VERSION ""

NS_ :

BS_:

BU_: WCM VPM VLM VKM UVM TIM TEST_TOOL_2 TEST_TOOL_1 TCP TCM TCCM3 TCCM STC SRR_SRR SRR_SLR SRR_RR SRR_RF SRR_LR_CR SRR_LF SIB SDM SCL SBZA_R SBZA_L SBM SADS RadioLow RSC RDCM PTM PDR PA NVM MTCM_R MTCM_L MSM_RR MSM_P MSM_LR MSM_D MSB2 MSB1 MRCM_R MRCM_L MFC LRR_HC LRR LIB1 IPC ICS_Info ICCM HVAC_FP_R HVAC_FP_F HUD_CAN HDLM FCM_LC FCM EPS EOCM_HCP2 EOCM_HCP1 EOCM ELM ECP_X1 ECP_MC ECP_E ECM EBCM DMS DEFC DCM CSM CMMb CMMa CGM BSM_MH BSM BCM ARS ARB APA AOS AMP ALC AHS AHL_AFL AGC

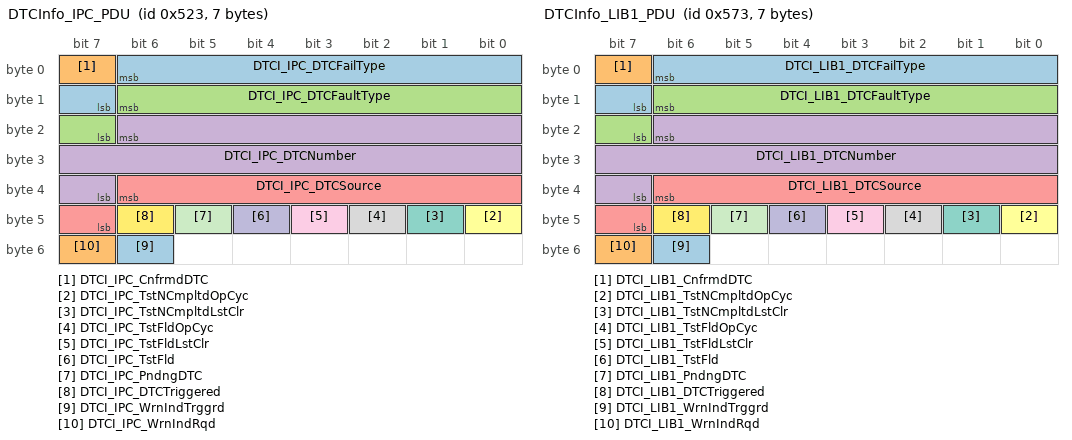
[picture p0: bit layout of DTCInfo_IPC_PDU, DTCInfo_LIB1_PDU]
BO_ 1315 DTCInfo_IPC_PDU: 7 IPC
 SG_ DTCI_IPC_DTCFailType : 6|8@0+ (1,0) [0|255] "" CSM,TCP
 SG_ DTCI_IPC_CnfrmdDTC : 7|1@0+ (1,0) [0|1] "" CSM,TCP
 SG_ DTCI_IPC_DTCFaultType : 14|8@0+ (1,0) [0|3] "" CSM,TCP
 SG_ DTCI_IPC_DTCNumber : 22|16@0+ (1,0) [0|65535] "" CSM,TCP
 SG_ DTCI_IPC_DTCSource : 38|8@0+ (1,0) [0|255] "" CGM,CSM,TCP
 SG_ DTCI_IPC_TstNCmpltdOpCyc : 40|1@0+ (1,0) [0|1] "" CSM,TCP
 SG_ DTCI_IPC_TstNCmpltdLstClr : 41|1@0+ (1,0) [0|1] "" CSM,TCP
 SG_ DTCI_IPC_TstFldOpCyc : 42|1@0+ (1,0) [0|1] "" CSM,TCP
 SG_ DTCI_IPC_TstFldLstClr : 43|1@0+ (1,0) [0|1] "" CSM,TCP
 SG_ DTCI_IPC_TstFld : 44|1@0+ (1,0) [0|1] "" CSM,TCP
 SG_ DTCI_IPC_PndngDTC : 45|1@0+ (1,0) [0|1] "" CSM,TCP
 SG_ DTCI_IPC_DTCTriggered : 46|1@0+ (1,0) [0|1] "" CSM,TCP
 SG_ DTCI_IPC_WrnIndTrggrd : 54|1@0+ (1,0) [0|1] "" CSM,TCP
 SG_ DTCI_IPC_WrnIndRqd : 55|1@0+ (1,0) [0|1] "" CSM,TCP

BO_ 1395 DTCInfo_LIB1_PDU: 7 CGM
 SG_ DTCI_LIB1_DTCFailType : 6|8@0+ (1,0) [0|255] "" CSM,TCP
 SG_ DTCI_LIB1_CnfrmdDTC : 7|1@0+ (1,0) [0|1] "" CSM,TCP
 SG_ DTCI_LIB1_DTCFaultType : 14|8@0+ (1,0) [0|3] "" CSM,TCP
 SG_ DTCI_LIB1_DTCNumber : 22|16@0+ (1,0) [0|65535] "" CSM,TCP
 SG_ DTCI_LIB1_DTCSource : 38|8@0+ (1,0) [0|255] "" CSM,TCP
 SG_ DTCI_LIB1_TstNCmpltdOpCyc : 40|1@0+ (1,0) [0|1] "" CSM,TCP
 SG_ DTCI_LIB1_TstNCmpltdLstClr : 41|1@0+ (1,0) [0|1] "" CSM,TCP
 SG_ DTCI_LIB1_TstFldOpCyc : 42|1@0+ (1,0) [0|1] "" CSM,TCP
 SG_ DTCI_LIB1_TstFldLstClr : 43|1@0+ (1,0) [0|1] "" CSM,TCP
 SG_ DTCI_LIB1_TstFld : 44|1@0+ (1,0) [0|1] "" CSM,TCP
 SG_ DTCI_LIB1_PndngDTC : 45|1@0+ (1,0) [0|1] "" CSM,TCP
 SG_ DTCI_LIB1_DTCTriggered : 46|1@0+ (1,0) [0|1] "" CSM,TCP
 SG_ DTCI_LIB1_WrnIndTrggrd : 54|1@0+ (1,0) [0|1] "" CSM,TCP
 SG_ DTCI_LIB1_WrnIndRqd : 55|1@0+ (1,0) [0|1] "" CSM,TCP

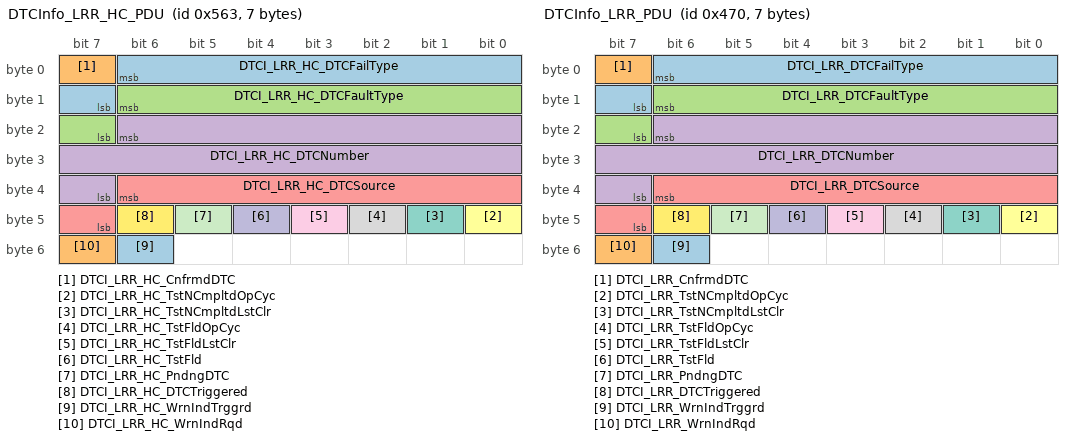
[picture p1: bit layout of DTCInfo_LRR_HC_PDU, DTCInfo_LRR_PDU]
BO_ 1379 DTCInfo_LRR_HC_PDU: 7 CGM
 SG_ DTCI_LRR_HC_DTCFailType : 6|8@0+ (1,0) [0|255] "" CSM,TCP
 SG_ DTCI_LRR_HC_CnfrmdDTC : 7|1@0+ (1,0) [0|1] "" CSM,TCP
 SG_ DTCI_LRR_HC_DTCFaultType : 14|8@0+ (1,0) [0|3] "" CSM,TCP
 SG_ DTCI_LRR_HC_DTCNumber : 22|16@0+ (1,0) [0|65535] "" CSM,TCP
 SG_ DTCI_LRR_HC_DTCSource : 38|8@0+ (1,0) [0|255] "" CSM,TCP
 SG_ DTCI_LRR_HC_TstNCmpltdOpCyc : 40|1@0+ (1,0) [0|1] "" CSM,TCP
 SG_ DTCI_LRR_HC_TstNCmpltdLstClr : 41|1@0+ (1,0) [0|1] "" CSM,TCP
 SG_ DTCI_LRR_HC_TstFldOpCyc : 42|1@0+ (1,0) [0|1] "" CSM,TCP
 SG_ DTCI_LRR_HC_TstFldLstClr : 43|1@0+ (1,0) [0|1] "" CSM,TCP
 SG_ DTCI_LRR_HC_TstFld : 44|1@0+ (1,0) [0|1] "" CSM,TCP
 SG_ DTCI_LRR_HC_PndngDTC : 45|1@0+ (1,0) [0|1] "" CSM,TCP
 SG_ DTCI_LRR_HC_DTCTriggered : 46|1@0+ (1,0) [0|1] "" CSM,TCP
 SG_ DTCI_LRR_HC_WrnIndTrggrd : 54|1@0+ (1,0) [0|1] "" TCP
 SG_ DTCI_LRR_HC_WrnIndRqd : 55|1@0+ (1,0) [0|1] "" TCP

BO_ 1136 DTCInfo_LRR_PDU: 7 CGM
 SG_ DTCI_LRR_DTCFailType : 6|8@0+ (1,0) [0|255] "" CSM,TCP
 SG_ DTCI_LRR_CnfrmdDTC : 7|1@0+ (1,0) [0|1] "" CSM,TCP
 SG_ DTCI_LRR_DTCFaultType : 14|8@0+ (1,0) [0|3] "" CSM,TCP
 SG_ DTCI_LRR_DTCNumber : 22|16@0+ (1,0) [0|65535] "" CSM,TCP
 SG_ DTCI_LRR_DTCSource : 38|8@0+ (1,0) [0|255] "" CSM,TCP
 SG_ DTCI_LRR_TstNCmpltdOpCyc : 40|1@0+ (1,0) [0|1] "" CSM,TCP
 SG_ DTCI_LRR_TstNCmpltdLstClr : 41|1@0+ (1,0) [0|1] "" CSM,TCP
 SG_ DTCI_LRR_TstFldOpCyc : 42|1@0+ (1,0) [0|1] "" CSM,TCP
 SG_ DTCI_LRR_TstFldLstClr : 43|1@0+ (1,0) [0|1] "" CSM,TCP
 SG_ DTCI_LRR_TstFld : 44|1@0+ (1,0) [0|1] "" CSM,TCP
 SG_ DTCI_LRR_PndngDTC : 45|1@0+ (1,0) [0|1] "" CSM,TCP
 SG_ DTCI_LRR_DTCTriggered : 46|1@0+ (1,0) [0|1] "" CSM,TCP
 SG_ DTCI_LRR_WrnIndTrggrd : 54|1@0+ (1,0) [0|1] "" CSM,TCP
 SG_ DTCI_LRR_WrnIndRqd : 55|1@0+ (1,0) [0|1] "" CSM,TCP

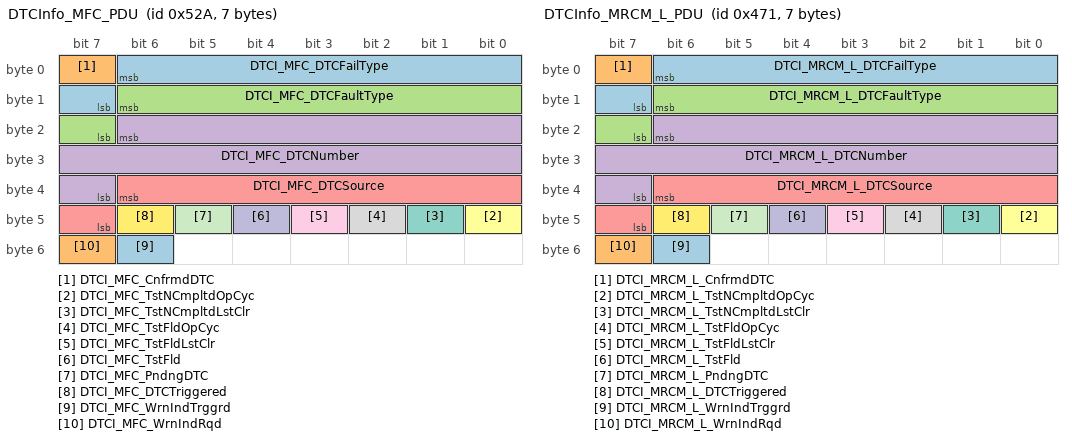
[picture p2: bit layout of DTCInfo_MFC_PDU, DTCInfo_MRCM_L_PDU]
BO_ 1322 DTCInfo_MFC_PDU: 7 MFC
 SG_ DTCI_MFC_DTCFailType : 6|8@0+ (1,0) [0|255] "" CSM,TCP
 SG_ DTCI_MFC_CnfrmdDTC : 7|1@0+ (1,0) [0|1] "" CSM,TCP
 SG_ DTCI_MFC_DTCFaultType : 14|8@0+ (1,0) [0|3] "" CSM,TCP
 SG_ DTCI_MFC_DTCNumber : 22|16@0+ (1,0) [0|65535] "" CSM,TCP
 SG_ DTCI_MFC_DTCSource : 38|8@0+ (1,0) [0|255] "" CGM,CSM,TCP
 SG_ DTCI_MFC_TstNCmpltdOpCyc : 40|1@0+ (1,0) [0|1] "" CSM,TCP
 SG_ DTCI_MFC_TstNCmpltdLstClr : 41|1@0+ (1,0) [0|1] "" CSM,TCP
 SG_ DTCI_MFC_TstFldOpCyc : 42|1@0+ (1,0) [0|1] "" CSM,TCP
 SG_ DTCI_MFC_TstFldLstClr : 43|1@0+ (1,0) [0|1] "" CSM,TCP
 SG_ DTCI_MFC_TstFld : 44|1@0+ (1,0) [0|1] "" CSM,TCP
 SG_ DTCI_MFC_PndngDTC : 45|1@0+ (1,0) [0|1] "" CSM,TCP
 SG_ DTCI_MFC_DTCTriggered : 46|1@0+ (1,0) [0|1] "" CSM,TCP
 SG_ DTCI_MFC_WrnIndTrggrd : 54|1@0+ (1,0) [0|1] "" CSM,TCP
 SG_ DTCI_MFC_WrnIndRqd : 55|1@0+ (1,0) [0|1] "" CSM,TCP

BO_ 1137 DTCInfo_MRCM_L_PDU: 7 CGM
 SG_ DTCI_MRCM_L_DTCFailType : 6|8@0+ (1,0) [0|255] "" CSM,TCP
 SG_ DTCI_MRCM_L_CnfrmdDTC : 7|1@0+ (1,0) [0|1] "" CSM,TCP
 SG_ DTCI_MRCM_L_DTCFaultType : 14|8@0+ (1,0) [0|3] "" CSM,TCP
 SG_ DTCI_MRCM_L_DTCNumber : 22|16@0+ (1,0) [0|65535] "" CSM,TCP
 SG_ DTCI_MRCM_L_DTCSource : 38|8@0+ (1,0) [0|255] "" CSM,TCP
 SG_ DTCI_MRCM_L_TstNCmpltdOpCyc : 40|1@0+ (1,0) [0|1] "" CSM,TCP
 SG_ DTCI_MRCM_L_TstNCmpltdLstClr : 41|1@0+ (1,0) [0|1] "" CSM,TCP
 SG_ DTCI_MRCM_L_TstFldOpCyc : 42|1@0+ (1,0) [0|1] "" CSM,TCP
 SG_ DTCI_MRCM_L_TstFldLstClr : 43|1@0+ (1,0) [0|1] "" CSM,TCP
 SG_ DTCI_MRCM_L_TstFld : 44|1@0+ (1,0) [0|1] "" CSM,TCP
 SG_ DTCI_MRCM_L_PndngDTC : 45|1@0+ (1,0) [0|1] "" CSM,TCP
 SG_ DTCI_MRCM_L_DTCTriggered : 46|1@0+ (1,0) [0|1] "" CSM,TCP
 SG_ DTCI_MRCM_L_WrnIndTrggrd : 54|1@0+ (1,0) [0|1] "" CSM,TCP
 SG_ DTCI_MRCM_L_WrnIndRqd : 55|1@0+ (1,0) [0|1] "" CSM,TCP

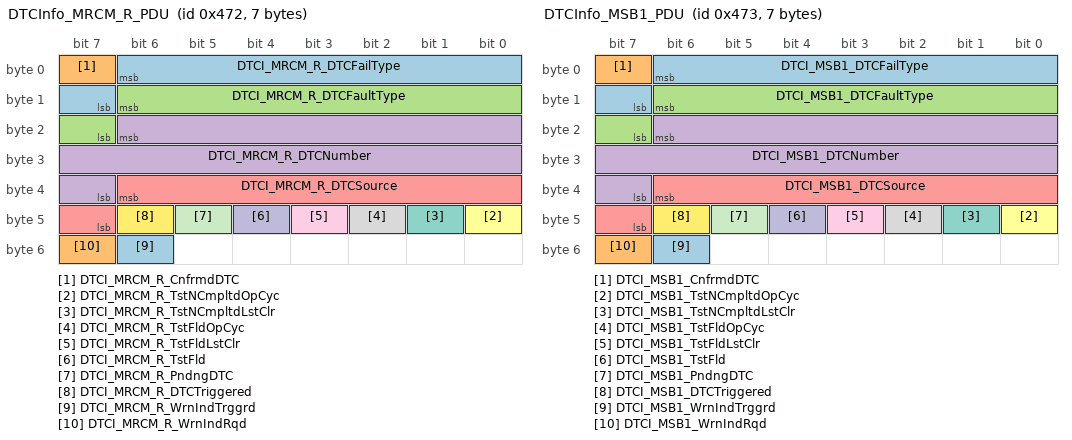
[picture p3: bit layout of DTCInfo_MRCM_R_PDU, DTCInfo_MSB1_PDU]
BO_ 1138 DTCInfo_MRCM_R_PDU: 7 CGM
 SG_ DTCI_MRCM_R_DTCFailType : 6|8@0+ (1,0) [0|255] "" CSM,TCP
 SG_ DTCI_MRCM_R_CnfrmdDTC : 7|1@0+ (1,0) [0|1] "" CSM,TCP
 SG_ DTCI_MRCM_R_DTCFaultType : 14|8@0+ (1,0) [0|3] "" CSM,TCP
 SG_ DTCI_MRCM_R_DTCNumber : 22|16@0+ (1,0) [0|65535] "" CSM,TCP
 SG_ DTCI_MRCM_R_DTCSource : 38|8@0+ (1,0) [0|255] "" CSM,TCP
 SG_ DTCI_MRCM_R_TstNCmpltdOpCyc : 40|1@0+ (1,0) [0|1] "" CSM,TCP
 SG_ DTCI_MRCM_R_TstNCmpltdLstClr : 41|1@0+ (1,0) [0|1] "" CSM,TCP
 SG_ DTCI_MRCM_R_TstFldOpCyc : 42|1@0+ (1,0) [0|1] "" CSM,TCP
 SG_ DTCI_MRCM_R_TstFldLstClr : 43|1@0+ (1,0) [0|1] "" CSM,TCP
 SG_ DTCI_MRCM_R_TstFld : 44|1@0+ (1,0) [0|1] "" CSM,TCP
 SG_ DTCI_MRCM_R_PndngDTC : 45|1@0+ (1,0) [0|1] "" CSM,TCP
 SG_ DTCI_MRCM_R_DTCTriggered : 46|1@0+ (1,0) [0|1] "" CSM,TCP
 SG_ DTCI_MRCM_R_WrnIndTrggrd : 54|1@0+ (1,0) [0|1] "" CSM,TCP
 SG_ DTCI_MRCM_R_WrnIndRqd : 55|1@0+ (1,0) [0|1] "" CSM,TCP

BO_ 1139 DTCInfo_MSB1_PDU: 7 CGM
 SG_ DTCI_MSB1_DTCFailType : 6|8@0+ (1,0) [0|255] "" CSM,TCP
 SG_ DTCI_MSB1_CnfrmdDTC : 7|1@0+ (1,0) [0|1] "" CSM,TCP
 SG_ DTCI_MSB1_DTCFaultType : 14|8@0+ (1,0) [0|3] "" CSM,TCP
 SG_ DTCI_MSB1_DTCNumber : 22|16@0+ (1,0) [0|65535] "" CSM,TCP
 SG_ DTCI_MSB1_DTCSource : 38|8@0+ (1,0) [0|255] "" CSM,TCP
 SG_ DTCI_MSB1_TstNCmpltdOpCyc : 40|1@0+ (1,0) [0|1] "" CSM,TCP
 SG_ DTCI_MSB1_TstNCmpltdLstClr : 41|1@0+ (1,0) [0|1] "" CSM,TCP
 SG_ DTCI_MSB1_TstFldOpCyc : 42|1@0+ (1,0) [0|1] "" CSM,TCP
 SG_ DTCI_MSB1_TstFldLstClr : 43|1@0+ (1,0) [0|1] "" CSM,TCP
 SG_ DTCI_MSB1_TstFld : 44|1@0+ (1,0) [0|1] "" CSM,TCP
 SG_ DTCI_MSB1_PndngDTC : 45|1@0+ (1,0) [0|1] "" CSM,TCP
 SG_ DTCI_MSB1_DTCTriggered : 46|1@0+ (1,0) [0|1] "" CSM,TCP
 SG_ DTCI_MSB1_WrnIndTrggrd : 54|1@0+ (1,0) [0|1] "" CSM,TCP
 SG_ DTCI_MSB1_WrnIndRqd : 55|1@0+ (1,0) [0|1] "" CSM,TCP

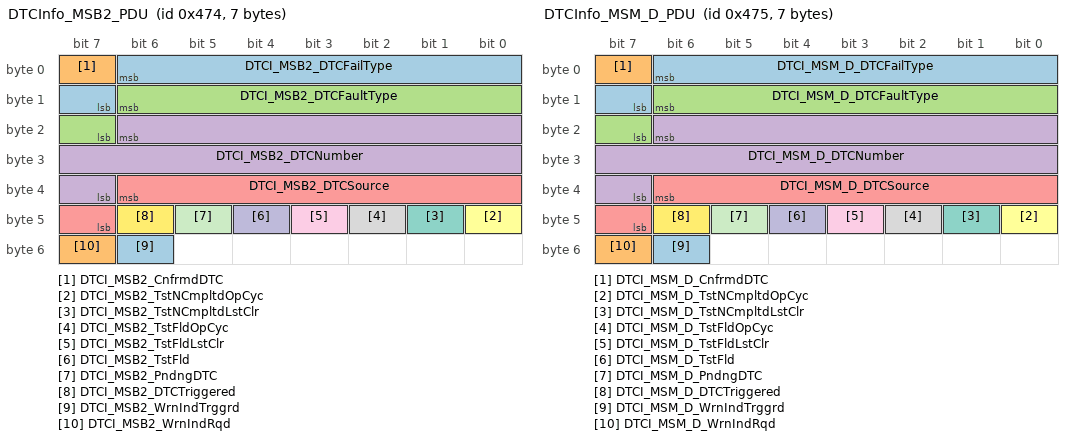
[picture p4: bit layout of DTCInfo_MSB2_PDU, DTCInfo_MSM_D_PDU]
BO_ 1140 DTCInfo_MSB2_PDU: 7 CGM
 SG_ DTCI_MSB2_DTCFailType : 6|8@0+ (1,0) [0|255] "" CSM,TCP
 SG_ DTCI_MSB2_CnfrmdDTC : 7|1@0+ (1,0) [0|1] "" CSM,TCP
 SG_ DTCI_MSB2_DTCFaultType : 14|8@0+ (1,0) [0|3] "" CSM,TCP
 SG_ DTCI_MSB2_DTCNumber : 22|16@0+ (1,0) [0|65535] "" CSM,TCP
 SG_ DTCI_MSB2_DTCSource : 38|8@0+ (1,0) [0|255] "" CSM,TCP
 SG_ DTCI_MSB2_TstNCmpltdOpCyc : 40|1@0+ (1,0) [0|1] "" CSM,TCP
 SG_ DTCI_MSB2_TstNCmpltdLstClr : 41|1@0+ (1,0) [0|1] "" CSM,TCP
 SG_ DTCI_MSB2_TstFldOpCyc : 42|1@0+ (1,0) [0|1] "" CSM,TCP
 SG_ DTCI_MSB2_TstFldLstClr : 43|1@0+ (1,0) [0|1] "" CSM,TCP
 SG_ DTCI_MSB2_TstFld : 44|1@0+ (1,0) [0|1] "" CSM,TCP
 SG_ DTCI_MSB2_PndngDTC : 45|1@0+ (1,0) [0|1] "" CSM,TCP
 SG_ DTCI_MSB2_DTCTriggered : 46|1@0+ (1,0) [0|1] "" CSM,TCP
 SG_ DTCI_MSB2_WrnIndTrggrd : 54|1@0+ (1,0) [0|1] "" CSM,TCP
 SG_ DTCI_MSB2_WrnIndRqd : 55|1@0+ (1,0) [0|1] "" CSM,TCP

BO_ 1141 DTCInfo_MSM_D_PDU: 7 CGM
 SG_ DTCI_MSM_D_DTCFailType : 6|8@0+ (1,0) [0|255] "" CSM,TCP
 SG_ DTCI_MSM_D_CnfrmdDTC : 7|1@0+ (1,0) [0|1] "" CSM,TCP
 SG_ DTCI_MSM_D_DTCFaultType : 14|8@0+ (1,0) [0|3] "" CSM,TCP
 SG_ DTCI_MSM_D_DTCNumber : 22|16@0+ (1,0) [0|65535] "" CSM,TCP
 SG_ DTCI_MSM_D_DTCSource : 38|8@0+ (1,0) [0|255] "" CSM,TCP
 SG_ DTCI_MSM_D_TstNCmpltdOpCyc : 40|1@0+ (1,0) [0|1] "" CSM,TCP
 SG_ DTCI_MSM_D_TstNCmpltdLstClr : 41|1@0+ (1,0) [0|1] "" CSM,TCP
 SG_ DTCI_MSM_D_TstFldOpCyc : 42|1@0+ (1,0) [0|1] "" CSM,TCP
 SG_ DTCI_MSM_D_TstFldLstClr : 43|1@0+ (1,0) [0|1] "" CSM,TCP
 SG_ DTCI_MSM_D_TstFld : 44|1@0+ (1,0) [0|1] "" CSM,TCP
 SG_ DTCI_MSM_D_PndngDTC : 45|1@0+ (1,0) [0|1] "" CSM,TCP
 SG_ DTCI_MSM_D_DTCTriggered : 46|1@0+ (1,0) [0|1] "" CSM,TCP
 SG_ DTCI_MSM_D_WrnIndTrggrd : 54|1@0+ (1,0) [0|1] "" CSM,TCP
 SG_ DTCI_MSM_D_WrnIndRqd : 55|1@0+ (1,0) [0|1] "" CSM,TCP

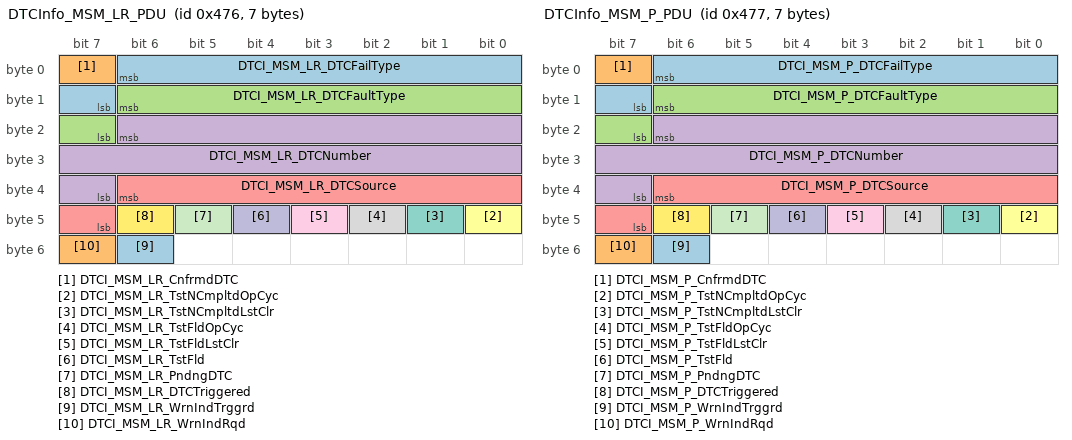
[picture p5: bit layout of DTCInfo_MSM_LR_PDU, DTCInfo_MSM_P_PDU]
BO_ 1142 DTCInfo_MSM_LR_PDU: 7 CGM
 SG_ DTCI_MSM_LR_DTCFailType : 6|8@0+ (1,0) [0|255] "" CSM,TCP
 SG_ DTCI_MSM_LR_CnfrmdDTC : 7|1@0+ (1,0) [0|1] "" CSM,TCP
 SG_ DTCI_MSM_LR_DTCFaultType : 14|8@0+ (1,0) [0|3] "" CSM,TCP
 SG_ DTCI_MSM_LR_DTCNumber : 22|16@0+ (1,0) [0|65535] "" CSM,TCP
 SG_ DTCI_MSM_LR_DTCSource : 38|8@0+ (1,0) [0|255] "" CSM,TCP
 SG_ DTCI_MSM_LR_TstNCmpltdOpCyc : 40|1@0+ (1,0) [0|1] "" CSM,TCP
 SG_ DTCI_MSM_LR_TstNCmpltdLstClr : 41|1@0+ (1,0) [0|1] "" CSM,TCP
 SG_ DTCI_MSM_LR_TstFldOpCyc : 42|1@0+ (1,0) [0|1] "" CSM,TCP
 SG_ DTCI_MSM_LR_TstFldLstClr : 43|1@0+ (1,0) [0|1] "" CSM,TCP
 SG_ DTCI_MSM_LR_TstFld : 44|1@0+ (1,0) [0|1] "" CSM,TCP
 SG_ DTCI_MSM_LR_PndngDTC : 45|1@0+ (1,0) [0|1] "" CSM,TCP
 SG_ DTCI_MSM_LR_DTCTriggered : 46|1@0+ (1,0) [0|1] "" CSM,TCP
 SG_ DTCI_MSM_LR_WrnIndTrggrd : 54|1@0+ (1,0) [0|1] "" CSM,TCP
 SG_ DTCI_MSM_LR_WrnIndRqd : 55|1@0+ (1,0) [0|1] "" CSM,TCP

BO_ 1143 DTCInfo_MSM_P_PDU: 7 CGM
 SG_ DTCI_MSM_P_DTCFailType : 6|8@0+ (1,0) [0|255] "" CSM,TCP
 SG_ DTCI_MSM_P_CnfrmdDTC : 7|1@0+ (1,0) [0|1] "" CSM,TCP
 SG_ DTCI_MSM_P_DTCFaultType : 14|8@0+ (1,0) [0|3] "" CSM,TCP
 SG_ DTCI_MSM_P_DTCNumber : 22|16@0+ (1,0) [0|65535] "" CSM,TCP
 SG_ DTCI_MSM_P_DTCSource : 38|8@0+ (1,0) [0|255] "" CSM,TCP
 SG_ DTCI_MSM_P_TstNCmpltdOpCyc : 40|1@0+ (1,0) [0|1] "" CSM,TCP
 SG_ DTCI_MSM_P_TstNCmpltdLstClr : 41|1@0+ (1,0) [0|1] "" CSM,TCP
 SG_ DTCI_MSM_P_TstFldOpCyc : 42|1@0+ (1,0) [0|1] "" CSM,TCP
 SG_ DTCI_MSM_P_TstFldLstClr : 43|1@0+ (1,0) [0|1] "" CSM,TCP
 SG_ DTCI_MSM_P_TstFld : 44|1@0+ (1,0) [0|1] "" CSM,TCP
 SG_ DTCI_MSM_P_PndngDTC : 45|1@0+ (1,0) [0|1] "" CSM,TCP
 SG_ DTCI_MSM_P_DTCTriggered : 46|1@0+ (1,0) [0|1] "" CSM,TCP
 SG_ DTCI_MSM_P_WrnIndTrggrd : 54|1@0+ (1,0) [0|1] "" CSM,TCP
 SG_ DTCI_MSM_P_WrnIndRqd : 55|1@0+ (1,0) [0|1] "" CSM,TCP

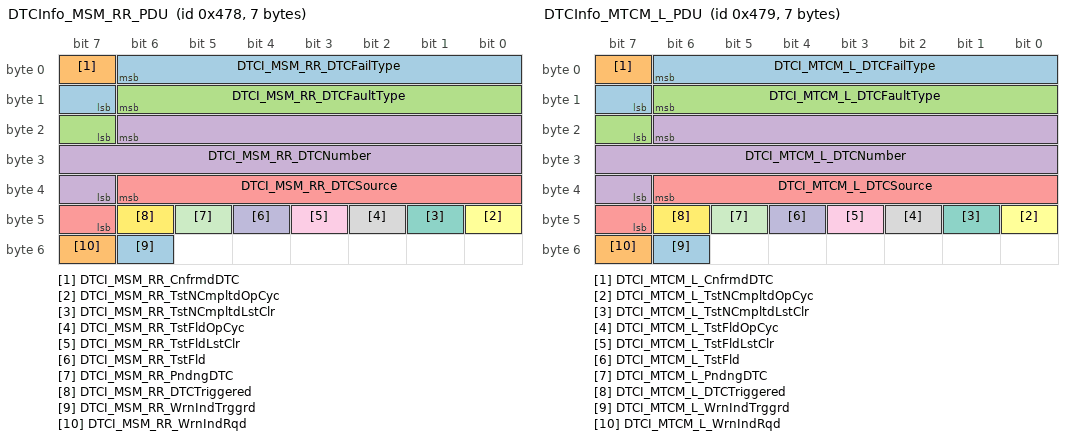
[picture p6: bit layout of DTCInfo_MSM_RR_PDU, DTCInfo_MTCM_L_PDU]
BO_ 1144 DTCInfo_MSM_RR_PDU: 7 CGM
 SG_ DTCI_MSM_RR_DTCFailType : 6|8@0+ (1,0) [0|255] "" CSM,TCP
 SG_ DTCI_MSM_RR_CnfrmdDTC : 7|1@0+ (1,0) [0|1] "" CSM,TCP
 SG_ DTCI_MSM_RR_DTCFaultType : 14|8@0+ (1,0) [0|3] "" CSM,TCP
 SG_ DTCI_MSM_RR_DTCNumber : 22|16@0+ (1,0) [0|65535] "" CSM,TCP
 SG_ DTCI_MSM_RR_DTCSource : 38|8@0+ (1,0) [0|255] "" CSM,TCP
 SG_ DTCI_MSM_RR_TstNCmpltdOpCyc : 40|1@0+ (1,0) [0|1] "" CSM,TCP
 SG_ DTCI_MSM_RR_TstNCmpltdLstClr : 41|1@0+ (1,0) [0|1] "" CSM,TCP
 SG_ DTCI_MSM_RR_TstFldOpCyc : 42|1@0+ (1,0) [0|1] "" CSM,TCP
 SG_ DTCI_MSM_RR_TstFldLstClr : 43|1@0+ (1,0) [0|1] "" CSM,TCP
 SG_ DTCI_MSM_RR_TstFld : 44|1@0+ (1,0) [0|1] "" CSM,TCP
 SG_ DTCI_MSM_RR_PndngDTC : 45|1@0+ (1,0) [0|1] "" CSM,TCP
 SG_ DTCI_MSM_RR_DTCTriggered : 46|1@0+ (1,0) [0|1] "" CSM,TCP
 SG_ DTCI_MSM_RR_WrnIndTrggrd : 54|1@0+ (1,0) [0|1] "" CSM,TCP
 SG_ DTCI_MSM_RR_WrnIndRqd : 55|1@0+ (1,0) [0|1] "" CSM,TCP

BO_ 1145 DTCInfo_MTCM_L_PDU: 7 CGM
 SG_ DTCI_MTCM_L_DTCFailType : 6|8@0+ (1,0) [0|255] "" CSM,TCP
 SG_ DTCI_MTCM_L_CnfrmdDTC : 7|1@0+ (1,0) [0|1] "" CSM,TCP
 SG_ DTCI_MTCM_L_DTCFaultType : 14|8@0+ (1,0) [0|3] "" CSM,TCP
 SG_ DTCI_MTCM_L_DTCNumber : 22|16@0+ (1,0) [0|65535] "" CSM,TCP
 SG_ DTCI_MTCM_L_DTCSource : 38|8@0+ (1,0) [0|255] "" CSM,TCP
 SG_ DTCI_MTCM_L_TstNCmpltdOpCyc : 40|1@0+ (1,0) [0|1] "" CSM,TCP
 SG_ DTCI_MTCM_L_TstNCmpltdLstClr : 41|1@0+ (1,0) [0|1] "" CSM,TCP
 SG_ DTCI_MTCM_L_TstFldOpCyc : 42|1@0+ (1,0) [0|1] "" CSM,TCP
 SG_ DTCI_MTCM_L_TstFldLstClr : 43|1@0+ (1,0) [0|1] "" CSM,TCP
 SG_ DTCI_MTCM_L_TstFld : 44|1@0+ (1,0) [0|1] "" CSM,TCP
 SG_ DTCI_MTCM_L_PndngDTC : 45|1@0+ (1,0) [0|1] "" CSM,TCP
 SG_ DTCI_MTCM_L_DTCTriggered : 46|1@0+ (1,0) [0|1] "" CSM,TCP
 SG_ DTCI_MTCM_L_WrnIndTrggrd : 54|1@0+ (1,0) [0|1] "" CSM,TCP
 SG_ DTCI_MTCM_L_WrnIndRqd : 55|1@0+ (1,0) [0|1] "" CSM,TCP

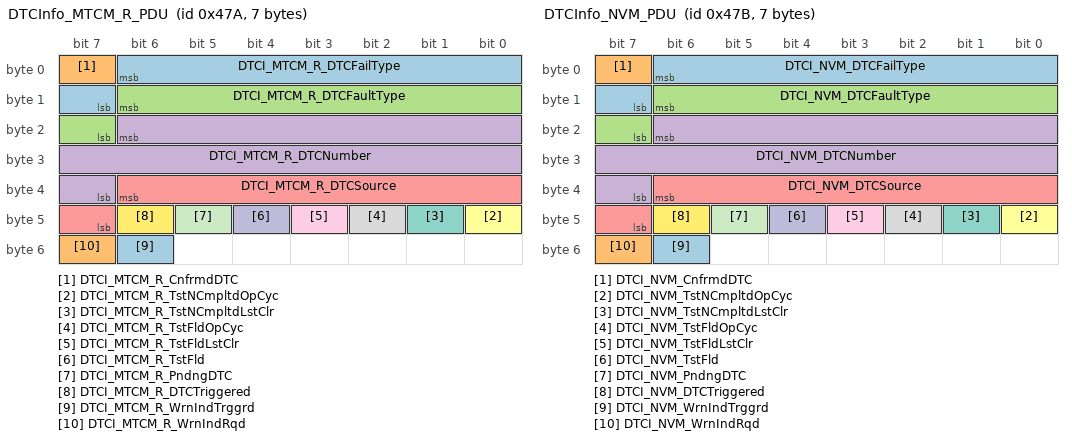
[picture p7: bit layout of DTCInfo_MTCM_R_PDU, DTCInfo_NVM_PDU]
BO_ 1146 DTCInfo_MTCM_R_PDU: 7 CGM
 SG_ DTCI_MTCM_R_DTCFailType : 6|8@0+ (1,0) [0|255] "" CSM,TCP
 SG_ DTCI_MTCM_R_CnfrmdDTC : 7|1@0+ (1,0) [0|1] "" CSM,TCP
 SG_ DTCI_MTCM_R_DTCFaultType : 14|8@0+ (1,0) [0|3] "" CSM,TCP
 SG_ DTCI_MTCM_R_DTCNumber : 22|16@0+ (1,0) [0|65535] "" CSM,TCP
 SG_ DTCI_MTCM_R_DTCSource : 38|8@0+ (1,0) [0|255] "" CSM,TCP
 SG_ DTCI_MTCM_R_TstNCmpltdOpCyc : 40|1@0+ (1,0) [0|1] "" CSM,TCP
 SG_ DTCI_MTCM_R_TstNCmpltdLstClr : 41|1@0+ (1,0) [0|1] "" CSM,TCP
 SG_ DTCI_MTCM_R_TstFldOpCyc : 42|1@0+ (1,0) [0|1] "" CSM,TCP
 SG_ DTCI_MTCM_R_TstFldLstClr : 43|1@0+ (1,0) [0|1] "" CSM,TCP
 SG_ DTCI_MTCM_R_TstFld : 44|1@0+ (1,0) [0|1] "" CSM,TCP
 SG_ DTCI_MTCM_R_PndngDTC : 45|1@0+ (1,0) [0|1] "" CSM,TCP
 SG_ DTCI_MTCM_R_DTCTriggered : 46|1@0+ (1,0) [0|1] "" CSM,TCP
 SG_ DTCI_MTCM_R_WrnIndTrggrd : 54|1@0+ (1,0) [0|1] "" CSM,TCP
 SG_ DTCI_MTCM_R_WrnIndRqd : 55|1@0+ (1,0) [0|1] "" CSM,TCP

BO_ 1147 DTCInfo_NVM_PDU: 7 CGM
 SG_ DTCI_NVM_DTCFailType : 6|8@0+ (1,0) [0|255] "" CSM,TCP
 SG_ DTCI_NVM_CnfrmdDTC : 7|1@0+ (1,0) [0|1] "" CSM,TCP
 SG_ DTCI_NVM_DTCFaultType : 14|8@0+ (1,0) [0|3] "" CSM,TCP
 SG_ DTCI_NVM_DTCNumber : 22|16@0+ (1,0) [0|65535] "" CSM,TCP
 SG_ DTCI_NVM_DTCSource : 38|8@0+ (1,0) [0|255] "" CSM,TCP
 SG_ DTCI_NVM_TstNCmpltdOpCyc : 40|1@0+ (1,0) [0|1] "" CSM,TCP
 SG_ DTCI_NVM_TstNCmpltdLstClr : 41|1@0+ (1,0) [0|1] "" CSM,TCP
 SG_ DTCI_NVM_TstFldOpCyc : 42|1@0+ (1,0) [0|1] "" CSM,TCP
 SG_ DTCI_NVM_TstFldLstClr : 43|1@0+ (1,0) [0|1] "" CSM,TCP
 SG_ DTCI_NVM_TstFld : 44|1@0+ (1,0) [0|1] "" CSM,TCP
 SG_ DTCI_NVM_PndngDTC : 45|1@0+ (1,0) [0|1] "" CSM,TCP
 SG_ DTCI_NVM_DTCTriggered : 46|1@0+ (1,0) [0|1] "" CSM,TCP
 SG_ DTCI_NVM_WrnIndTrggrd : 54|1@0+ (1,0) [0|1] "" CSM,TCP
 SG_ DTCI_NVM_WrnIndRqd : 55|1@0+ (1,0) [0|1] "" CSM,TCP

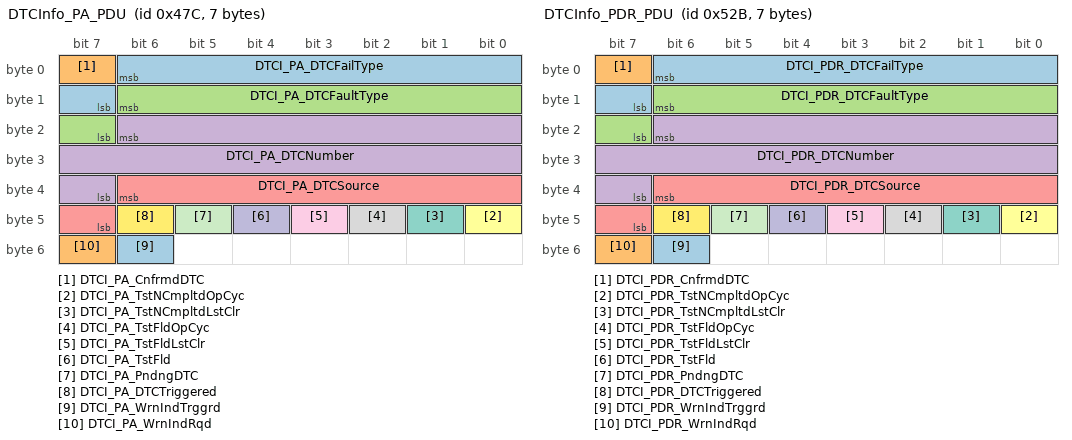
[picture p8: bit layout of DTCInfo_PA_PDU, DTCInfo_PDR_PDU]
BO_ 1148 DTCInfo_PA_PDU: 7 CGM
 SG_ DTCI_PA_DTCFailType : 6|8@0+ (1,0) [0|255] "" CSM,TCP
 SG_ DTCI_PA_CnfrmdDTC : 7|1@0+ (1,0) [0|1] "" CSM,TCP
 SG_ DTCI_PA_DTCFaultType : 14|8@0+ (1,0) [0|3] "" CSM,TCP
 SG_ DTCI_PA_DTCNumber : 22|16@0+ (1,0) [0|65535] "" CSM,TCP
 SG_ DTCI_PA_DTCSource : 38|8@0+ (1,0) [0|255] "" CSM,TCP
 SG_ DTCI_PA_TstNCmpltdOpCyc : 40|1@0+ (1,0) [0|1] "" CSM,TCP
 SG_ DTCI_PA_TstNCmpltdLstClr : 41|1@0+ (1,0) [0|1] "" CSM,TCP
 SG_ DTCI_PA_TstFldOpCyc : 42|1@0+ (1,0) [0|1] "" CSM,TCP
 SG_ DTCI_PA_TstFldLstClr : 43|1@0+ (1,0) [0|1] "" CSM,TCP
 SG_ DTCI_PA_TstFld : 44|1@0+ (1,0) [0|1] "" CSM,TCP
 SG_ DTCI_PA_PndngDTC : 45|1@0+ (1,0) [0|1] "" CSM,TCP
 SG_ DTCI_PA_DTCTriggered : 46|1@0+ (1,0) [0|1] "" CSM,TCP
 SG_ DTCI_PA_WrnIndTrggrd : 54|1@0+ (1,0) [0|1] "" CSM,TCP
 SG_ DTCI_PA_WrnIndRqd : 55|1@0+ (1,0) [0|1] "" CSM,TCP

BO_ 1323 DTCInfo_PDR_PDU: 7 PDR
 SG_ DTCI_PDR_DTCFailType : 6|8@0+ (1,0) [0|255] "" CSM,TCP
 SG_ DTCI_PDR_CnfrmdDTC : 7|1@0+ (1,0) [0|1] "" CSM,TCP
 SG_ DTCI_PDR_DTCFaultType : 14|8@0+ (1,0) [0|3] "" CSM,TCP
 SG_ DTCI_PDR_DTCNumber : 22|16@0+ (1,0) [0|65535] "" CSM,TCP
 SG_ DTCI_PDR_DTCSource : 38|8@0+ (1,0) [0|255] "" CGM,CSM,TCP
 SG_ DTCI_PDR_TstNCmpltdOpCyc : 40|1@0+ (1,0) [0|1] "" CSM,TCP
 SG_ DTCI_PDR_TstNCmpltdLstClr : 41|1@0+ (1,0) [0|1] "" CSM,TCP
 SG_ DTCI_PDR_TstFldOpCyc : 42|1@0+ (1,0) [0|1] "" CSM,TCP
 SG_ DTCI_PDR_TstFldLstClr : 43|1@0+ (1,0) [0|1] "" CSM,TCP
 SG_ DTCI_PDR_TstFld : 44|1@0+ (1,0) [0|1] "" CSM,TCP
 SG_ DTCI_PDR_PndngDTC : 45|1@0+ (1,0) [0|1] "" CSM,TCP
 SG_ DTCI_PDR_DTCTriggered : 46|1@0+ (1,0) [0|1] "" CSM,TCP
 SG_ DTCI_PDR_WrnIndTrggrd : 54|1@0+ (1,0) [0|1] "" CSM,TCP
 SG_ DTCI_PDR_WrnIndRqd : 55|1@0+ (1,0) [0|1] "" CSM,TCP

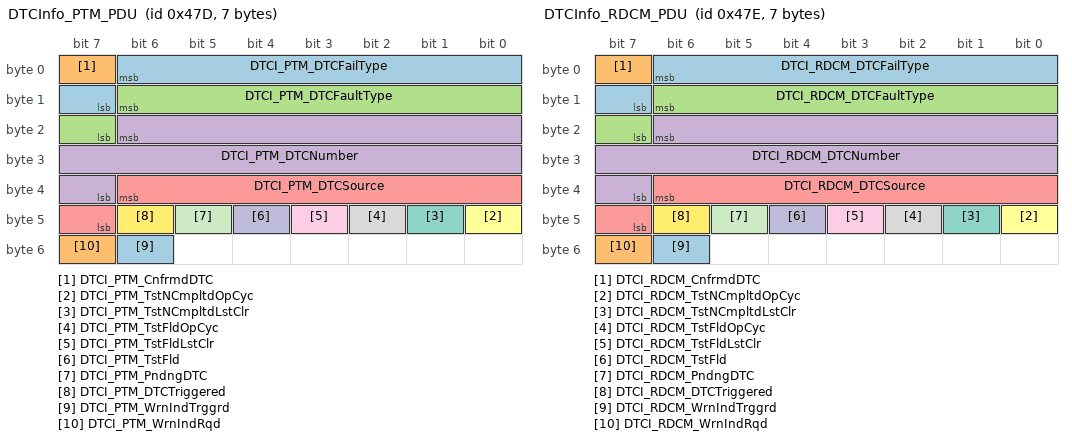
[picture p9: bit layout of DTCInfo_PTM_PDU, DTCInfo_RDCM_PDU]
BO_ 1149 DTCInfo_PTM_PDU: 7 CGM
 SG_ DTCI_PTM_DTCFailType : 6|8@0+ (1,0) [0|255] "" CSM,TCP
 SG_ DTCI_PTM_CnfrmdDTC : 7|1@0+ (1,0) [0|1] "" CSM,TCP
 SG_ DTCI_PTM_DTCFaultType : 14|8@0+ (1,0) [0|3] "" CSM,TCP
 SG_ DTCI_PTM_DTCNumber : 22|16@0+ (1,0) [0|65535] "" CSM,TCP
 SG_ DTCI_PTM_DTCSource : 38|8@0+ (1,0) [0|255] "" CSM,TCP
 SG_ DTCI_PTM_TstNCmpltdOpCyc : 40|1@0+ (1,0) [0|1] "" CSM,TCP
 SG_ DTCI_PTM_TstNCmpltdLstClr : 41|1@0+ (1,0) [0|1] "" CSM,TCP
 SG_ DTCI_PTM_TstFldOpCyc : 42|1@0+ (1,0) [0|1] "" CSM,TCP
 SG_ DTCI_PTM_TstFldLstClr : 43|1@0+ (1,0) [0|1] "" CSM,TCP
 SG_ DTCI_PTM_TstFld : 44|1@0+ (1,0) [0|1] "" CSM,TCP
 SG_ DTCI_PTM_PndngDTC : 45|1@0+ (1,0) [0|1] "" CSM,TCP
 SG_ DTCI_PTM_DTCTriggered : 46|1@0+ (1,0) [0|1] "" CSM,TCP
 SG_ DTCI_PTM_WrnIndTrggrd : 54|1@0+ (1,0) [0|1] "" CSM,TCP
 SG_ DTCI_PTM_WrnIndRqd : 55|1@0+ (1,0) [0|1] "" CSM,TCP

BO_ 1150 DTCInfo_RDCM_PDU: 7 CGM
 SG_ DTCI_RDCM_DTCFailType : 6|8@0+ (1,0) [0|255] "" CSM,TCP
 SG_ DTCI_RDCM_CnfrmdDTC : 7|1@0+ (1,0) [0|1] "" CSM,TCP
 SG_ DTCI_RDCM_DTCFaultType : 14|8@0+ (1,0) [0|3] "" CSM,TCP
 SG_ DTCI_RDCM_DTCNumber : 22|16@0+ (1,0) [0|65535] "" CSM,TCP
 SG_ DTCI_RDCM_DTCSource : 38|8@0+ (1,0) [0|255] "" CSM,TCP
 SG_ DTCI_RDCM_TstNCmpltdOpCyc : 40|1@0+ (1,0) [0|1] "" CSM,TCP
 SG_ DTCI_RDCM_TstNCmpltdLstClr : 41|1@0+ (1,0) [0|1] "" CSM,TCP
 SG_ DTCI_RDCM_TstFldOpCyc : 42|1@0+ (1,0) [0|1] "" CSM,TCP
 SG_ DTCI_RDCM_TstFldLstClr : 43|1@0+ (1,0) [0|1] "" CSM,TCP
 SG_ DTCI_RDCM_TstFld : 44|1@0+ (1,0) [0|1] "" CSM,TCP
 SG_ DTCI_RDCM_PndngDTC : 45|1@0+ (1,0) [0|1] "" CSM,TCP
 SG_ DTCI_RDCM_DTCTriggered : 46|1@0+ (1,0) [0|1] "" CSM,TCP
 SG_ DTCI_RDCM_WrnIndTrggrd : 54|1@0+ (1,0) [0|1] "" CSM,TCP
 SG_ DTCI_RDCM_WrnIndRqd : 55|1@0+ (1,0) [0|1] "" CSM,TCP

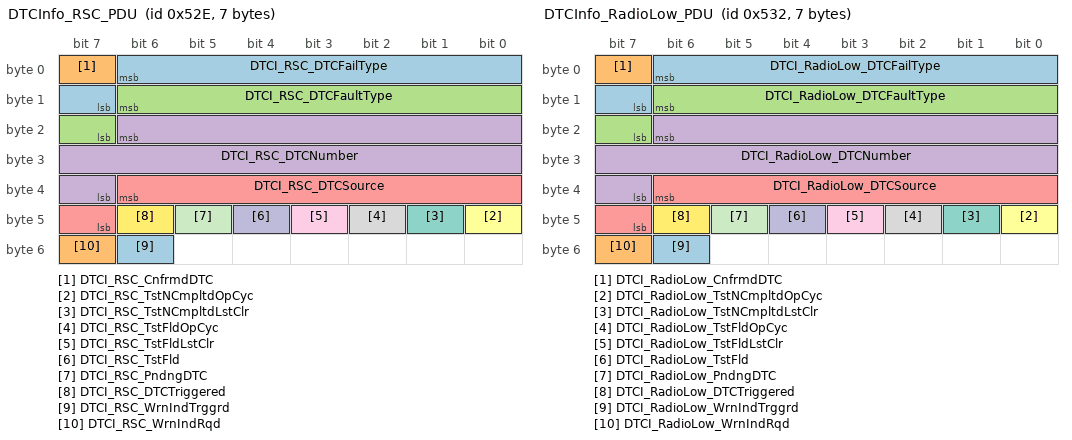
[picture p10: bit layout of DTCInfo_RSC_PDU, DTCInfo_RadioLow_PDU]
BO_ 1326 DTCInfo_RSC_PDU: 7 RSC
 SG_ DTCI_RSC_DTCFailType : 6|8@0+ (1,0) [0|255] "" CSM,TCP
 SG_ DTCI_RSC_CnfrmdDTC : 7|1@0+ (1,0) [0|1] "" CSM,TCP
 SG_ DTCI_RSC_DTCFaultType : 14|8@0+ (1,0) [0|3] "" CSM,TCP
 SG_ DTCI_RSC_DTCNumber : 22|16@0+ (1,0) [0|65535] "" CSM,TCP
 SG_ DTCI_RSC_DTCSource : 38|8@0+ (1,0) [0|255] "" CGM,CSM,TCP
 SG_ DTCI_RSC_TstNCmpltdOpCyc : 40|1@0+ (1,0) [0|1] "" CSM,TCP
 SG_ DTCI_RSC_TstNCmpltdLstClr : 41|1@0+ (1,0) [0|1] "" CSM,TCP
 SG_ DTCI_RSC_TstFldOpCyc : 42|1@0+ (1,0) [0|1] "" CSM,TCP
 SG_ DTCI_RSC_TstFldLstClr : 43|1@0+ (1,0) [0|1] "" CSM,TCP
 SG_ DTCI_RSC_TstFld : 44|1@0+ (1,0) [0|1] "" CSM,TCP
 SG_ DTCI_RSC_PndngDTC : 45|1@0+ (1,0) [0|1] "" CSM,TCP
 SG_ DTCI_RSC_DTCTriggered : 46|1@0+ (1,0) [0|1] "" CSM,TCP
 SG_ DTCI_RSC_WrnIndTrggrd : 54|1@0+ (1,0) [0|1] "" CSM,TCP
 SG_ DTCI_RSC_WrnIndRqd : 55|1@0+ (1,0) [0|1] "" CSM,TCP

BO_ 1330 DTCInfo_RadioLow_PDU: 7 RadioLow
 SG_ DTCI_RadioLow_DTCFailType : 6|8@0+ (1,0) [0|255] "" CSM,TCP
 SG_ DTCI_RadioLow_CnfrmdDTC : 7|1@0+ (1,0) [0|1] "" CSM,TCP
 SG_ DTCI_RadioLow_DTCFaultType : 14|8@0+ (1,0) [0|3] "" CSM,TCP
 SG_ DTCI_RadioLow_DTCNumber : 22|16@0+ (1,0) [0|65535] "" CSM,TCP
 SG_ DTCI_RadioLow_DTCSource : 38|8@0+ (1,0) [0|255] "" CGM,CSM,TCP
 SG_ DTCI_RadioLow_TstNCmpltdOpCyc : 40|1@0+ (1,0) [0|1] "" CSM,TCP
 SG_ DTCI_RadioLow_TstNCmpltdLstClr : 41|1@0+ (1,0) [0|1] "" CSM,TCP
 SG_ DTCI_RadioLow_TstFldOpCyc : 42|1@0+ (1,0) [0|1] "" CSM,TCP
 SG_ DTCI_RadioLow_TstFldLstClr : 43|1@0+ (1,0) [0|1] "" CSM,TCP
 SG_ DTCI_RadioLow_TstFld : 44|1@0+ (1,0) [0|1] "" CSM,TCP
 SG_ DTCI_RadioLow_PndngDTC : 45|1@0+ (1,0) [0|1] "" CSM,TCP
 SG_ DTCI_RadioLow_DTCTriggered : 46|1@0+ (1,0) [0|1] "" CSM,TCP
 SG_ DTCI_RadioLow_WrnIndTrggrd : 54|1@0+ (1,0) [0|1] "" CSM,TCP
 SG_ DTCI_RadioLow_WrnIndRqd : 55|1@0+ (1,0) [0|1] "" CSM,TCP

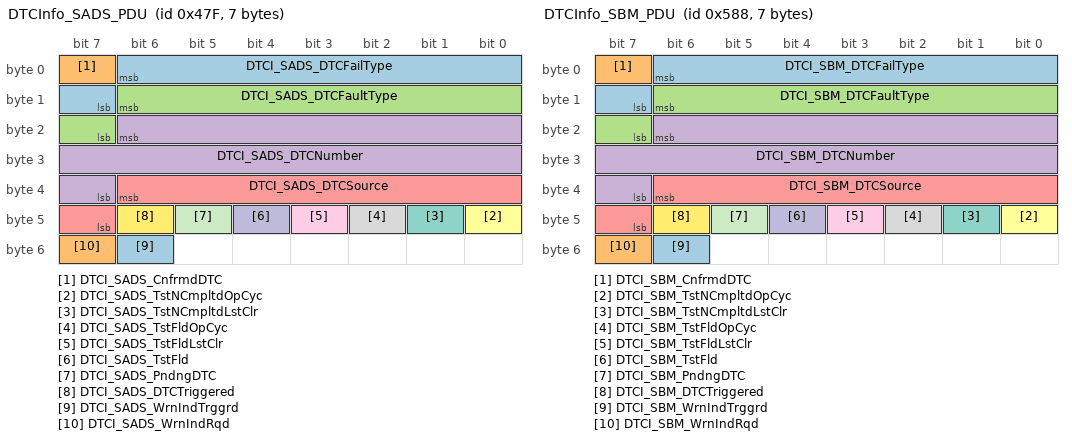
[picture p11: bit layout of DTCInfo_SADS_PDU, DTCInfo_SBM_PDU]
BO_ 1151 DTCInfo_SADS_PDU: 7 CGM
 SG_ DTCI_SADS_DTCFailType : 6|8@0+ (1,0) [0|255] "" CSM,TCP
 SG_ DTCI_SADS_CnfrmdDTC : 7|1@0+ (1,0) [0|1] "" CSM,TCP
 SG_ DTCI_SADS_DTCFaultType : 14|8@0+ (1,0) [0|3] "" CSM,TCP
 SG_ DTCI_SADS_DTCNumber : 22|16@0+ (1,0) [0|65535] "" CSM,TCP
 SG_ DTCI_SADS_DTCSource : 38|8@0+ (1,0) [0|255] "" CSM,TCP
 SG_ DTCI_SADS_TstNCmpltdOpCyc : 40|1@0+ (1,0) [0|1] "" CSM,TCP
 SG_ DTCI_SADS_TstNCmpltdLstClr : 41|1@0+ (1,0) [0|1] "" CSM,TCP
 SG_ DTCI_SADS_TstFldOpCyc : 42|1@0+ (1,0) [0|1] "" CSM,TCP
 SG_ DTCI_SADS_TstFldLstClr : 43|1@0+ (1,0) [0|1] "" CSM,TCP
 SG_ DTCI_SADS_TstFld : 44|1@0+ (1,0) [0|1] "" CSM,TCP
 SG_ DTCI_SADS_PndngDTC : 45|1@0+ (1,0) [0|1] "" CSM,TCP
 SG_ DTCI_SADS_DTCTriggered : 46|1@0+ (1,0) [0|1] "" CSM,TCP
 SG_ DTCI_SADS_WrnIndTrggrd : 54|1@0+ (1,0) [0|1] "" CSM,TCP
 SG_ DTCI_SADS_WrnIndRqd : 55|1@0+ (1,0) [0|1] "" CSM,TCP

BO_ 1416 DTCInfo_SBM_PDU: 7 CGM
 SG_ DTCI_SBM_DTCFailType : 6|8@0+ (1,0) [0|255] "" CSM,TCP
 SG_ DTCI_SBM_CnfrmdDTC : 7|1@0+ (1,0) [0|1] "" CSM,TCP
 SG_ DTCI_SBM_DTCFaultType : 14|8@0+ (1,0) [0|3] "" CSM,TCP
 SG_ DTCI_SBM_DTCNumber : 22|16@0+ (1,0) [0|65535] "" CSM,TCP
 SG_ DTCI_SBM_DTCSource : 38|8@0+ (1,0) [0|255] "" CSM,TCP
 SG_ DTCI_SBM_TstNCmpltdOpCyc : 40|1@0+ (1,0) [0|1] "" CSM,TCP
 SG_ DTCI_SBM_TstNCmpltdLstClr : 41|1@0+ (1,0) [0|1] "" CSM,TCP
 SG_ DTCI_SBM_TstFldOpCyc : 42|1@0+ (1,0) [0|1] "" CSM,TCP
 SG_ DTCI_SBM_TstFldLstClr : 43|1@0+ (1,0) [0|1] "" CSM,TCP
 SG_ DTCI_SBM_TstFld : 44|1@0+ (1,0) [0|1] "" CSM,TCP
 SG_ DTCI_SBM_PndngDTC : 45|1@0+ (1,0) [0|1] "" CSM,TCP
 SG_ DTCI_SBM_DTCTriggered : 46|1@0+ (1,0) [0|1] "" CSM,TCP
 SG_ DTCI_SBM_WrnIndTrggrd : 54|1@0+ (1,0) [0|1] "" CSM,TCP
 SG_ DTCI_SBM_WrnIndRqd : 55|1@0+ (1,0) [0|1] "" CSM,TCP

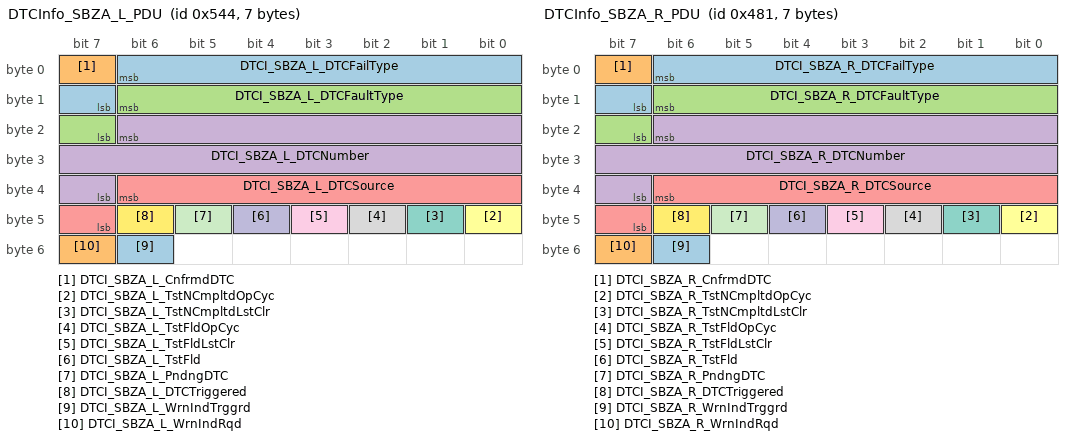
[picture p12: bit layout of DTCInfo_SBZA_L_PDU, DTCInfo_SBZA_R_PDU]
BO_ 1348 DTCInfo_SBZA_L_PDU: 7 CGM
 SG_ DTCI_SBZA_L_DTCFailType : 6|8@0+ (1,0) [0|255] "" CSM,TCP
 SG_ DTCI_SBZA_L_CnfrmdDTC : 7|1@0+ (1,0) [0|1] "" CSM,TCP
 SG_ DTCI_SBZA_L_DTCFaultType : 14|8@0+ (1,0) [0|3] "" CSM,TCP
 SG_ DTCI_SBZA_L_DTCNumber : 22|16@0+ (1,0) [0|65535] "" CSM,TCP
 SG_ DTCI_SBZA_L_DTCSource : 38|8@0+ (1,0) [0|255] "" CSM,TCP
 SG_ DTCI_SBZA_L_TstNCmpltdOpCyc : 40|1@0+ (1,0) [0|1] "" CSM,TCP
 SG_ DTCI_SBZA_L_TstNCmpltdLstClr : 41|1@0+ (1,0) [0|1] "" CSM,TCP
 SG_ DTCI_SBZA_L_TstFldOpCyc : 42|1@0+ (1,0) [0|1] "" CSM,TCP
 SG_ DTCI_SBZA_L_TstFldLstClr : 43|1@0+ (1,0) [0|1] "" CSM,TCP
 SG_ DTCI_SBZA_L_TstFld : 44|1@0+ (1,0) [0|1] "" CSM,TCP
 SG_ DTCI_SBZA_L_PndngDTC : 45|1@0+ (1,0) [0|1] "" CSM,TCP
 SG_ DTCI_SBZA_L_DTCTriggered : 46|1@0+ (1,0) [0|1] "" CSM,TCP
 SG_ DTCI_SBZA_L_WrnIndTrggrd : 54|1@0+ (1,0) [0|1] "" CSM,TCP
 SG_ DTCI_SBZA_L_WrnIndRqd : 55|1@0+ (1,0) [0|1] "" CSM,TCP

BO_ 1153 DTCInfo_SBZA_R_PDU: 7 CGM
 SG_ DTCI_SBZA_R_DTCFailType : 6|8@0+ (1,0) [0|255] "" CSM,TCP
 SG_ DTCI_SBZA_R_CnfrmdDTC : 7|1@0+ (1,0) [0|1] "" CSM,TCP
 SG_ DTCI_SBZA_R_DTCFaultType : 14|8@0+ (1,0) [0|3] "" CSM,TCP
 SG_ DTCI_SBZA_R_DTCNumber : 22|16@0+ (1,0) [0|65535] "" CSM,TCP
 SG_ DTCI_SBZA_R_DTCSource : 38|8@0+ (1,0) [0|255] "" CSM,TCP
 SG_ DTCI_SBZA_R_TstNCmpltdOpCyc : 40|1@0+ (1,0) [0|1] "" CSM,TCP
 SG_ DTCI_SBZA_R_TstNCmpltdLstClr : 41|1@0+ (1,0) [0|1] "" CSM,TCP
 SG_ DTCI_SBZA_R_TstFldOpCyc : 42|1@0+ (1,0) [0|1] "" CSM,TCP
 SG_ DTCI_SBZA_R_TstFldLstClr : 43|1@0+ (1,0) [0|1] "" CSM,TCP
 SG_ DTCI_SBZA_R_TstFld : 44|1@0+ (1,0) [0|1] "" CSM,TCP
 SG_ DTCI_SBZA_R_PndngDTC : 45|1@0+ (1,0) [0|1] "" CSM,TCP
 SG_ DTCI_SBZA_R_DTCTriggered : 46|1@0+ (1,0) [0|1] "" CSM,TCP
 SG_ DTCI_SBZA_R_WrnIndTrggrd : 54|1@0+ (1,0) [0|1] "" CSM,TCP
 SG_ DTCI_SBZA_R_WrnIndRqd : 55|1@0+ (1,0) [0|1] "" CSM,TCP

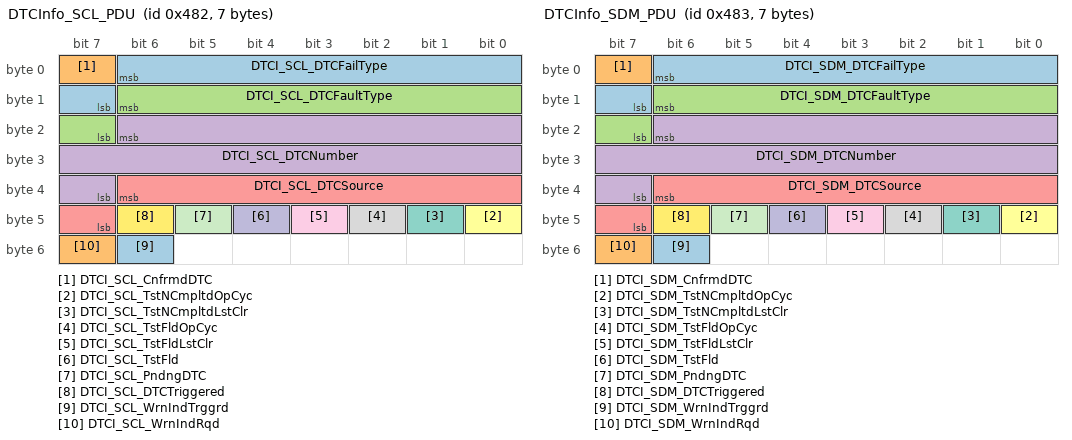
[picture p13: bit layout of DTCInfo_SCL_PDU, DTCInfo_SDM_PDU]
BO_ 1154 DTCInfo_SCL_PDU: 7 CGM
 SG_ DTCI_SCL_DTCFailType : 6|8@0+ (1,0) [0|255] "" CSM,TCP
 SG_ DTCI_SCL_CnfrmdDTC : 7|1@0+ (1,0) [0|1] "" CSM,TCP
 SG_ DTCI_SCL_DTCFaultType : 14|8@0+ (1,0) [0|3] "" CSM,TCP
 SG_ DTCI_SCL_DTCNumber : 22|16@0+ (1,0) [0|65535] "" CSM,TCP
 SG_ DTCI_SCL_DTCSource : 38|8@0+ (1,0) [0|255] "" CSM,TCP
 SG_ DTCI_SCL_TstNCmpltdOpCyc : 40|1@0+ (1,0) [0|1] "" CSM,TCP
 SG_ DTCI_SCL_TstNCmpltdLstClr : 41|1@0+ (1,0) [0|1] "" CSM,TCP
 SG_ DTCI_SCL_TstFldOpCyc : 42|1@0+ (1,0) [0|1] "" CSM,TCP
 SG_ DTCI_SCL_TstFldLstClr : 43|1@0+ (1,0) [0|1] "" CSM,TCP
 SG_ DTCI_SCL_TstFld : 44|1@0+ (1,0) [0|1] "" CSM,TCP
 SG_ DTCI_SCL_PndngDTC : 45|1@0+ (1,0) [0|1] "" CSM,TCP
 SG_ DTCI_SCL_DTCTriggered : 46|1@0+ (1,0) [0|1] "" CSM,TCP
 SG_ DTCI_SCL_WrnIndTrggrd : 54|1@0+ (1,0) [0|1] "" CSM,TCP
 SG_ DTCI_SCL_WrnIndRqd : 55|1@0+ (1,0) [0|1] "" CSM,TCP

BO_ 1155 DTCInfo_SDM_PDU: 7 CGM
 SG_ DTCI_SDM_DTCFailType : 6|8@0+ (1,0) [0|255] "" CSM,TCP
 SG_ DTCI_SDM_CnfrmdDTC : 7|1@0+ (1,0) [0|1] "" CSM,TCP
 SG_ DTCI_SDM_DTCFaultType : 14|8@0+ (1,0) [0|3] "" CSM,TCP
 SG_ DTCI_SDM_DTCNumber : 22|16@0+ (1,0) [0|65535] "" CSM,TCP
 SG_ DTCI_SDM_DTCSource : 38|8@0+ (1,0) [0|255] "" CSM,TCP
 SG_ DTCI_SDM_TstNCmpltdOpCyc : 40|1@0+ (1,0) [0|1] "" CSM,TCP
 SG_ DTCI_SDM_TstNCmpltdLstClr : 41|1@0+ (1,0) [0|1] "" CSM,TCP
 SG_ DTCI_SDM_TstFldOpCyc : 42|1@0+ (1,0) [0|1] "" CSM,TCP
 SG_ DTCI_SDM_TstFldLstClr : 43|1@0+ (1,0) [0|1] "" CSM,TCP
 SG_ DTCI_SDM_TstFld : 44|1@0+ (1,0) [0|1] "" CSM,TCP
 SG_ DTCI_SDM_PndngDTC : 45|1@0+ (1,0) [0|1] "" CSM,TCP
 SG_ DTCI_SDM_DTCTriggered : 46|1@0+ (1,0) [0|1] "" CSM,TCP
 SG_ DTCI_SDM_WrnIndTrggrd : 54|1@0+ (1,0) [0|1] "" CSM,TCP
 SG_ DTCI_SDM_WrnIndRqd : 55|1@0+ (1,0) [0|1] "" CSM,TCP

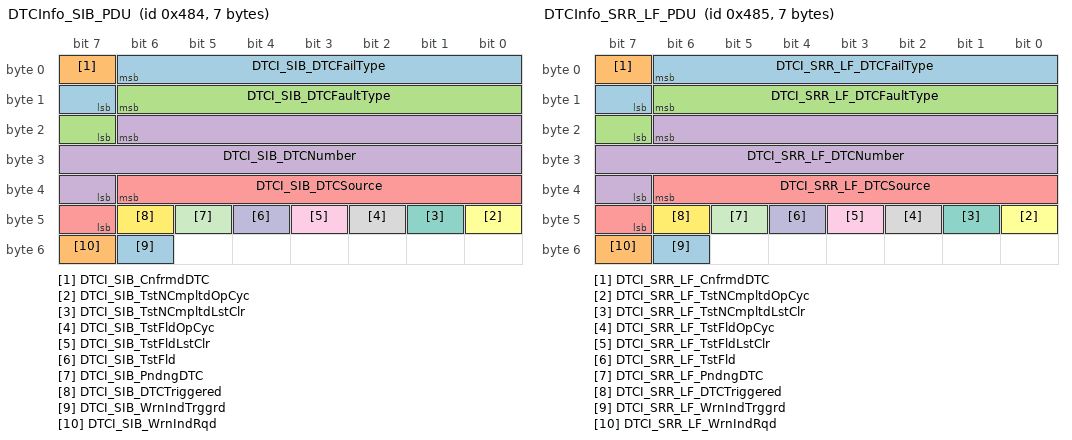
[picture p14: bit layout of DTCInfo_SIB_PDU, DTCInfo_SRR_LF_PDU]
BO_ 1156 DTCInfo_SIB_PDU: 7 CGM
 SG_ DTCI_SIB_DTCFailType : 6|8@0+ (1,0) [0|255] "" CSM,TCP
 SG_ DTCI_SIB_CnfrmdDTC : 7|1@0+ (1,0) [0|1] "" CSM,TCP
 SG_ DTCI_SIB_DTCFaultType : 14|8@0+ (1,0) [0|3] "" CSM,TCP
 SG_ DTCI_SIB_DTCNumber : 22|16@0+ (1,0) [0|65535] "" CSM,TCP
 SG_ DTCI_SIB_DTCSource : 38|8@0+ (1,0) [0|255] "" CSM,TCP
 SG_ DTCI_SIB_TstNCmpltdOpCyc : 40|1@0+ (1,0) [0|1] "" CSM,TCP
 SG_ DTCI_SIB_TstNCmpltdLstClr : 41|1@0+ (1,0) [0|1] "" CSM,TCP
 SG_ DTCI_SIB_TstFldOpCyc : 42|1@0+ (1,0) [0|1] "" CSM,TCP
 SG_ DTCI_SIB_TstFldLstClr : 43|1@0+ (1,0) [0|1] "" CSM,TCP
 SG_ DTCI_SIB_TstFld : 44|1@0+ (1,0) [0|1] "" CSM,TCP
 SG_ DTCI_SIB_PndngDTC : 45|1@0+ (1,0) [0|1] "" CSM,TCP
 SG_ DTCI_SIB_DTCTriggered : 46|1@0+ (1,0) [0|1] "" CSM,TCP
 SG_ DTCI_SIB_WrnIndTrggrd : 54|1@0+ (1,0) [0|1] "" CSM,TCP
 SG_ DTCI_SIB_WrnIndRqd : 55|1@0+ (1,0) [0|1] "" CSM,TCP

BO_ 1157 DTCInfo_SRR_LF_PDU: 7 CGM
 SG_ DTCI_SRR_LF_DTCFailType : 6|8@0+ (1,0) [0|255] "" CSM,TCP
 SG_ DTCI_SRR_LF_CnfrmdDTC : 7|1@0+ (1,0) [0|1] "" CSM,TCP
 SG_ DTCI_SRR_LF_DTCFaultType : 14|8@0+ (1,0) [0|3] "" CSM,TCP
 SG_ DTCI_SRR_LF_DTCNumber : 22|16@0+ (1,0) [0|65535] "" CSM,TCP
 SG_ DTCI_SRR_LF_DTCSource : 38|8@0+ (1,0) [0|255] "" CSM,TCP
 SG_ DTCI_SRR_LF_TstNCmpltdOpCyc : 40|1@0+ (1,0) [0|1] "" CSM,TCP
 SG_ DTCI_SRR_LF_TstNCmpltdLstClr : 41|1@0+ (1,0) [0|1] "" CSM,TCP
 SG_ DTCI_SRR_LF_TstFldOpCyc : 42|1@0+ (1,0) [0|1] "" CSM,TCP
 SG_ DTCI_SRR_LF_TstFldLstClr : 43|1@0+ (1,0) [0|1] "" CSM,TCP
 SG_ DTCI_SRR_LF_TstFld : 44|1@0+ (1,0) [0|1] "" CSM,TCP
 SG_ DTCI_SRR_LF_PndngDTC : 45|1@0+ (1,0) [0|1] "" CSM,TCP
 SG_ DTCI_SRR_LF_DTCTriggered : 46|1@0+ (1,0) [0|1] "" CSM,TCP
 SG_ DTCI_SRR_LF_WrnIndTrggrd : 54|1@0+ (1,0) [0|1] "" CSM,TCP
 SG_ DTCI_SRR_LF_WrnIndRqd : 55|1@0+ (1,0) [0|1] "" CSM,TCP

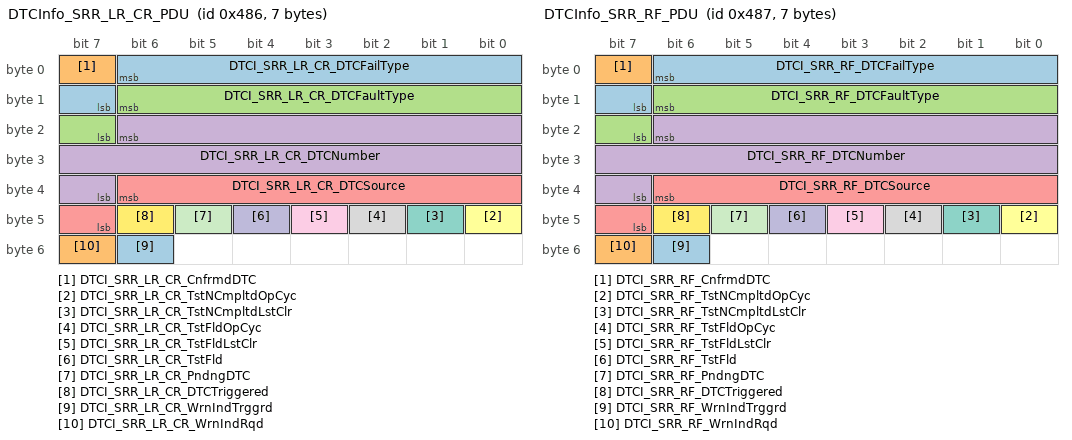
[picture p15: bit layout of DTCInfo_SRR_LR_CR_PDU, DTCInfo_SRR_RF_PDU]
BO_ 1158 DTCInfo_SRR_LR_CR_PDU: 7 CGM
 SG_ DTCI_SRR_LR_CR_DTCFailType : 6|8@0+ (1,0) [0|255] "" CSM,TCP
 SG_ DTCI_SRR_LR_CR_CnfrmdDTC : 7|1@0+ (1,0) [0|1] "" CSM,TCP
 SG_ DTCI_SRR_LR_CR_DTCFaultType : 14|8@0+ (1,0) [0|3] "" CSM,TCP
 SG_ DTCI_SRR_LR_CR_DTCNumber : 22|16@0+ (1,0) [0|65535] "" CSM,TCP
 SG_ DTCI_SRR_LR_CR_DTCSource : 38|8@0+ (1,0) [0|255] "" CSM,TCP
 SG_ DTCI_SRR_LR_CR_TstNCmpltdOpCyc : 40|1@0+ (1,0) [0|1] "" CSM,TCP
 SG_ DTCI_SRR_LR_CR_TstNCmpltdLstClr : 41|1@0+ (1,0) [0|1] "" CSM,TCP
 SG_ DTCI_SRR_LR_CR_TstFldOpCyc : 42|1@0+ (1,0) [0|1] "" CSM,TCP
 SG_ DTCI_SRR_LR_CR_TstFldLstClr : 43|1@0+ (1,0) [0|1] "" CSM,TCP
 SG_ DTCI_SRR_LR_CR_TstFld : 44|1@0+ (1,0) [0|1] "" CSM,TCP
 SG_ DTCI_SRR_LR_CR_PndngDTC : 45|1@0+ (1,0) [0|1] "" CSM,TCP
 SG_ DTCI_SRR_LR_CR_DTCTriggered : 46|1@0+ (1,0) [0|1] "" CSM,TCP
 SG_ DTCI_SRR_LR_CR_WrnIndTrggrd : 54|1@0+ (1,0) [0|1] "" CSM,TCP
 SG_ DTCI_SRR_LR_CR_WrnIndRqd : 55|1@0+ (1,0) [0|1] "" CSM,TCP

BO_ 1159 DTCInfo_SRR_RF_PDU: 7 CGM
 SG_ DTCI_SRR_RF_DTCFailType : 6|8@0+ (1,0) [0|255] "" CSM,TCP
 SG_ DTCI_SRR_RF_CnfrmdDTC : 7|1@0+ (1,0) [0|1] "" CSM,TCP
 SG_ DTCI_SRR_RF_DTCFaultType : 14|8@0+ (1,0) [0|3] "" CSM,TCP
 SG_ DTCI_SRR_RF_DTCNumber : 22|16@0+ (1,0) [0|65535] "" CSM,TCP
 SG_ DTCI_SRR_RF_DTCSource : 38|8@0+ (1,0) [0|255] "" CSM,TCP
 SG_ DTCI_SRR_RF_TstNCmpltdOpCyc : 40|1@0+ (1,0) [0|1] "" CSM,TCP
 SG_ DTCI_SRR_RF_TstNCmpltdLstClr : 41|1@0+ (1,0) [0|1] "" CSM,TCP
 SG_ DTCI_SRR_RF_TstFldOpCyc : 42|1@0+ (1,0) [0|1] "" CSM,TCP
 SG_ DTCI_SRR_RF_TstFldLstClr : 43|1@0+ (1,0) [0|1] "" CSM,TCP
 SG_ DTCI_SRR_RF_TstFld : 44|1@0+ (1,0) [0|1] "" CSM,TCP
 SG_ DTCI_SRR_RF_PndngDTC : 45|1@0+ (1,0) [0|1] "" CSM,TCP
 SG_ DTCI_SRR_RF_DTCTriggered : 46|1@0+ (1,0) [0|1] "" CSM,TCP
 SG_ DTCI_SRR_RF_WrnIndTrggrd : 54|1@0+ (1,0) [0|1] "" CSM,TCP
 SG_ DTCI_SRR_RF_WrnIndRqd : 55|1@0+ (1,0) [0|1] "" CSM,TCP

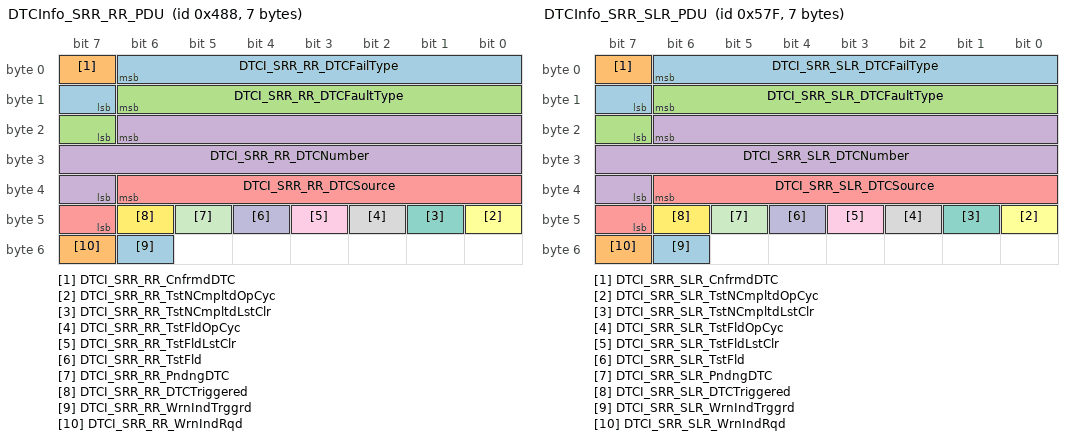
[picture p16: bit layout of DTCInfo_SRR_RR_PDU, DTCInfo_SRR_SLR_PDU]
BO_ 1160 DTCInfo_SRR_RR_PDU: 7 CGM
 SG_ DTCI_SRR_RR_DTCFailType : 6|8@0+ (1,0) [0|255] "" CSM,TCP
 SG_ DTCI_SRR_RR_CnfrmdDTC : 7|1@0+ (1,0) [0|1] "" CSM,TCP
 SG_ DTCI_SRR_RR_DTCFaultType : 14|8@0+ (1,0) [0|3] "" CSM,TCP
 SG_ DTCI_SRR_RR_DTCNumber : 22|16@0+ (1,0) [0|65535] "" CSM,TCP
 SG_ DTCI_SRR_RR_DTCSource : 38|8@0+ (1,0) [0|255] "" CSM,TCP
 SG_ DTCI_SRR_RR_TstNCmpltdOpCyc : 40|1@0+ (1,0) [0|1] "" CSM,TCP
 SG_ DTCI_SRR_RR_TstNCmpltdLstClr : 41|1@0+ (1,0) [0|1] "" CSM,TCP
 SG_ DTCI_SRR_RR_TstFldOpCyc : 42|1@0+ (1,0) [0|1] "" CSM,TCP
 SG_ DTCI_SRR_RR_TstFldLstClr : 43|1@0+ (1,0) [0|1] "" CSM,TCP
 SG_ DTCI_SRR_RR_TstFld : 44|1@0+ (1,0) [0|1] "" CSM,TCP
 SG_ DTCI_SRR_RR_PndngDTC : 45|1@0+ (1,0) [0|1] "" CSM,TCP
 SG_ DTCI_SRR_RR_DTCTriggered : 46|1@0+ (1,0) [0|1] "" CSM,TCP
 SG_ DTCI_SRR_RR_WrnIndTrggrd : 54|1@0+ (1,0) [0|1] "" CSM,TCP
 SG_ DTCI_SRR_RR_WrnIndRqd : 55|1@0+ (1,0) [0|1] "" CSM,TCP

BO_ 1407 DTCInfo_SRR_SLR_PDU: 7 CGM
 SG_ DTCI_SRR_SLR_DTCFailType : 6|8@0+ (1,0) [0|255] "" CSM,TCP
 SG_ DTCI_SRR_SLR_CnfrmdDTC : 7|1@0+ (1,0) [0|1] "" CSM,TCP
 SG_ DTCI_SRR_SLR_DTCFaultType : 14|8@0+ (1,0) [0|3] "" CSM,TCP
 SG_ DTCI_SRR_SLR_DTCNumber : 22|16@0+ (1,0) [0|65535] "" CSM,TCP
 SG_ DTCI_SRR_SLR_DTCSource : 38|8@0+ (1,0) [0|255] "" CSM,TCP
 SG_ DTCI_SRR_SLR_TstNCmpltdOpCyc : 40|1@0+ (1,0) [0|1] "" CSM,TCP
 SG_ DTCI_SRR_SLR_TstNCmpltdLstClr : 41|1@0+ (1,0) [0|1] "" CSM,TCP
 SG_ DTCI_SRR_SLR_TstFldOpCyc : 42|1@0+ (1,0) [0|1] "" CSM,TCP
 SG_ DTCI_SRR_SLR_TstFldLstClr : 43|1@0+ (1,0) [0|1] "" CSM,TCP
 SG_ DTCI_SRR_SLR_TstFld : 44|1@0+ (1,0) [0|1] "" CSM,TCP
 SG_ DTCI_SRR_SLR_PndngDTC : 45|1@0+ (1,0) [0|1] "" CSM,TCP
 SG_ DTCI_SRR_SLR_DTCTriggered : 46|1@0+ (1,0) [0|1] "" CSM,TCP
 SG_ DTCI_SRR_SLR_WrnIndTrggrd : 54|1@0+ (1,0) [0|1] "" CSM,TCP
 SG_ DTCI_SRR_SLR_WrnIndRqd : 55|1@0+ (1,0) [0|1] "" CSM,TCP

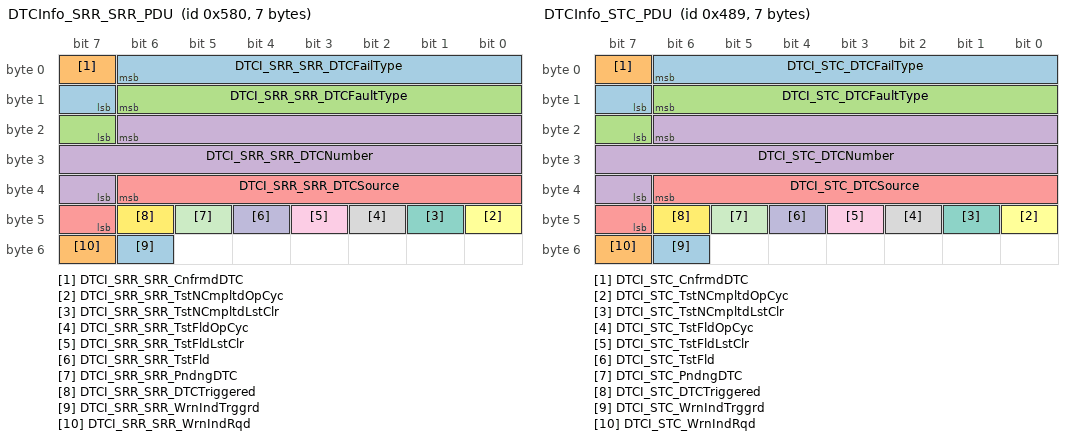
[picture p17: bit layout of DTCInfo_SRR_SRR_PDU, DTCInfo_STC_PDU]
BO_ 1408 DTCInfo_SRR_SRR_PDU: 7 CGM
 SG_ DTCI_SRR_SRR_DTCFailType : 6|8@0+ (1,0) [0|255] "" CSM,TCP
 SG_ DTCI_SRR_SRR_CnfrmdDTC : 7|1@0+ (1,0) [0|1] "" CSM,TCP
 SG_ DTCI_SRR_SRR_DTCFaultType : 14|8@0+ (1,0) [0|3] "" CSM,TCP
 SG_ DTCI_SRR_SRR_DTCNumber : 22|16@0+ (1,0) [0|65535] "" CSM,TCP
 SG_ DTCI_SRR_SRR_DTCSource : 38|8@0+ (1,0) [0|255] "" CSM,TCP
 SG_ DTCI_SRR_SRR_TstNCmpltdOpCyc : 40|1@0+ (1,0) [0|1] "" CSM,TCP
 SG_ DTCI_SRR_SRR_TstNCmpltdLstClr : 41|1@0+ (1,0) [0|1] "" CSM,TCP
 SG_ DTCI_SRR_SRR_TstFldOpCyc : 42|1@0+ (1,0) [0|1] "" CSM,TCP
 SG_ DTCI_SRR_SRR_TstFldLstClr : 43|1@0+ (1,0) [0|1] "" CSM,TCP
 SG_ DTCI_SRR_SRR_TstFld : 44|1@0+ (1,0) [0|1] "" CSM,TCP
 SG_ DTCI_SRR_SRR_PndngDTC : 45|1@0+ (1,0) [0|1] "" CSM,TCP
 SG_ DTCI_SRR_SRR_DTCTriggered : 46|1@0+ (1,0) [0|1] "" CSM,TCP
 SG_ DTCI_SRR_SRR_WrnIndTrggrd : 54|1@0+ (1,0) [0|1] "" CSM,TCP
 SG_ DTCI_SRR_SRR_WrnIndRqd : 55|1@0+ (1,0) [0|1] "" CSM,TCP

BO_ 1161 DTCInfo_STC_PDU: 7 CGM
 SG_ DTCI_STC_DTCFailType : 6|8@0+ (1,0) [0|255] "" CSM,TCP
 SG_ DTCI_STC_CnfrmdDTC : 7|1@0+ (1,0) [0|1] "" CSM,TCP
 SG_ DTCI_STC_DTCFaultType : 14|8@0+ (1,0) [0|3] "" CSM,TCP
 SG_ DTCI_STC_DTCNumber : 22|16@0+ (1,0) [0|65535] "" CSM,TCP
 SG_ DTCI_STC_DTCSource : 38|8@0+ (1,0) [0|255] "" CSM,TCP
 SG_ DTCI_STC_TstNCmpltdOpCyc : 40|1@0+ (1,0) [0|1] "" CSM,TCP
 SG_ DTCI_STC_TstNCmpltdLstClr : 41|1@0+ (1,0) [0|1] "" CSM,TCP
 SG_ DTCI_STC_TstFldOpCyc : 42|1@0+ (1,0) [0|1] "" CSM,TCP
 SG_ DTCI_STC_TstFldLstClr : 43|1@0+ (1,0) [0|1] "" CSM,TCP
 SG_ DTCI_STC_TstFld : 44|1@0+ (1,0) [0|1] "" CSM,TCP
 SG_ DTCI_STC_PndngDTC : 45|1@0+ (1,0) [0|1] "" CSM,TCP
 SG_ DTCI_STC_DTCTriggered : 46|1@0+ (1,0) [0|1] "" CSM,TCP
 SG_ DTCI_STC_WrnIndTrggrd : 54|1@0+ (1,0) [0|1] "" CSM,TCP
 SG_ DTCI_STC_WrnIndRqd : 55|1@0+ (1,0) [0|1] "" CSM,TCP

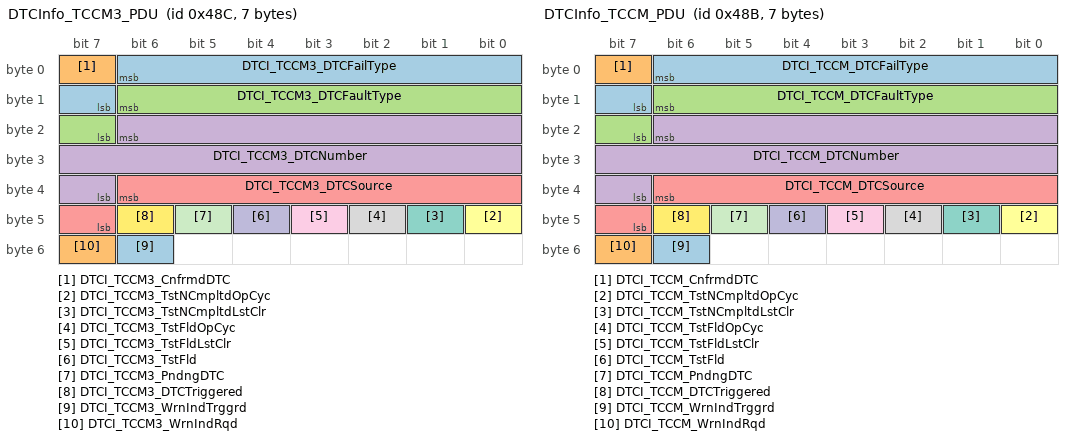
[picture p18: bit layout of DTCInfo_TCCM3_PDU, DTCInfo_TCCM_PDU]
BO_ 1164 DTCInfo_TCCM3_PDU: 7 CGM
 SG_ DTCI_TCCM3_DTCFailType : 6|8@0+ (1,0) [0|255] "" CSM,TCP
 SG_ DTCI_TCCM3_CnfrmdDTC : 7|1@0+ (1,0) [0|1] "" CSM,TCP
 SG_ DTCI_TCCM3_DTCFaultType : 14|8@0+ (1,0) [0|3] "" CSM,TCP
 SG_ DTCI_TCCM3_DTCNumber : 22|16@0+ (1,0) [0|65535] "" CSM,TCP
 SG_ DTCI_TCCM3_DTCSource : 38|8@0+ (1,0) [0|255] "" CSM,TCP
 SG_ DTCI_TCCM3_TstNCmpltdOpCyc : 40|1@0+ (1,0) [0|1] "" CSM,TCP
 SG_ DTCI_TCCM3_TstNCmpltdLstClr : 41|1@0+ (1,0) [0|1] "" CSM,TCP
 SG_ DTCI_TCCM3_TstFldOpCyc : 42|1@0+ (1,0) [0|1] "" CSM,TCP
 SG_ DTCI_TCCM3_TstFldLstClr : 43|1@0+ (1,0) [0|1] "" CSM,TCP
 SG_ DTCI_TCCM3_TstFld : 44|1@0+ (1,0) [0|1] "" CSM,TCP
 SG_ DTCI_TCCM3_PndngDTC : 45|1@0+ (1,0) [0|1] "" CSM,TCP
 SG_ DTCI_TCCM3_DTCTriggered : 46|1@0+ (1,0) [0|1] "" CSM,TCP
 SG_ DTCI_TCCM3_WrnIndTrggrd : 54|1@0+ (1,0) [0|1] "" CSM,TCP
 SG_ DTCI_TCCM3_WrnIndRqd : 55|1@0+ (1,0) [0|1] "" CSM,TCP

BO_ 1163 DTCInfo_TCCM_PDU: 7 CGM
 SG_ DTCI_TCCM_DTCFailType : 6|8@0+ (1,0) [0|255] "" CSM,TCP
 SG_ DTCI_TCCM_CnfrmdDTC : 7|1@0+ (1,0) [0|1] "" CSM,TCP
 SG_ DTCI_TCCM_DTCFaultType : 14|8@0+ (1,0) [0|3] "" CSM,TCP
 SG_ DTCI_TCCM_DTCNumber : 22|16@0+ (1,0) [0|65535] "" CSM,TCP
 SG_ DTCI_TCCM_DTCSource : 38|8@0+ (1,0) [0|255] "" CSM,TCP
 SG_ DTCI_TCCM_TstNCmpltdOpCyc : 40|1@0+ (1,0) [0|1] "" CSM,TCP
 SG_ DTCI_TCCM_TstNCmpltdLstClr : 41|1@0+ (1,0) [0|1] "" CSM,TCP
 SG_ DTCI_TCCM_TstFldOpCyc : 42|1@0+ (1,0) [0|1] "" CSM,TCP
 SG_ DTCI_TCCM_TstFldLstClr : 43|1@0+ (1,0) [0|1] "" CSM,TCP
 SG_ DTCI_TCCM_TstFld : 44|1@0+ (1,0) [0|1] "" CSM,TCP
 SG_ DTCI_TCCM_PndngDTC : 45|1@0+ (1,0) [0|1] "" CSM,TCP
 SG_ DTCI_TCCM_DTCTriggered : 46|1@0+ (1,0) [0|1] "" CSM,TCP
 SG_ DTCI_TCCM_WrnIndTrggrd : 54|1@0+ (1,0) [0|1] "" CSM,TCP
 SG_ DTCI_TCCM_WrnIndRqd : 55|1@0+ (1,0) [0|1] "" CSM,TCP

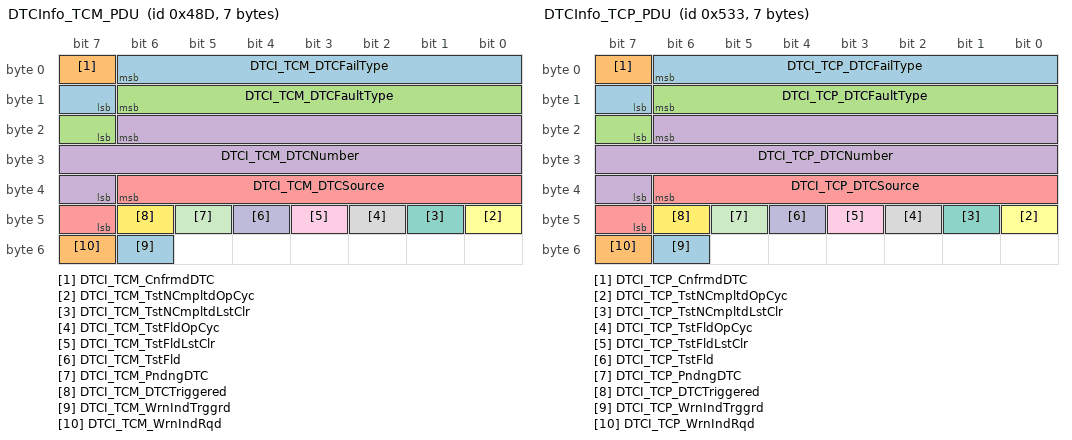
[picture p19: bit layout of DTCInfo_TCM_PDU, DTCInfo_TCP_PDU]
BO_ 1165 DTCInfo_TCM_PDU: 7 CGM
 SG_ DTCI_TCM_DTCFailType : 6|8@0+ (1,0) [0|255] "" CSM,TCP
 SG_ DTCI_TCM_CnfrmdDTC : 7|1@0+ (1,0) [0|1] "" CSM,TCP
 SG_ DTCI_TCM_DTCFaultType : 14|8@0+ (1,0) [0|3] "" CSM,TCP
 SG_ DTCI_TCM_DTCNumber : 22|16@0+ (1,0) [0|65535] "" CSM,TCP
 SG_ DTCI_TCM_DTCSource : 38|8@0+ (1,0) [0|255] "" CSM,TCP
 SG_ DTCI_TCM_TstNCmpltdOpCyc : 40|1@0+ (1,0) [0|1] "" CSM,TCP
 SG_ DTCI_TCM_TstNCmpltdLstClr : 41|1@0+ (1,0) [0|1] "" CSM,TCP
 SG_ DTCI_TCM_TstFldOpCyc : 42|1@0+ (1,0) [0|1] "" CSM,TCP
 SG_ DTCI_TCM_TstFldLstClr : 43|1@0+ (1,0) [0|1] "" CSM,TCP
 SG_ DTCI_TCM_TstFld : 44|1@0+ (1,0) [0|1] "" CSM,TCP
 SG_ DTCI_TCM_PndngDTC : 45|1@0+ (1,0) [0|1] "" CSM,TCP
 SG_ DTCI_TCM_DTCTriggered : 46|1@0+ (1,0) [0|1] "" CSM,TCP
 SG_ DTCI_TCM_WrnIndTrggrd : 54|1@0+ (1,0) [0|1] "" CSM,TCP
 SG_ DTCI_TCM_WrnIndRqd : 55|1@0+ (1,0) [0|1] "" CSM,TCP

BO_ 1331 DTCInfo_TCP_PDU: 7 TCP
 SG_ DTCI_TCP_DTCFailType : 6|8@0+ (1,0) [0|255] "" CSM,TCP
 SG_ DTCI_TCP_CnfrmdDTC : 7|1@0+ (1,0) [0|1] "" CSM,TCP
 SG_ DTCI_TCP_DTCFaultType : 14|8@0+ (1,0) [0|3] "" CSM,TCP
 SG_ DTCI_TCP_DTCNumber : 22|16@0+ (1,0) [0|65535] "" CSM,TCP
 SG_ DTCI_TCP_DTCSource : 38|8@0+ (1,0) [0|255] "" CGM,CSM,TCP
 SG_ DTCI_TCP_TstNCmpltdOpCyc : 40|1@0+ (1,0) [0|1] "" CSM,TCP
 SG_ DTCI_TCP_TstNCmpltdLstClr : 41|1@0+ (1,0) [0|1] "" CSM,TCP
 SG_ DTCI_TCP_TstFldOpCyc : 42|1@0+ (1,0) [0|1] "" CSM,TCP
 SG_ DTCI_TCP_TstFldLstClr : 43|1@0+ (1,0) [0|1] "" CSM,TCP
 SG_ DTCI_TCP_TstFld : 44|1@0+ (1,0) [0|1] "" CSM,TCP
 SG_ DTCI_TCP_PndngDTC : 45|1@0+ (1,0) [0|1] "" CSM,TCP
 SG_ DTCI_TCP_DTCTriggered : 46|1@0+ (1,0) [0|1] "" CSM,TCP
 SG_ DTCI_TCP_WrnIndTrggrd : 54|1@0+ (1,0) [0|1] "" CSM,TCP
 SG_ DTCI_TCP_WrnIndRqd : 55|1@0+ (1,0) [0|1] "" CSM,TCP

BO_ 1166 DTCInfo_TIM_PDU: 7 CGM
 SG_ DTCI_TIM_DTCFailType : 6|8@0+ (1,0) [0|255] "" CSM,TCP
 SG_ DTCI_TIM_CnfrmdDTC : 7|1@0+ (1,0) [0|1] "" CSM,TCP
 SG_ DTCI_TIM_DTCFaultType : 14|8@0+ (1,0) [0|3] "" CSM,TCP
 SG_ DTCI_TIM_DTCNumber : 22|16@0+ (1,0) [0|65535] "" CSM,TCP
 SG_ DTCI_TIM_DTCSource : 38|8@0+ (1,0) [0|255] "" CSM,TCP
 SG_ DTCI_TIM_TstNCmpltdOpCyc : 40|1@0+ (1,0) [0|1] "" CSM,TCP
 SG_ DTCI_TIM_TstNCmpltdLstClr : 41|1@0+ (1,0) [0|1] "" CSM,TCP
 SG_ DTCI_TIM_TstFldOpCyc : 42|1@0+ (1,0) [0|1] "" CSM,TCP
 SG_ DTCI_TIM_TstFldLstClr : 43|1@0+ (1,0) [0|1] "" CSM,TCP
 SG_ DTCI_TIM_TstFld : 44|1@0+ (1,0) [0|1] "" CSM,TCP
 SG_ DTCI_TIM_PndngDTC : 45|1@0+ (1,0) [0|1] "" CSM,TCP
 SG_ DTCI_TIM_DTCTriggered : 46|1@0+ (1,0) [0|1] "" CSM,TCP
 SG_ DTCI_TIM_WrnIndTrggrd : 54|1@0+ (1,0) [0|1] "" CSM,TCP
 SG_ DTCI_TIM_WrnIndRqd : 55|1@0+ (1,0) [0|1] "" CSM,TCP

BO_ 1437 DTCInfo_UVM_PDU: 7 CGM
 SG_ DTCI_UVM_DTCFailType : 6|8@0+ (1,0) [0|255] "" TCP
 SG_ DTCI_UVM_CnfrmdDTC : 7|1@0+ (1,0) [0|1] "" TCP
 SG_ DTCI_UVM_DTCFaultType : 14|8@0+ (1,0) [0|3] "" TCP
 SG_ DTCI_UVM_DTCNumber : 22|16@0+ (1,0) [0|65535] "" TCP
 SG_ DTCI_UVM_DTCSource : 38|8@0+ (1,0) [0|255] "" TCP
 SG_ DTCI_UVM_TstNCmpltdOpCyc : 40|1@0+ (1,0) [0|1] "" TCP
 SG_ DTCI_UVM_TstNCmpltdLstClr : 41|1@0+ (1,0) [0|1] "" TCP
 SG_ DTCI_UVM_TstFldOpCyc : 42|1@0+ (1,0) [0|1] "" TCP
 SG_ DTCI_UVM_TstFldLstClr : 43|1@0+ (1,0) [0|1] "" TCP
 SG_ DTCI_UVM_TstFld : 44|1@0+ (1,0) [0|1] "" TCP
 SG_ DTCI_UVM_PndngDTC : 45|1@0+ (1,0) [0|1] "" TCP
 SG_ DTCI_UVM_DTCTriggered : 46|1@0+ (1,0) [0|1] "" TCP
 SG_ DTCI_UVM_WrnIndTrggrd : 54|1@0+ (1,0) [0|1] "" TCP
 SG_ DTCI_UVM_WrnIndRqd : 55|1@0+ (1,0) [0|1] "" TCP

BO_ 1341 DTCInfo_VKM_PDU: 7 VKM
 SG_ DTCI_VKM_DTCFailType : 6|8@0+ (1,0) [0|255] "" CSM,TCP
 SG_ DTCI_VKM_CnfrmdDTC : 7|1@0+ (1,0) [0|1] "" CSM,TCP
 SG_ DTCI_VKM_DTCFaultType : 14|8@0+ (1,0) [0|3] "" CSM,TCP
 SG_ DTCI_VKM_DTCNumber : 22|16@0+ (1,0) [0|65535] "" CSM,TCP
 SG_ DTCI_VKM_DTCSource : 38|8@0+ (1,0) [0|255] "" CGM,CSM,TCP
 SG_ DTCI_VKM_TstNCmpltdOpCyc : 40|1@0+ (1,0) [0|1] "" CSM,TCP
 SG_ DTCI_VKM_TstNCmpltdLstClr : 41|1@0+ (1,0) [0|1] "" CSM,TCP
 SG_ DTCI_VKM_TstFldOpCyc : 42|1@0+ (1,0) [0|1] "" CSM,TCP
 SG_ DTCI_VKM_TstFldLstClr : 43|1@0+ (1,0) [0|1] "" CSM,TCP
 SG_ DTCI_VKM_TstFld : 44|1@0+ (1,0) [0|1] "" CSM,TCP
 SG_ DTCI_VKM_PndngDTC : 45|1@0+ (1,0) [0|1] "" CSM,TCP
 SG_ DTCI_VKM_DTCTriggered : 46|1@0+ (1,0) [0|1] "" CSM,TCP
 SG_ DTCI_VKM_WrnIndTrggrd : 54|1@0+ (1,0) [0|1] "" CSM,TCP
 SG_ DTCI_VKM_WrnIndRqd : 55|1@0+ (1,0) [0|1] "" CSM,TCP

BO_ 1389 DTCInfo_VLM_PDU: 7 CGM
 SG_ DTCI_VLM_DTCFailType : 6|8@0+ (1,0) [0|255] "" CSM,TCP
 SG_ DTCI_VLM_CnfrmdDTC : 7|1@0+ (1,0) [0|1] "" CSM,TCP
 SG_ DTCI_VLM_DTCFaultType : 14|8@0+ (1,0) [0|3] "" CSM,TCP
 SG_ DTCI_VLM_DTCNumber : 22|16@0+ (1,0) [0|65535] "" CSM,TCP
 SG_ DTCI_VLM_DTCSource : 38|8@0+ (1,0) [0|255] "" CSM,TCP
 SG_ DTCI_VLM_TstNCmpltdOpCyc : 40|1@0+ (1,0) [0|1] "" CSM,TCP
 SG_ DTCI_VLM_TstNCmpltdLstClr : 41|1@0+ (1,0) [0|1] "" CSM,TCP
 SG_ DTCI_VLM_TstFldOpCyc : 42|1@0+ (1,0) [0|1] "" CSM,TCP
 SG_ DTCI_VLM_TstFldLstClr : 43|1@0+ (1,0) [0|1] "" CSM,TCP
 SG_ DTCI_VLM_TstFld : 44|1@0+ (1,0) [0|1] "" CSM,TCP
 SG_ DTCI_VLM_PndngDTC : 45|1@0+ (1,0) [0|1] "" CSM,TCP
 SG_ DTCI_VLM_DTCTriggered : 46|1@0+ (1,0) [0|1] "" CSM,TCP
 SG_ DTCI_VLM_WrnIndTrggrd : 54|1@0+ (1,0) [0|1] "" CSM,TCP
 SG_ DTCI_VLM_WrnIndRqd : 55|1@0+ (1,0) [0|1] "" CSM,TCP

BO_ 1167 DTCInfo_VPM_PDU: 7 CGM
 SG_ DTCI_VPM_DTCFailType : 6|8@0+ (1,0) [0|255] "" CSM,TCP
 SG_ DTCI_VPM_CnfrmdDTC : 7|1@0+ (1,0) [0|1] "" CSM,TCP
 SG_ DTCI_VPM_DTCFaultType : 14|8@0+ (1,0) [0|3] "" CSM,TCP
 SG_ DTCI_VPM_DTCNumber : 22|16@0+ (1,0) [0|65535] "" CSM,TCP
 SG_ DTCI_VPM_DTCSource : 38|8@0+ (1,0) [0|255] "" CSM,TCP
 SG_ DTCI_VPM_TstNCmpltdOpCyc : 40|1@0+ (1,0) [0|1] "" CSM,TCP
 SG_ DTCI_VPM_TstNCmpltdLstClr : 41|1@0+ (1,0) [0|1] "" CSM,TCP
 SG_ DTCI_VPM_TstFldOpCyc : 42|1@0+ (1,0) [0|1] "" CSM,TCP
 SG_ DTCI_VPM_TstFldLstClr : 43|1@0+ (1,0) [0|1] "" CSM,TCP
 SG_ DTCI_VPM_TstFld : 44|1@0+ (1,0) [0|1] "" CSM,TCP
 SG_ DTCI_VPM_PndngDTC : 45|1@0+ (1,0) [0|1] "" CSM,TCP
 SG_ DTCI_VPM_DTCTriggered : 46|1@0+ (1,0) [0|1] "" CSM,TCP
 SG_ DTCI_VPM_WrnIndTrggrd : 54|1@0+ (1,0) [0|1] "" CSM,TCP
 SG_ DTCI_VPM_WrnIndRqd : 55|1@0+ (1,0) [0|1] "" CSM,TCP

BA_DEF_ SG_  "SignalType" STRING ;
BA_DEF_ SG_  "SignalLongName" STRING ;
BA_DEF_ BO_  "GenMsgCycleTime" INT 0 10000;
BA_DEF_ BO_  "GenMsgSendType" ENUM "cyclicX","spontanX","cyclicIfActiveX","spontanWithDelay","cyclicAndSpontanX","cyclicAndSpontanWithDelay","spontanWithRepetition","cyclicIfActiveAndSpontanWD";
BA_DEF_DEF_  "SignalType" "";
BA_DEF_DEF_  "SignalLongName" "";
BA_DEF_DEF_  "GenMsgCycleTime" 0;
BA_DEF_DEF_  "GenMsgSendType" "cyclicX";
BA_ "GenMsgCycleTime" BO_ 1315 1000;
BA_ "GenMsgCycleTime" BO_ 1395 1000;
BA_ "GenMsgCycleTime" BO_ 1379 1000;
BA_ "GenMsgCycleTime" BO_ 1136 1000;
BA_ "GenMsgCycleTime" BO_ 1322 1000;
BA_ "GenMsgCycleTime" BO_ 1137 1000;
BA_ "GenMsgCycleTime" BO_ 1138 1000;
BA_ "GenMsgCycleTime" BO_ 1139 1000;
BA_ "GenMsgCycleTime" BO_ 1140 1000;
BA_ "GenMsgCycleTime" BO_ 1141 1000;
BA_ "GenMsgCycleTime" BO_ 1142 1000;
BA_ "GenMsgCycleTime" BO_ 1143 1000;
BA_ "GenMsgCycleTime" BO_ 1144 1000;
BA_ "GenMsgCycleTime" BO_ 1145 1000;
BA_ "GenMsgCycleTime" BO_ 1146 1000;
BA_ "GenMsgCycleTime" BO_ 1147 1000;
BA_ "GenMsgCycleTime" BO_ 1148 1000;
BA_ "GenMsgCycleTime" BO_ 1323 1000;
BA_ "GenMsgCycleTime" BO_ 1149 1000;
BA_ "GenMsgCycleTime" BO_ 1150 1000;
BA_ "GenMsgCycleTime" BO_ 1326 1000;
BA_ "GenMsgCycleTime" BO_ 1330 1000;
BA_ "GenMsgCycleTime" BO_ 1151 1000;
BA_ "GenMsgCycleTime" BO_ 1416 1000;
BA_ "GenMsgCycleTime" BO_ 1348 1000;
BA_ "GenMsgCycleTime" BO_ 1153 1000;
BA_ "GenMsgCycleTime" BO_ 1154 1000;
BA_ "GenMsgCycleTime" BO_ 1155 1000;
BA_ "GenMsgCycleTime" BO_ 1156 1000;
BA_ "GenMsgCycleTime" BO_ 1157 1000;
BA_ "GenMsgCycleTime" BO_ 1158 1000;
BA_ "GenMsgCycleTime" BO_ 1159 1000;
BA_ "GenMsgCycleTime" BO_ 1160 1000;
BA_ "GenMsgCycleTime" BO_ 1407 1000;
BA_ "GenMsgCycleTime" BO_ 1408 1000;
BA_ "GenMsgCycleTime" BO_ 1161 1000;
BA_ "GenMsgCycleTime" BO_ 1164 1000;
BA_ "GenMsgCycleTime" BO_ 1163 1000;
BA_ "GenMsgCycleTime" BO_ 1165 1000;
BA_ "GenMsgCycleTime" BO_ 1331 1000;
BA_ "GenMsgCycleTime" BO_ 1166 1000;
BA_ "GenMsgCycleTime" BO_ 1437 1000;
BA_ "GenMsgCycleTime" BO_ 1341 1000;
BA_ "GenMsgCycleTime" BO_ 1389 1000;
BA_ "GenMsgCycleTime" BO_ 1167 1000;
BA_ "SignalLongName" SG_ 1315 DTCI_IPC_DTCFailType "Diagnostic Trouble Code Information Extended - IPC : Diagnostic Trouble Code Failure Type";
BA_ "SignalType" SG_ 1315 DTCI_IPC_CnfrmdDTC "ENM";
BA_ "SignalLongName" SG_ 1315 DTCI_IPC_CnfrmdDTC "Diagnostic Trouble Code Information Extended - IPC : Confirmed DTC";
BA_ "SignalType" SG_ 1315 DTCI_IPC_DTCFaultType "ENM";
BA_ "SignalLongName" SG_ 1315 DTCI_IPC_DTCFaultType "Diagnostic Trouble Code Information Extended - IPC : Diagnostic Trouble Code Fault Type";
BA_ "SignalLongName" SG_ 1315 DTCI_IPC_DTCNumber "Diagnostic Trouble Code Information Extended - IPC : Diagnostic Trouble Code Number";
BA_ "SignalLongName" SG_ 1315 DTCI_IPC_DTCSource "Diagnostic Trouble Code Information Extended - IPC : Diagnostic Trouble Code Source";
BA_ "SignalType" SG_ 1315 DTCI_IPC_TstNCmpltdOpCyc "ENM";
BA_ "SignalLongName" SG_ 1315 DTCI_IPC_TstNCmpltdOpCyc "Diagnostic Trouble Code Information Extended - IPC : Test Not Completed This Operation Cycle";
BA_ "SignalType" SG_ 1315 DTCI_IPC_TstNCmpltdLstClr "ENM";
BA_ "SignalLongName" SG_ 1315 DTCI_IPC_TstNCmpltdLstClr "Diagnostic Trouble Code Information Extended - IPC : Test Not Completed Since Last Clear";
BA_ "SignalType" SG_ 1315 DTCI_IPC_TstFldOpCyc "ENM";
BA_ "SignalLongName" SG_ 1315 DTCI_IPC_TstFldOpCyc "Diagnostic Trouble Code Information Extended - IPC : Test Failed This Operation Cycle";
BA_ "SignalType" SG_ 1315 DTCI_IPC_TstFldLstClr "ENM";
BA_ "SignalLongName" SG_ 1315 DTCI_IPC_TstFldLstClr "Diagnostic Trouble Code Information Extended - IPC : Test Failed Since Last Clear";
BA_ "SignalType" SG_ 1315 DTCI_IPC_TstFld "ENM";
BA_ "SignalLongName" SG_ 1315 DTCI_IPC_TstFld "Diagnostic Trouble Code Information Extended - IPC : Test Failed";
BA_ "SignalType" SG_ 1315 DTCI_IPC_PndngDTC "ENM";
BA_ "SignalLongName" SG_ 1315 DTCI_IPC_PndngDTC "Diagnostic Trouble Code Information Extended - IPC : Pending DTC";
BA_ "SignalType" SG_ 1315 DTCI_IPC_DTCTriggered "ENM";
BA_ "SignalLongName" SG_ 1315 DTCI_IPC_DTCTriggered "Diagnostic Trouble Code Information Extended - IPC : Diagnostic Trouble Code Triggered";
BA_ "SignalType" SG_ 1315 DTCI_IPC_WrnIndTrggrd "ENM";
BA_ "SignalLongName" SG_ 1315 DTCI_IPC_WrnIndTrggrd "Diagnostic Trouble Code Information Extended - IPC : Warning Indicator Triggered";
BA_ "SignalType" SG_ 1315 DTCI_IPC_WrnIndRqd "ENM";
BA_ "SignalLongName" SG_ 1315 DTCI_IPC_WrnIndRqd "Diagnostic Trouble Code Information Extended - IPC : Warning Indicator Requested";
BA_ "SignalLongName" SG_ 1395 DTCI_LIB1_DTCFailType "Diagnostic Trouble Code Information Extended - LIB1 : Diagnostic Trouble Code Failure Type";
BA_ "SignalType" SG_ 1395 DTCI_LIB1_CnfrmdDTC "ENM";
BA_ "SignalLongName" SG_ 1395 DTCI_LIB1_CnfrmdDTC "Diagnostic Trouble Code Information Extended - LIB1 : Confirmed DTC";
BA_ "SignalType" SG_ 1395 DTCI_LIB1_DTCFaultType "ENM";
BA_ "SignalLongName" SG_ 1395 DTCI_LIB1_DTCFaultType "Diagnostic Trouble Code Information Extended - LIB1 : Diagnostic Trouble Code Fault Type";
BA_ "SignalLongName" SG_ 1395 DTCI_LIB1_DTCNumber "Diagnostic Trouble Code Information Extended - LIB1 : Diagnostic Trouble Code Number";
BA_ "SignalLongName" SG_ 1395 DTCI_LIB1_DTCSource "Diagnostic Trouble Code Information Extended - LIB1 : Diagnostic Trouble Code Source";
BA_ "SignalType" SG_ 1395 DTCI_LIB1_TstNCmpltdOpCyc "ENM";
BA_ "SignalLongName" SG_ 1395 DTCI_LIB1_TstNCmpltdOpCyc "Diagnostic Trouble Code Information Extended - LIB1 : Test Not Completed This Operation Cycle";
BA_ "SignalType" SG_ 1395 DTCI_LIB1_TstNCmpltdLstClr "ENM";
BA_ "SignalLongName" SG_ 1395 DTCI_LIB1_TstNCmpltdLstClr "Diagnostic Trouble Code Information Extended - LIB1 : Test Not Completed Since Last Clear";
BA_ "SignalType" SG_ 1395 DTCI_LIB1_TstFldOpCyc "ENM";
BA_ "SignalLongName" SG_ 1395 DTCI_LIB1_TstFldOpCyc "Diagnostic Trouble Code Information Extended - LIB1 : Test Failed This Operation Cycle";
BA_ "SignalType" SG_ 1395 DTCI_LIB1_TstFldLstClr "ENM";
BA_ "SignalLongName" SG_ 1395 DTCI_LIB1_TstFldLstClr "Diagnostic Trouble Code Information Extended - LIB1 : Test Failed Since Last Clear";
BA_ "SignalType" SG_ 1395 DTCI_LIB1_TstFld "ENM";
BA_ "SignalLongName" SG_ 1395 DTCI_LIB1_TstFld "Diagnostic Trouble Code Information Extended - LIB1 : Test Failed";
BA_ "SignalType" SG_ 1395 DTCI_LIB1_PndngDTC "ENM";
BA_ "SignalLongName" SG_ 1395 DTCI_LIB1_PndngDTC "Diagnostic Trouble Code Information Extended - LIB1 : Pending DTC";
BA_ "SignalType" SG_ 1395 DTCI_LIB1_DTCTriggered "ENM";
BA_ "SignalLongName" SG_ 1395 DTCI_LIB1_DTCTriggered "Diagnostic Trouble Code Information Extended - LIB1 : Diagnostic Trouble Code Triggered";
BA_ "SignalType" SG_ 1395 DTCI_LIB1_WrnIndTrggrd "ENM";
BA_ "SignalLongName" SG_ 1395 DTCI_LIB1_WrnIndTrggrd "Diagnostic Trouble Code Information Extended - LIB1 : Warning Indicator Triggered";
BA_ "SignalType" SG_ 1395 DTCI_LIB1_WrnIndRqd "ENM";
BA_ "SignalLongName" SG_ 1395 DTCI_LIB1_WrnIndRqd "Diagnostic Trouble Code Information Extended - LIB1 : Warning Indicator Requested";
BA_ "SignalLongName" SG_ 1379 DTCI_LRR_HC_DTCFailType "Diagnostic Trouble Code Information Extended - LRR_HC : Diagnostic Trouble Code Failure Type";
BA_ "SignalType" SG_ 1379 DTCI_LRR_HC_CnfrmdDTC "ENM";
BA_ "SignalLongName" SG_ 1379 DTCI_LRR_HC_CnfrmdDTC "Diagnostic Trouble Code Information Extended - LRR_HC : Confirmed DTC";
BA_ "SignalType" SG_ 1379 DTCI_LRR_HC_DTCFaultType "ENM";
BA_ "SignalLongName" SG_ 1379 DTCI_LRR_HC_DTCFaultType "Diagnostic Trouble Code Information Extended - LRR_HC : Diagnostic Trouble Code Fault Type";
BA_ "SignalLongName" SG_ 1379 DTCI_LRR_HC_DTCNumber "Diagnostic Trouble Code Information Extended - LRR_HC : Diagnostic Trouble Code Number";
BA_ "SignalLongName" SG_ 1379 DTCI_LRR_HC_DTCSource "Diagnostic Trouble Code Information Extended - LRR_HC : Diagnostic Trouble Code Source";
BA_ "SignalType" SG_ 1379 DTCI_LRR_HC_TstNCmpltdOpCyc "ENM";
BA_ "SignalLongName" SG_ 1379 DTCI_LRR_HC_TstNCmpltdOpCyc "Diagnostic Trouble Code Information Extended - LRR_HC : Test Not Completed This Operation Cycle";
BA_ "SignalType" SG_ 1379 DTCI_LRR_HC_TstNCmpltdLstClr "ENM";
BA_ "SignalLongName" SG_ 1379 DTCI_LRR_HC_TstNCmpltdLstClr "Diagnostic Trouble Code Information Extended - LRR_HC : Test Not Completed Since Last Clear";
BA_ "SignalType" SG_ 1379 DTCI_LRR_HC_TstFldOpCyc "ENM";
BA_ "SignalLongName" SG_ 1379 DTCI_LRR_HC_TstFldOpCyc "Diagnostic Trouble Code Information Extended - LRR_HC : Test Failed This Operation Cycle";
BA_ "SignalType" SG_ 1379 DTCI_LRR_HC_TstFldLstClr "ENM";
BA_ "SignalLongName" SG_ 1379 DTCI_LRR_HC_TstFldLstClr "Diagnostic Trouble Code Information Extended - LRR_HC : Test Failed Since Last Clear";
BA_ "SignalType" SG_ 1379 DTCI_LRR_HC_TstFld "ENM";
BA_ "SignalLongName" SG_ 1379 DTCI_LRR_HC_TstFld "Diagnostic Trouble Code Information Extended - LRR_HC : Test Failed";
BA_ "SignalType" SG_ 1379 DTCI_LRR_HC_PndngDTC "ENM";
BA_ "SignalLongName" SG_ 1379 DTCI_LRR_HC_PndngDTC "Diagnostic Trouble Code Information Extended - LRR_HC : Pending DTC";
BA_ "SignalType" SG_ 1379 DTCI_LRR_HC_DTCTriggered "ENM";
BA_ "SignalLongName" SG_ 1379 DTCI_LRR_HC_DTCTriggered "Diagnostic Trouble Code Information Extended - LRR_HC : Diagnostic Trouble Code Triggered";
BA_ "SignalType" SG_ 1379 DTCI_LRR_HC_WrnIndTrggrd "ENM";
BA_ "SignalLongName" SG_ 1379 DTCI_LRR_HC_WrnIndTrggrd "Diagnostic Trouble Code Information Extended - LRR_HC : Warning Indicator Triggered";
BA_ "SignalType" SG_ 1379 DTCI_LRR_HC_WrnIndRqd "ENM";
BA_ "SignalLongName" SG_ 1379 DTCI_LRR_HC_WrnIndRqd "Diagnostic Trouble Code Information Extended - LRR_HC : Warning Indicator Requested";
BA_ "SignalLongName" SG_ 1136 DTCI_LRR_DTCFailType "Diagnostic Trouble Code Information Extended - LRR : Diagnostic Trouble Code Failure Type";
BA_ "SignalType" SG_ 1136 DTCI_LRR_CnfrmdDTC "ENM";
BA_ "SignalLongName" SG_ 1136 DTCI_LRR_CnfrmdDTC "Diagnostic Trouble Code Information Extended - LRR : Confirmed DTC";
BA_ "SignalType" SG_ 1136 DTCI_LRR_DTCFaultType "ENM";
BA_ "SignalLongName" SG_ 1136 DTCI_LRR_DTCFaultType "Diagnostic Trouble Code Information Extended - LRR : Diagnostic Trouble Code Fault Type";
BA_ "SignalLongName" SG_ 1136 DTCI_LRR_DTCNumber "Diagnostic Trouble Code Information Extended - LRR : Diagnostic Trouble Code Number";
BA_ "SignalLongName" SG_ 1136 DTCI_LRR_DTCSource "Diagnostic Trouble Code Information Extended - LRR : Diagnostic Trouble Code Source";
BA_ "SignalType" SG_ 1136 DTCI_LRR_TstNCmpltdOpCyc "ENM";
BA_ "SignalLongName" SG_ 1136 DTCI_LRR_TstNCmpltdOpCyc "Diagnostic Trouble Code Information Extended - LRR : Test Not Completed This Operation Cycle";
BA_ "SignalType" SG_ 1136 DTCI_LRR_TstNCmpltdLstClr "ENM";
BA_ "SignalLongName" SG_ 1136 DTCI_LRR_TstNCmpltdLstClr "Diagnostic Trouble Code Information Extended - LRR : Test Not Completed Since Last Clear";
BA_ "SignalType" SG_ 1136 DTCI_LRR_TstFldOpCyc "ENM";
BA_ "SignalLongName" SG_ 1136 DTCI_LRR_TstFldOpCyc "Diagnostic Trouble Code Information Extended - LRR : Test Failed This Operation Cycle";
BA_ "SignalType" SG_ 1136 DTCI_LRR_TstFldLstClr "ENM";
BA_ "SignalLongName" SG_ 1136 DTCI_LRR_TstFldLstClr "Diagnostic Trouble Code Information Extended - LRR : Test Failed Since Last Clear";
BA_ "SignalType" SG_ 1136 DTCI_LRR_TstFld "ENM";
BA_ "SignalLongName" SG_ 1136 DTCI_LRR_TstFld "Diagnostic Trouble Code Information Extended - LRR : Test Failed";
BA_ "SignalType" SG_ 1136 DTCI_LRR_PndngDTC "ENM";
BA_ "SignalLongName" SG_ 1136 DTCI_LRR_PndngDTC "Diagnostic Trouble Code Information Extended - LRR : Pending DTC";
BA_ "SignalType" SG_ 1136 DTCI_LRR_DTCTriggered "ENM";
BA_ "SignalLongName" SG_ 1136 DTCI_LRR_DTCTriggered "Diagnostic Trouble Code Information Extended - LRR : Diagnostic Trouble Code Triggered";
BA_ "SignalType" SG_ 1136 DTCI_LRR_WrnIndTrggrd "ENM";
BA_ "SignalLongName" SG_ 1136 DTCI_LRR_WrnIndTrggrd "Diagnostic Trouble Code Information Extended - LRR : Warning Indicator Triggered";
BA_ "SignalType" SG_ 1136 DTCI_LRR_WrnIndRqd "ENM";
BA_ "SignalLongName" SG_ 1136 DTCI_LRR_WrnIndRqd "Diagnostic Trouble Code Information Extended - LRR : Warning Indicator Requested";
BA_ "SignalLongName" SG_ 1322 DTCI_MFC_DTCFailType "Diagnostic Trouble Code Information Extended - MFC : Diagnostic Trouble Code Failure Type";
BA_ "SignalType" SG_ 1322 DTCI_MFC_CnfrmdDTC "ENM";
BA_ "SignalLongName" SG_ 1322 DTCI_MFC_CnfrmdDTC "Diagnostic Trouble Code Information Extended - MFC : Confirmed DTC";
BA_ "SignalType" SG_ 1322 DTCI_MFC_DTCFaultType "ENM";
BA_ "SignalLongName" SG_ 1322 DTCI_MFC_DTCFaultType "Diagnostic Trouble Code Information Extended - MFC : Diagnostic Trouble Code Fault Type";
BA_ "SignalLongName" SG_ 1322 DTCI_MFC_DTCNumber "Diagnostic Trouble Code Information Extended - MFC : Diagnostic Trouble Code Number";
BA_ "SignalLongName" SG_ 1322 DTCI_MFC_DTCSource "Diagnostic Trouble Code Information Extended - MFC : Diagnostic Trouble Code Source";
BA_ "SignalType" SG_ 1322 DTCI_MFC_TstNCmpltdOpCyc "ENM";
BA_ "SignalLongName" SG_ 1322 DTCI_MFC_TstNCmpltdOpCyc "Diagnostic Trouble Code Information Extended - MFC : Test Not Completed This Operation Cycle";
BA_ "SignalType" SG_ 1322 DTCI_MFC_TstNCmpltdLstClr "ENM";
BA_ "SignalLongName" SG_ 1322 DTCI_MFC_TstNCmpltdLstClr "Diagnostic Trouble Code Information Extended - MFC : Test Not Completed Since Last Clear";
BA_ "SignalType" SG_ 1322 DTCI_MFC_TstFldOpCyc "ENM";
BA_ "SignalLongName" SG_ 1322 DTCI_MFC_TstFldOpCyc "Diagnostic Trouble Code Information Extended - MFC : Test Failed This Operation Cycle";
BA_ "SignalType" SG_ 1322 DTCI_MFC_TstFldLstClr "ENM";
BA_ "SignalLongName" SG_ 1322 DTCI_MFC_TstFldLstClr "Diagnostic Trouble Code Information Extended - MFC : Test Failed Since Last Clear";
BA_ "SignalType" SG_ 1322 DTCI_MFC_TstFld "ENM";
BA_ "SignalLongName" SG_ 1322 DTCI_MFC_TstFld "Diagnostic Trouble Code Information Extended - MFC : Test Failed";
BA_ "SignalType" SG_ 1322 DTCI_MFC_PndngDTC "ENM";
BA_ "SignalLongName" SG_ 1322 DTCI_MFC_PndngDTC "Diagnostic Trouble Code Information Extended - MFC : Pending DTC";
BA_ "SignalType" SG_ 1322 DTCI_MFC_DTCTriggered "ENM";
BA_ "SignalLongName" SG_ 1322 DTCI_MFC_DTCTriggered "Diagnostic Trouble Code Information Extended - MFC : Diagnostic Trouble Code Triggered";
BA_ "SignalType" SG_ 1322 DTCI_MFC_WrnIndTrggrd "ENM";
BA_ "SignalLongName" SG_ 1322 DTCI_MFC_WrnIndTrggrd "Diagnostic Trouble Code Information Extended - MFC : Warning Indicator Triggered";
BA_ "SignalType" SG_ 1322 DTCI_MFC_WrnIndRqd "ENM";
BA_ "SignalLongName" SG_ 1322 DTCI_MFC_WrnIndRqd "Diagnostic Trouble Code Information Extended - MFC : Warning Indicator Requested";
BA_ "SignalLongName" SG_ 1137 DTCI_MRCM_L_DTCFailType "Diagnostic Trouble Code Information Extended - MRCM_L : Diagnostic Trouble Code Failure Type";
BA_ "SignalType" SG_ 1137 DTCI_MRCM_L_CnfrmdDTC "ENM";
BA_ "SignalLongName" SG_ 1137 DTCI_MRCM_L_CnfrmdDTC "Diagnostic Trouble Code Information Extended - MRCM_L : Confirmed DTC";
BA_ "SignalType" SG_ 1137 DTCI_MRCM_L_DTCFaultType "ENM";
BA_ "SignalLongName" SG_ 1137 DTCI_MRCM_L_DTCFaultType "Diagnostic Trouble Code Information Extended - MRCM_L : Diagnostic Trouble Code Fault Type";
BA_ "SignalLongName" SG_ 1137 DTCI_MRCM_L_DTCNumber "Diagnostic Trouble Code Information Extended - MRCM_L : Diagnostic Trouble Code Number";
BA_ "SignalLongName" SG_ 1137 DTCI_MRCM_L_DTCSource "Diagnostic Trouble Code Information Extended - MRCM_L : Diagnostic Trouble Code Source";
BA_ "SignalType" SG_ 1137 DTCI_MRCM_L_TstNCmpltdOpCyc "ENM";
BA_ "SignalLongName" SG_ 1137 DTCI_MRCM_L_TstNCmpltdOpCyc "Diagnostic Trouble Code Information Extended - MRCM_L : Test Not Completed This Operation Cycle";
BA_ "SignalType" SG_ 1137 DTCI_MRCM_L_TstNCmpltdLstClr "ENM";
BA_ "SignalLongName" SG_ 1137 DTCI_MRCM_L_TstNCmpltdLstClr "Diagnostic Trouble Code Information Extended - MRCM_L : Test Not Completed Since Last Clear";
BA_ "SignalType" SG_ 1137 DTCI_MRCM_L_TstFldOpCyc "ENM";
BA_ "SignalLongName" SG_ 1137 DTCI_MRCM_L_TstFldOpCyc "Diagnostic Trouble Code Information Extended - MRCM_L : Test Failed This Operation Cycle";
BA_ "SignalType" SG_ 1137 DTCI_MRCM_L_TstFldLstClr "ENM";
BA_ "SignalLongName" SG_ 1137 DTCI_MRCM_L_TstFldLstClr "Diagnostic Trouble Code Information Extended - MRCM_L : Test Failed Since Last Clear";
BA_ "SignalType" SG_ 1137 DTCI_MRCM_L_TstFld "ENM";
BA_ "SignalLongName" SG_ 1137 DTCI_MRCM_L_TstFld "Diagnostic Trouble Code Information Extended - MRCM_L : Test Failed";
BA_ "SignalType" SG_ 1137 DTCI_MRCM_L_PndngDTC "ENM";
BA_ "SignalLongName" SG_ 1137 DTCI_MRCM_L_PndngDTC "Diagnostic Trouble Code Information Extended - MRCM_L : Pending DTC";
BA_ "SignalType" SG_ 1137 DTCI_MRCM_L_DTCTriggered "ENM";
BA_ "SignalLongName" SG_ 1137 DTCI_MRCM_L_DTCTriggered "Diagnostic Trouble Code Information Extended - MRCM_L : Diagnostic Trouble Code Triggered";
BA_ "SignalType" SG_ 1137 DTCI_MRCM_L_WrnIndTrggrd "ENM";
BA_ "SignalLongName" SG_ 1137 DTCI_MRCM_L_WrnIndTrggrd "Diagnostic Trouble Code Information Extended - MRCM_L : Warning Indicator Triggered";
BA_ "SignalType" SG_ 1137 DTCI_MRCM_L_WrnIndRqd "ENM";
BA_ "SignalLongName" SG_ 1137 DTCI_MRCM_L_WrnIndRqd "Diagnostic Trouble Code Information Extended - MRCM_L : Warning Indicator Requested";
BA_ "SignalLongName" SG_ 1138 DTCI_MRCM_R_DTCFailType "Diagnostic Trouble Code Information Extended - MRCM_R : Diagnostic Trouble Code Failure Type";
BA_ "SignalType" SG_ 1138 DTCI_MRCM_R_CnfrmdDTC "ENM";
BA_ "SignalLongName" SG_ 1138 DTCI_MRCM_R_CnfrmdDTC "Diagnostic Trouble Code Information Extended - MRCM_R : Confirmed DTC";
BA_ "SignalType" SG_ 1138 DTCI_MRCM_R_DTCFaultType "ENM";
BA_ "SignalLongName" SG_ 1138 DTCI_MRCM_R_DTCFaultType "Diagnostic Trouble Code Information Extended - MRCM_R : Diagnostic Trouble Code Fault Type";
BA_ "SignalLongName" SG_ 1138 DTCI_MRCM_R_DTCNumber "Diagnostic Trouble Code Information Extended - MRCM_R : Diagnostic Trouble Code Number";
BA_ "SignalLongName" SG_ 1138 DTCI_MRCM_R_DTCSource "Diagnostic Trouble Code Information Extended - MRCM_R : Diagnostic Trouble Code Source";
BA_ "SignalType" SG_ 1138 DTCI_MRCM_R_TstNCmpltdOpCyc "ENM";
BA_ "SignalLongName" SG_ 1138 DTCI_MRCM_R_TstNCmpltdOpCyc "Diagnostic Trouble Code Information Extended - MRCM_R : Test Not Completed This Operation Cycle";
BA_ "SignalType" SG_ 1138 DTCI_MRCM_R_TstNCmpltdLstClr "ENM";
BA_ "SignalLongName" SG_ 1138 DTCI_MRCM_R_TstNCmpltdLstClr "Diagnostic Trouble Code Information Extended - MRCM_R : Test Not Completed Since Last Clear";
BA_ "SignalType" SG_ 1138 DTCI_MRCM_R_TstFldOpCyc "ENM";
BA_ "SignalLongName" SG_ 1138 DTCI_MRCM_R_TstFldOpCyc "Diagnostic Trouble Code Information Extended - MRCM_R : Test Failed This Operation Cycle";
BA_ "SignalType" SG_ 1138 DTCI_MRCM_R_TstFldLstClr "ENM";
BA_ "SignalLongName" SG_ 1138 DTCI_MRCM_R_TstFldLstClr "Diagnostic Trouble Code Information Extended - MRCM_R : Test Failed Since Last Clear";
BA_ "SignalType" SG_ 1138 DTCI_MRCM_R_TstFld "ENM";
BA_ "SignalLongName" SG_ 1138 DTCI_MRCM_R_TstFld "Diagnostic Trouble Code Information Extended - MRCM_R : Test Failed";
BA_ "SignalType" SG_ 1138 DTCI_MRCM_R_PndngDTC "ENM";
BA_ "SignalLongName" SG_ 1138 DTCI_MRCM_R_PndngDTC "Diagnostic Trouble Code Information Extended - MRCM_R : Pending DTC";
BA_ "SignalType" SG_ 1138 DTCI_MRCM_R_DTCTriggered "ENM";
BA_ "SignalLongName" SG_ 1138 DTCI_MRCM_R_DTCTriggered "Diagnostic Trouble Code Information Extended - MRCM_R : Diagnostic Trouble Code Triggered";
BA_ "SignalType" SG_ 1138 DTCI_MRCM_R_WrnIndTrggrd "ENM";
BA_ "SignalLongName" SG_ 1138 DTCI_MRCM_R_WrnIndTrggrd "Diagnostic Trouble Code Information Extended - MRCM_R : Warning Indicator Triggered";
BA_ "SignalType" SG_ 1138 DTCI_MRCM_R_WrnIndRqd "ENM";
BA_ "SignalLongName" SG_ 1138 DTCI_MRCM_R_WrnIndRqd "Diagnostic Trouble Code Information Extended - MRCM_R : Warning Indicator Requested";
BA_ "SignalLongName" SG_ 1139 DTCI_MSB1_DTCFailType "Diagnostic Trouble Code Information Extended - MSB1 : Diagnostic Trouble Code Failure Type";
BA_ "SignalType" SG_ 1139 DTCI_MSB1_CnfrmdDTC "ENM";
BA_ "SignalLongName" SG_ 1139 DTCI_MSB1_CnfrmdDTC "Diagnostic Trouble Code Information Extended - MSB1 : Confirmed DTC";
BA_ "SignalType" SG_ 1139 DTCI_MSB1_DTCFaultType "ENM";
BA_ "SignalLongName" SG_ 1139 DTCI_MSB1_DTCFaultType "Diagnostic Trouble Code Information Extended - MSB1 : Diagnostic Trouble Code Fault Type";
BA_ "SignalLongName" SG_ 1139 DTCI_MSB1_DTCNumber "Diagnostic Trouble Code Information Extended - MSB1 : Diagnostic Trouble Code Number";
BA_ "SignalLongName" SG_ 1139 DTCI_MSB1_DTCSource "Diagnostic Trouble Code Information Extended - MSB1 : Diagnostic Trouble Code Source";
BA_ "SignalType" SG_ 1139 DTCI_MSB1_TstNCmpltdOpCyc "ENM";
BA_ "SignalLongName" SG_ 1139 DTCI_MSB1_TstNCmpltdOpCyc "Diagnostic Trouble Code Information Extended - MSB1 : Test Not Completed This Operation Cycle";
BA_ "SignalType" SG_ 1139 DTCI_MSB1_TstNCmpltdLstClr "ENM";
BA_ "SignalLongName" SG_ 1139 DTCI_MSB1_TstNCmpltdLstClr "Diagnostic Trouble Code Information Extended - MSB1 : Test Not Completed Since Last Clear";
BA_ "SignalType" SG_ 1139 DTCI_MSB1_TstFldOpCyc "ENM";
BA_ "SignalLongName" SG_ 1139 DTCI_MSB1_TstFldOpCyc "Diagnostic Trouble Code Information Extended - MSB1 : Test Failed This Operation Cycle";
BA_ "SignalType" SG_ 1139 DTCI_MSB1_TstFldLstClr "ENM";
BA_ "SignalLongName" SG_ 1139 DTCI_MSB1_TstFldLstClr "Diagnostic Trouble Code Information Extended - MSB1 : Test Failed Since Last Clear";
BA_ "SignalType" SG_ 1139 DTCI_MSB1_TstFld "ENM";
BA_ "SignalLongName" SG_ 1139 DTCI_MSB1_TstFld "Diagnostic Trouble Code Information Extended - MSB1 : Test Failed";
BA_ "SignalType" SG_ 1139 DTCI_MSB1_PndngDTC "ENM";
BA_ "SignalLongName" SG_ 1139 DTCI_MSB1_PndngDTC "Diagnostic Trouble Code Information Extended - MSB1 : Pending DTC";
BA_ "SignalType" SG_ 1139 DTCI_MSB1_DTCTriggered "ENM";
BA_ "SignalLongName" SG_ 1139 DTCI_MSB1_DTCTriggered "Diagnostic Trouble Code Information Extended - MSB1 : Diagnostic Trouble Code Triggered";
BA_ "SignalType" SG_ 1139 DTCI_MSB1_WrnIndTrggrd "ENM";
BA_ "SignalLongName" SG_ 1139 DTCI_MSB1_WrnIndTrggrd "Diagnostic Trouble Code Information Extended - MSB1 : Warning Indicator Triggered";
BA_ "SignalType" SG_ 1139 DTCI_MSB1_WrnIndRqd "ENM";
BA_ "SignalLongName" SG_ 1139 DTCI_MSB1_WrnIndRqd "Diagnostic Trouble Code Information Extended - MSB1 : Warning Indicator Requested";
BA_ "SignalLongName" SG_ 1140 DTCI_MSB2_DTCFailType "Diagnostic Trouble Code Information Extended - MSB2 : Diagnostic Trouble Code Failure Type";
BA_ "SignalType" SG_ 1140 DTCI_MSB2_CnfrmdDTC "ENM";
BA_ "SignalLongName" SG_ 1140 DTCI_MSB2_CnfrmdDTC "Diagnostic Trouble Code Information Extended - MSB2 : Confirmed DTC";
BA_ "SignalType" SG_ 1140 DTCI_MSB2_DTCFaultType "ENM";
BA_ "SignalLongName" SG_ 1140 DTCI_MSB2_DTCFaultType "Diagnostic Trouble Code Information Extended - MSB2 : Diagnostic Trouble Code Fault Type";
BA_ "SignalLongName" SG_ 1140 DTCI_MSB2_DTCNumber "Diagnostic Trouble Code Information Extended - MSB2 : Diagnostic Trouble Code Number";
BA_ "SignalLongName" SG_ 1140 DTCI_MSB2_DTCSource "Diagnostic Trouble Code Information Extended - MSB2 : Diagnostic Trouble Code Source";
BA_ "SignalType" SG_ 1140 DTCI_MSB2_TstNCmpltdOpCyc "ENM";
BA_ "SignalLongName" SG_ 1140 DTCI_MSB2_TstNCmpltdOpCyc "Diagnostic Trouble Code Information Extended - MSB2 : Test Not Completed This Operation Cycle";
BA_ "SignalType" SG_ 1140 DTCI_MSB2_TstNCmpltdLstClr "ENM";
BA_ "SignalLongName" SG_ 1140 DTCI_MSB2_TstNCmpltdLstClr "Diagnostic Trouble Code Information Extended - MSB2 : Test Not Completed Since Last Clear";
BA_ "SignalType" SG_ 1140 DTCI_MSB2_TstFldOpCyc "ENM";
BA_ "SignalLongName" SG_ 1140 DTCI_MSB2_TstFldOpCyc "Diagnostic Trouble Code Information Extended - MSB2 : Test Failed This Operation Cycle";
BA_ "SignalType" SG_ 1140 DTCI_MSB2_TstFldLstClr "ENM";
BA_ "SignalLongName" SG_ 1140 DTCI_MSB2_TstFldLstClr "Diagnostic Trouble Code Information Extended - MSB2 : Test Failed Since Last Clear";
BA_ "SignalType" SG_ 1140 DTCI_MSB2_TstFld "ENM";
BA_ "SignalLongName" SG_ 1140 DTCI_MSB2_TstFld "Diagnostic Trouble Code Information Extended - MSB2 : Test Failed";
BA_ "SignalType" SG_ 1140 DTCI_MSB2_PndngDTC "ENM";
BA_ "SignalLongName" SG_ 1140 DTCI_MSB2_PndngDTC "Diagnostic Trouble Code Information Extended - MSB2 : Pending DTC";
BA_ "SignalType" SG_ 1140 DTCI_MSB2_DTCTriggered "ENM";
BA_ "SignalLongName" SG_ 1140 DTCI_MSB2_DTCTriggered "Diagnostic Trouble Code Information Extended - MSB2 : Diagnostic Trouble Code Triggered";
BA_ "SignalType" SG_ 1140 DTCI_MSB2_WrnIndTrggrd "ENM";
BA_ "SignalLongName" SG_ 1140 DTCI_MSB2_WrnIndTrggrd "Diagnostic Trouble Code Information Extended - MSB2 : Warning Indicator Triggered";
BA_ "SignalType" SG_ 1140 DTCI_MSB2_WrnIndRqd "ENM";
BA_ "SignalLongName" SG_ 1140 DTCI_MSB2_WrnIndRqd "Diagnostic Trouble Code Information Extended - MSB2 : Warning Indicator Requested";
BA_ "SignalLongName" SG_ 1141 DTCI_MSM_D_DTCFailType "Diagnostic Trouble Code Information Extended - MSM_D : Diagnostic Trouble Code Failure Type";
BA_ "SignalType" SG_ 1141 DTCI_MSM_D_CnfrmdDTC "ENM";
BA_ "SignalLongName" SG_ 1141 DTCI_MSM_D_CnfrmdDTC "Diagnostic Trouble Code Information Extended - MSM_D : Confirmed DTC";
BA_ "SignalType" SG_ 1141 DTCI_MSM_D_DTCFaultType "ENM";
BA_ "SignalLongName" SG_ 1141 DTCI_MSM_D_DTCFaultType "Diagnostic Trouble Code Information Extended - MSM_D : Diagnostic Trouble Code Fault Type";
BA_ "SignalLongName" SG_ 1141 DTCI_MSM_D_DTCNumber "Diagnostic Trouble Code Information Extended - MSM_D : Diagnostic Trouble Code Number";
BA_ "SignalLongName" SG_ 1141 DTCI_MSM_D_DTCSource "Diagnostic Trouble Code Information Extended - MSM_D : Diagnostic Trouble Code Source";
BA_ "SignalType" SG_ 1141 DTCI_MSM_D_TstNCmpltdOpCyc "ENM";
BA_ "SignalLongName" SG_ 1141 DTCI_MSM_D_TstNCmpltdOpCyc "Diagnostic Trouble Code Information Extended - MSM_D : Test Not Completed This Operation Cycle";
BA_ "SignalType" SG_ 1141 DTCI_MSM_D_TstNCmpltdLstClr "ENM";
BA_ "SignalLongName" SG_ 1141 DTCI_MSM_D_TstNCmpltdLstClr "Diagnostic Trouble Code Information Extended - MSM_D : Test Not Completed Since Last Clear";
BA_ "SignalType" SG_ 1141 DTCI_MSM_D_TstFldOpCyc "ENM";
BA_ "SignalLongName" SG_ 1141 DTCI_MSM_D_TstFldOpCyc "Diagnostic Trouble Code Information Extended - MSM_D : Test Failed This Operation Cycle";
BA_ "SignalType" SG_ 1141 DTCI_MSM_D_TstFldLstClr "ENM";
BA_ "SignalLongName" SG_ 1141 DTCI_MSM_D_TstFldLstClr "Diagnostic Trouble Code Information Extended - MSM_D : Test Failed Since Last Clear";
BA_ "SignalType" SG_ 1141 DTCI_MSM_D_TstFld "ENM";
BA_ "SignalLongName" SG_ 1141 DTCI_MSM_D_TstFld "Diagnostic Trouble Code Information Extended - MSM_D : Test Failed";
BA_ "SignalType" SG_ 1141 DTCI_MSM_D_PndngDTC "ENM";
BA_ "SignalLongName" SG_ 1141 DTCI_MSM_D_PndngDTC "Diagnostic Trouble Code Information Extended - MSM_D : Pending DTC";
BA_ "SignalType" SG_ 1141 DTCI_MSM_D_DTCTriggered "ENM";
BA_ "SignalLongName" SG_ 1141 DTCI_MSM_D_DTCTriggered "Diagnostic Trouble Code Information Extended - MSM_D : Diagnostic Trouble Code Triggered";
BA_ "SignalType" SG_ 1141 DTCI_MSM_D_WrnIndTrggrd "ENM";
BA_ "SignalLongName" SG_ 1141 DTCI_MSM_D_WrnIndTrggrd "Diagnostic Trouble Code Information Extended - MSM_D : Warning Indicator Triggered";
BA_ "SignalType" SG_ 1141 DTCI_MSM_D_WrnIndRqd "ENM";
BA_ "SignalLongName" SG_ 1141 DTCI_MSM_D_WrnIndRqd "Diagnostic Trouble Code Information Extended - MSM_D : Warning Indicator Requested";
BA_ "SignalLongName" SG_ 1142 DTCI_MSM_LR_DTCFailType "Diagnostic Trouble Code Information Extended - MSM_LR : Diagnostic Trouble Code Failure Type";
BA_ "SignalType" SG_ 1142 DTCI_MSM_LR_CnfrmdDTC "ENM";
BA_ "SignalLongName" SG_ 1142 DTCI_MSM_LR_CnfrmdDTC "Diagnostic Trouble Code Information Extended - MSM_LR : Confirmed DTC";
BA_ "SignalType" SG_ 1142 DTCI_MSM_LR_DTCFaultType "ENM";
BA_ "SignalLongName" SG_ 1142 DTCI_MSM_LR_DTCFaultType "Diagnostic Trouble Code Information Extended - MSM_LR : Diagnostic Trouble Code Fault Type";
BA_ "SignalLongName" SG_ 1142 DTCI_MSM_LR_DTCNumber "Diagnostic Trouble Code Information Extended - MSM_LR : Diagnostic Trouble Code Number";
BA_ "SignalLongName" SG_ 1142 DTCI_MSM_LR_DTCSource "Diagnostic Trouble Code Information Extended - MSM_LR : Diagnostic Trouble Code Source";
BA_ "SignalType" SG_ 1142 DTCI_MSM_LR_TstNCmpltdOpCyc "ENM";
BA_ "SignalLongName" SG_ 1142 DTCI_MSM_LR_TstNCmpltdOpCyc "Diagnostic Trouble Code Information Extended - MSM_LR : Test Not Completed This Operation Cycle";
BA_ "SignalType" SG_ 1142 DTCI_MSM_LR_TstNCmpltdLstClr "ENM";
BA_ "SignalLongName" SG_ 1142 DTCI_MSM_LR_TstNCmpltdLstClr "Diagnostic Trouble Code Information Extended - MSM_LR : Test Not Completed Since Last Clear";
BA_ "SignalType" SG_ 1142 DTCI_MSM_LR_TstFldOpCyc "ENM";
BA_ "SignalLongName" SG_ 1142 DTCI_MSM_LR_TstFldOpCyc "Diagnostic Trouble Code Information Extended - MSM_LR : Test Failed This Operation Cycle";
BA_ "SignalType" SG_ 1142 DTCI_MSM_LR_TstFldLstClr "ENM";
BA_ "SignalLongName" SG_ 1142 DTCI_MSM_LR_TstFldLstClr "Diagnostic Trouble Code Information Extended - MSM_LR : Test Failed Since Last Clear";
BA_ "SignalType" SG_ 1142 DTCI_MSM_LR_TstFld "ENM";
BA_ "SignalLongName" SG_ 1142 DTCI_MSM_LR_TstFld "Diagnostic Trouble Code Information Extended - MSM_LR : Test Failed";
BA_ "SignalType" SG_ 1142 DTCI_MSM_LR_PndngDTC "ENM";
BA_ "SignalLongName" SG_ 1142 DTCI_MSM_LR_PndngDTC "Diagnostic Trouble Code Information Extended - MSM_LR : Pending DTC";
BA_ "SignalType" SG_ 1142 DTCI_MSM_LR_DTCTriggered "ENM";
BA_ "SignalLongName" SG_ 1142 DTCI_MSM_LR_DTCTriggered "Diagnostic Trouble Code Information Extended - MSM_LR : Diagnostic Trouble Code Triggered";
BA_ "SignalType" SG_ 1142 DTCI_MSM_LR_WrnIndTrggrd "ENM";
BA_ "SignalLongName" SG_ 1142 DTCI_MSM_LR_WrnIndTrggrd "Diagnostic Trouble Code Information Extended - MSM_LR : Warning Indicator Triggered";
BA_ "SignalType" SG_ 1142 DTCI_MSM_LR_WrnIndRqd "ENM";
BA_ "SignalLongName" SG_ 1142 DTCI_MSM_LR_WrnIndRqd "Diagnostic Trouble Code Information Extended - MSM_LR : Warning Indicator Requested";
BA_ "SignalLongName" SG_ 1143 DTCI_MSM_P_DTCFailType "Diagnostic Trouble Code Information Extended - MSM_P : Diagnostic Trouble Code Failure Type";
BA_ "SignalType" SG_ 1143 DTCI_MSM_P_CnfrmdDTC "ENM";
BA_ "SignalLongName" SG_ 1143 DTCI_MSM_P_CnfrmdDTC "Diagnostic Trouble Code Information Extended - MSM_P : Confirmed DTC";
BA_ "SignalType" SG_ 1143 DTCI_MSM_P_DTCFaultType "ENM";
BA_ "SignalLongName" SG_ 1143 DTCI_MSM_P_DTCFaultType "Diagnostic Trouble Code Information Extended - MSM_P : Diagnostic Trouble Code Fault Type";
BA_ "SignalLongName" SG_ 1143 DTCI_MSM_P_DTCNumber "Diagnostic Trouble Code Information Extended - MSM_P : Diagnostic Trouble Code Number";
BA_ "SignalLongName" SG_ 1143 DTCI_MSM_P_DTCSource "Diagnostic Trouble Code Information Extended - MSM_P : Diagnostic Trouble Code Source";
BA_ "SignalType" SG_ 1143 DTCI_MSM_P_TstNCmpltdOpCyc "ENM";
BA_ "SignalLongName" SG_ 1143 DTCI_MSM_P_TstNCmpltdOpCyc "Diagnostic Trouble Code Information Extended - MSM_P : Test Not Completed This Operation Cycle";
BA_ "SignalType" SG_ 1143 DTCI_MSM_P_TstNCmpltdLstClr "ENM";
BA_ "SignalLongName" SG_ 1143 DTCI_MSM_P_TstNCmpltdLstClr "Diagnostic Trouble Code Information Extended - MSM_P : Test Not Completed Since Last Clear";
BA_ "SignalType" SG_ 1143 DTCI_MSM_P_TstFldOpCyc "ENM";
BA_ "SignalLongName" SG_ 1143 DTCI_MSM_P_TstFldOpCyc "Diagnostic Trouble Code Information Extended - MSM_P : Test Failed This Operation Cycle";
BA_ "SignalType" SG_ 1143 DTCI_MSM_P_TstFldLstClr "ENM";
BA_ "SignalLongName" SG_ 1143 DTCI_MSM_P_TstFldLstClr "Diagnostic Trouble Code Information Extended - MSM_P : Test Failed Since Last Clear";
BA_ "SignalType" SG_ 1143 DTCI_MSM_P_TstFld "ENM";
BA_ "SignalLongName" SG_ 1143 DTCI_MSM_P_TstFld "Diagnostic Trouble Code Information Extended - MSM_P : Test Failed";
BA_ "SignalType" SG_ 1143 DTCI_MSM_P_PndngDTC "ENM";
BA_ "SignalLongName" SG_ 1143 DTCI_MSM_P_PndngDTC "Diagnostic Trouble Code Information Extended - MSM_P : Pending DTC";
BA_ "SignalType" SG_ 1143 DTCI_MSM_P_DTCTriggered "ENM";
BA_ "SignalLongName" SG_ 1143 DTCI_MSM_P_DTCTriggered "Diagnostic Trouble Code Information Extended - MSM_P : Diagnostic Trouble Code Triggered";
BA_ "SignalType" SG_ 1143 DTCI_MSM_P_WrnIndTrggrd "ENM";
BA_ "SignalLongName" SG_ 1143 DTCI_MSM_P_WrnIndTrggrd "Diagnostic Trouble Code Information Extended - MSM_P : Warning Indicator Triggered";
BA_ "SignalType" SG_ 1143 DTCI_MSM_P_WrnIndRqd "ENM";
BA_ "SignalLongName" SG_ 1143 DTCI_MSM_P_WrnIndRqd "Diagnostic Trouble Code Information Extended - MSM_P : Warning Indicator Requested";
BA_ "SignalLongName" SG_ 1144 DTCI_MSM_RR_DTCFailType "Diagnostic Trouble Code Information Extended - MSM_RR : Diagnostic Trouble Code Failure Type";
BA_ "SignalType" SG_ 1144 DTCI_MSM_RR_CnfrmdDTC "ENM";
BA_ "SignalLongName" SG_ 1144 DTCI_MSM_RR_CnfrmdDTC "Diagnostic Trouble Code Information Extended - MSM_RR : Confirmed DTC";
BA_ "SignalType" SG_ 1144 DTCI_MSM_RR_DTCFaultType "ENM";
BA_ "SignalLongName" SG_ 1144 DTCI_MSM_RR_DTCFaultType "Diagnostic Trouble Code Information Extended - MSM_RR : Diagnostic Trouble Code Fault Type";
BA_ "SignalLongName" SG_ 1144 DTCI_MSM_RR_DTCNumber "Diagnostic Trouble Code Information Extended - MSM_RR : Diagnostic Trouble Code Number";
BA_ "SignalLongName" SG_ 1144 DTCI_MSM_RR_DTCSource "Diagnostic Trouble Code Information Extended - MSM_RR : Diagnostic Trouble Code Source";
BA_ "SignalType" SG_ 1144 DTCI_MSM_RR_TstNCmpltdOpCyc "ENM";
BA_ "SignalLongName" SG_ 1144 DTCI_MSM_RR_TstNCmpltdOpCyc "Diagnostic Trouble Code Information Extended - MSM_RR : Test Not Completed This Operation Cycle";
BA_ "SignalType" SG_ 1144 DTCI_MSM_RR_TstNCmpltdLstClr "ENM";
BA_ "SignalLongName" SG_ 1144 DTCI_MSM_RR_TstNCmpltdLstClr "Diagnostic Trouble Code Information Extended - MSM_RR : Test Not Completed Since Last Clear";
BA_ "SignalType" SG_ 1144 DTCI_MSM_RR_TstFldOpCyc "ENM";
BA_ "SignalLongName" SG_ 1144 DTCI_MSM_RR_TstFldOpCyc "Diagnostic Trouble Code Information Extended - MSM_RR : Test Failed This Operation Cycle";
BA_ "SignalType" SG_ 1144 DTCI_MSM_RR_TstFldLstClr "ENM";
BA_ "SignalLongName" SG_ 1144 DTCI_MSM_RR_TstFldLstClr "Diagnostic Trouble Code Information Extended - MSM_RR : Test Failed Since Last Clear";
BA_ "SignalType" SG_ 1144 DTCI_MSM_RR_TstFld "ENM";
BA_ "SignalLongName" SG_ 1144 DTCI_MSM_RR_TstFld "Diagnostic Trouble Code Information Extended - MSM_RR : Test Failed";
BA_ "SignalType" SG_ 1144 DTCI_MSM_RR_PndngDTC "ENM";
BA_ "SignalLongName" SG_ 1144 DTCI_MSM_RR_PndngDTC "Diagnostic Trouble Code Information Extended - MSM_RR : Pending DTC";
BA_ "SignalType" SG_ 1144 DTCI_MSM_RR_DTCTriggered "ENM";
BA_ "SignalLongName" SG_ 1144 DTCI_MSM_RR_DTCTriggered "Diagnostic Trouble Code Information Extended - MSM_RR : Diagnostic Trouble Code Triggered";
BA_ "SignalType" SG_ 1144 DTCI_MSM_RR_WrnIndTrggrd "ENM";
BA_ "SignalLongName" SG_ 1144 DTCI_MSM_RR_WrnIndTrggrd "Diagnostic Trouble Code Information Extended - MSM_RR : Warning Indicator Triggered";
BA_ "SignalType" SG_ 1144 DTCI_MSM_RR_WrnIndRqd "ENM";
BA_ "SignalLongName" SG_ 1144 DTCI_MSM_RR_WrnIndRqd "Diagnostic Trouble Code Information Extended - MSM_RR : Warning Indicator Requested";
BA_ "SignalLongName" SG_ 1145 DTCI_MTCM_L_DTCFailType "Diagnostic Trouble Code Information Extended - MTCM_L : Diagnostic Trouble Code Failure Type";
BA_ "SignalType" SG_ 1145 DTCI_MTCM_L_CnfrmdDTC "ENM";
BA_ "SignalLongName" SG_ 1145 DTCI_MTCM_L_CnfrmdDTC "Diagnostic Trouble Code Information Extended - MTCM_L : Confirmed DTC";
BA_ "SignalType" SG_ 1145 DTCI_MTCM_L_DTCFaultType "ENM";
BA_ "SignalLongName" SG_ 1145 DTCI_MTCM_L_DTCFaultType "Diagnostic Trouble Code Information Extended - MTCM_L : Diagnostic Trouble Code Fault Type";
BA_ "SignalLongName" SG_ 1145 DTCI_MTCM_L_DTCNumber "Diagnostic Trouble Code Information Extended - MTCM_L : Diagnostic Trouble Code Number";
BA_ "SignalLongName" SG_ 1145 DTCI_MTCM_L_DTCSource "Diagnostic Trouble Code Information Extended - MTCM_L : Diagnostic Trouble Code Source";
BA_ "SignalType" SG_ 1145 DTCI_MTCM_L_TstNCmpltdOpCyc "ENM";
BA_ "SignalLongName" SG_ 1145 DTCI_MTCM_L_TstNCmpltdOpCyc "Diagnostic Trouble Code Information Extended - MTCM_L : Test Not Completed This Operation Cycle";
BA_ "SignalType" SG_ 1145 DTCI_MTCM_L_TstNCmpltdLstClr "ENM";
BA_ "SignalLongName" SG_ 1145 DTCI_MTCM_L_TstNCmpltdLstClr "Diagnostic Trouble Code Information Extended - MTCM_L : Test Not Completed Since Last Clear";
BA_ "SignalType" SG_ 1145 DTCI_MTCM_L_TstFldOpCyc "ENM";
BA_ "SignalLongName" SG_ 1145 DTCI_MTCM_L_TstFldOpCyc "Diagnostic Trouble Code Information Extended - MTCM_L : Test Failed This Operation Cycle";
BA_ "SignalType" SG_ 1145 DTCI_MTCM_L_TstFldLstClr "ENM";
BA_ "SignalLongName" SG_ 1145 DTCI_MTCM_L_TstFldLstClr "Diagnostic Trouble Code Information Extended - MTCM_L : Test Failed Since Last Clear";
BA_ "SignalType" SG_ 1145 DTCI_MTCM_L_TstFld "ENM";
BA_ "SignalLongName" SG_ 1145 DTCI_MTCM_L_TstFld "Diagnostic Trouble Code Information Extended - MTCM_L : Test Failed";
BA_ "SignalType" SG_ 1145 DTCI_MTCM_L_PndngDTC "ENM";
BA_ "SignalLongName" SG_ 1145 DTCI_MTCM_L_PndngDTC "Diagnostic Trouble Code Information Extended - MTCM_L : Pending DTC";
BA_ "SignalType" SG_ 1145 DTCI_MTCM_L_DTCTriggered "ENM";
BA_ "SignalLongName" SG_ 1145 DTCI_MTCM_L_DTCTriggered "Diagnostic Trouble Code Information Extended - MTCM_L : Diagnostic Trouble Code Triggered";
BA_ "SignalType" SG_ 1145 DTCI_MTCM_L_WrnIndTrggrd "ENM";
BA_ "SignalLongName" SG_ 1145 DTCI_MTCM_L_WrnIndTrggrd "Diagnostic Trouble Code Information Extended - MTCM_L : Warning Indicator Triggered";
BA_ "SignalType" SG_ 1145 DTCI_MTCM_L_WrnIndRqd "ENM";
BA_ "SignalLongName" SG_ 1145 DTCI_MTCM_L_WrnIndRqd "Diagnostic Trouble Code Information Extended - MTCM_L : Warning Indicator Requested";
BA_ "SignalLongName" SG_ 1146 DTCI_MTCM_R_DTCFailType "Diagnostic Trouble Code Information Extended - MTCM_R : Diagnostic Trouble Code Failure Type";
BA_ "SignalType" SG_ 1146 DTCI_MTCM_R_CnfrmdDTC "ENM";
BA_ "SignalLongName" SG_ 1146 DTCI_MTCM_R_CnfrmdDTC "Diagnostic Trouble Code Information Extended - MTCM_R : Confirmed DTC";
BA_ "SignalType" SG_ 1146 DTCI_MTCM_R_DTCFaultType "ENM";
BA_ "SignalLongName" SG_ 1146 DTCI_MTCM_R_DTCFaultType "Diagnostic Trouble Code Information Extended - MTCM_R : Diagnostic Trouble Code Fault Type";
BA_ "SignalLongName" SG_ 1146 DTCI_MTCM_R_DTCNumber "Diagnostic Trouble Code Information Extended - MTCM_R : Diagnostic Trouble Code Number";
BA_ "SignalLongName" SG_ 1146 DTCI_MTCM_R_DTCSource "Diagnostic Trouble Code Information Extended - MTCM_R : Diagnostic Trouble Code Source";
BA_ "SignalType" SG_ 1146 DTCI_MTCM_R_TstNCmpltdOpCyc "ENM";
BA_ "SignalLongName" SG_ 1146 DTCI_MTCM_R_TstNCmpltdOpCyc "Diagnostic Trouble Code Information Extended - MTCM_R : Test Not Completed This Operation Cycle";
BA_ "SignalType" SG_ 1146 DTCI_MTCM_R_TstNCmpltdLstClr "ENM";
BA_ "SignalLongName" SG_ 1146 DTCI_MTCM_R_TstNCmpltdLstClr "Diagnostic Trouble Code Information Extended - MTCM_R : Test Not Completed Since Last Clear";
BA_ "SignalType" SG_ 1146 DTCI_MTCM_R_TstFldOpCyc "ENM";
BA_ "SignalLongName" SG_ 1146 DTCI_MTCM_R_TstFldOpCyc "Diagnostic Trouble Code Information Extended - MTCM_R : Test Failed This Operation Cycle";
BA_ "SignalType" SG_ 1146 DTCI_MTCM_R_TstFldLstClr "ENM";
BA_ "SignalLongName" SG_ 1146 DTCI_MTCM_R_TstFldLstClr "Diagnostic Trouble Code Information Extended - MTCM_R : Test Failed Since Last Clear";
BA_ "SignalType" SG_ 1146 DTCI_MTCM_R_TstFld "ENM";
BA_ "SignalLongName" SG_ 1146 DTCI_MTCM_R_TstFld "Diagnostic Trouble Code Information Extended - MTCM_R : Test Failed";
BA_ "SignalType" SG_ 1146 DTCI_MTCM_R_PndngDTC "ENM";
BA_ "SignalLongName" SG_ 1146 DTCI_MTCM_R_PndngDTC "Diagnostic Trouble Code Information Extended - MTCM_R : Pending DTC";
BA_ "SignalType" SG_ 1146 DTCI_MTCM_R_DTCTriggered "ENM";
BA_ "SignalLongName" SG_ 1146 DTCI_MTCM_R_DTCTriggered "Diagnostic Trouble Code Information Extended - MTCM_R : Diagnostic Trouble Code Triggered";
BA_ "SignalType" SG_ 1146 DTCI_MTCM_R_WrnIndTrggrd "ENM";
BA_ "SignalLongName" SG_ 1146 DTCI_MTCM_R_WrnIndTrggrd "Diagnostic Trouble Code Information Extended - MTCM_R : Warning Indicator Triggered";
BA_ "SignalType" SG_ 1146 DTCI_MTCM_R_WrnIndRqd "ENM";
BA_ "SignalLongName" SG_ 1146 DTCI_MTCM_R_WrnIndRqd "Diagnostic Trouble Code Information Extended - MTCM_R : Warning Indicator Requested";
BA_ "SignalLongName" SG_ 1147 DTCI_NVM_DTCFailType "Diagnostic Trouble Code Information Extended - NVM : Diagnostic Trouble Code Failure Type";
BA_ "SignalType" SG_ 1147 DTCI_NVM_CnfrmdDTC "ENM";
BA_ "SignalLongName" SG_ 1147 DTCI_NVM_CnfrmdDTC "Diagnostic Trouble Code Information Extended - NVM : Confirmed DTC";
BA_ "SignalType" SG_ 1147 DTCI_NVM_DTCFaultType "ENM";
BA_ "SignalLongName" SG_ 1147 DTCI_NVM_DTCFaultType "Diagnostic Trouble Code Information Extended - NVM : Diagnostic Trouble Code Fault Type";
BA_ "SignalLongName" SG_ 1147 DTCI_NVM_DTCNumber "Diagnostic Trouble Code Information Extended - NVM : Diagnostic Trouble Code Number";
BA_ "SignalLongName" SG_ 1147 DTCI_NVM_DTCSource "Diagnostic Trouble Code Information Extended - NVM : Diagnostic Trouble Code Source";
BA_ "SignalType" SG_ 1147 DTCI_NVM_TstNCmpltdOpCyc "ENM";
BA_ "SignalLongName" SG_ 1147 DTCI_NVM_TstNCmpltdOpCyc "Diagnostic Trouble Code Information Extended - NVM : Test Not Completed This Operation Cycle";
BA_ "SignalType" SG_ 1147 DTCI_NVM_TstNCmpltdLstClr "ENM";
BA_ "SignalLongName" SG_ 1147 DTCI_NVM_TstNCmpltdLstClr "Diagnostic Trouble Code Information Extended - NVM : Test Not Completed Since Last Clear";
BA_ "SignalType" SG_ 1147 DTCI_NVM_TstFldOpCyc "ENM";
BA_ "SignalLongName" SG_ 1147 DTCI_NVM_TstFldOpCyc "Diagnostic Trouble Code Information Extended - NVM : Test Failed This Operation Cycle";
BA_ "SignalType" SG_ 1147 DTCI_NVM_TstFldLstClr "ENM";
BA_ "SignalLongName" SG_ 1147 DTCI_NVM_TstFldLstClr "Diagnostic Trouble Code Information Extended - NVM : Test Failed Since Last Clear";
BA_ "SignalType" SG_ 1147 DTCI_NVM_TstFld "ENM";
BA_ "SignalLongName" SG_ 1147 DTCI_NVM_TstFld "Diagnostic Trouble Code Information Extended - NVM : Test Failed";
BA_ "SignalType" SG_ 1147 DTCI_NVM_PndngDTC "ENM";
BA_ "SignalLongName" SG_ 1147 DTCI_NVM_PndngDTC "Diagnostic Trouble Code Information Extended - NVM : Pending DTC";
BA_ "SignalType" SG_ 1147 DTCI_NVM_DTCTriggered "ENM";
BA_ "SignalLongName" SG_ 1147 DTCI_NVM_DTCTriggered "Diagnostic Trouble Code Information Extended - NVM : Diagnostic Trouble Code Triggered";
BA_ "SignalType" SG_ 1147 DTCI_NVM_WrnIndTrggrd "ENM";
BA_ "SignalLongName" SG_ 1147 DTCI_NVM_WrnIndTrggrd "Diagnostic Trouble Code Information Extended - NVM : Warning Indicator Triggered";
BA_ "SignalType" SG_ 1147 DTCI_NVM_WrnIndRqd "ENM";
BA_ "SignalLongName" SG_ 1147 DTCI_NVM_WrnIndRqd "Diagnostic Trouble Code Information Extended - NVM : Warning Indicator Requested";
BA_ "SignalLongName" SG_ 1148 DTCI_PA_DTCFailType "Diagnostic Trouble Code Information Extended - PA : Diagnostic Trouble Code Failure Type";
BA_ "SignalType" SG_ 1148 DTCI_PA_CnfrmdDTC "ENM";
BA_ "SignalLongName" SG_ 1148 DTCI_PA_CnfrmdDTC "Diagnostic Trouble Code Information Extended - PA : Confirmed DTC";
BA_ "SignalType" SG_ 1148 DTCI_PA_DTCFaultType "ENM";
BA_ "SignalLongName" SG_ 1148 DTCI_PA_DTCFaultType "Diagnostic Trouble Code Information Extended - PA : Diagnostic Trouble Code Fault Type";
BA_ "SignalLongName" SG_ 1148 DTCI_PA_DTCNumber "Diagnostic Trouble Code Information Extended - PA : Diagnostic Trouble Code Number";
BA_ "SignalLongName" SG_ 1148 DTCI_PA_DTCSource "Diagnostic Trouble Code Information Extended - PA : Diagnostic Trouble Code Source";
BA_ "SignalType" SG_ 1148 DTCI_PA_TstNCmpltdOpCyc "ENM";
BA_ "SignalLongName" SG_ 1148 DTCI_PA_TstNCmpltdOpCyc "Diagnostic Trouble Code Information Extended - PA : Test Not Completed This Operation Cycle";
BA_ "SignalType" SG_ 1148 DTCI_PA_TstNCmpltdLstClr "ENM";
BA_ "SignalLongName" SG_ 1148 DTCI_PA_TstNCmpltdLstClr "Diagnostic Trouble Code Information Extended - PA : Test Not Completed Since Last Clear";
BA_ "SignalType" SG_ 1148 DTCI_PA_TstFldOpCyc "ENM";
BA_ "SignalLongName" SG_ 1148 DTCI_PA_TstFldOpCyc "Diagnostic Trouble Code Information Extended - PA : Test Failed This Operation Cycle";
BA_ "SignalType" SG_ 1148 DTCI_PA_TstFldLstClr "ENM";
BA_ "SignalLongName" SG_ 1148 DTCI_PA_TstFldLstClr "Diagnostic Trouble Code Information Extended - PA : Test Failed Since Last Clear";
BA_ "SignalType" SG_ 1148 DTCI_PA_TstFld "ENM";
BA_ "SignalLongName" SG_ 1148 DTCI_PA_TstFld "Diagnostic Trouble Code Information Extended - PA : Test Failed";
BA_ "SignalType" SG_ 1148 DTCI_PA_PndngDTC "ENM";
BA_ "SignalLongName" SG_ 1148 DTCI_PA_PndngDTC "Diagnostic Trouble Code Information Extended - PA : Pending DTC";
BA_ "SignalType" SG_ 1148 DTCI_PA_DTCTriggered "ENM";
BA_ "SignalLongName" SG_ 1148 DTCI_PA_DTCTriggered "Diagnostic Trouble Code Information Extended - PA : Diagnostic Trouble Code Triggered";
BA_ "SignalType" SG_ 1148 DTCI_PA_WrnIndTrggrd "ENM";
BA_ "SignalLongName" SG_ 1148 DTCI_PA_WrnIndTrggrd "Diagnostic Trouble Code Information Extended - PA : Warning Indicator Triggered";
BA_ "SignalType" SG_ 1148 DTCI_PA_WrnIndRqd "ENM";
BA_ "SignalLongName" SG_ 1148 DTCI_PA_WrnIndRqd "Diagnostic Trouble Code Information Extended - PA : Warning Indicator Requested";
BA_ "SignalLongName" SG_ 1323 DTCI_PDR_DTCFailType "Diagnostic Trouble Code Information Extended - PDR : Diagnostic Trouble Code Failure Type";
BA_ "SignalType" SG_ 1323 DTCI_PDR_CnfrmdDTC "ENM";
BA_ "SignalLongName" SG_ 1323 DTCI_PDR_CnfrmdDTC "Diagnostic Trouble Code Information Extended - PDR : Confirmed DTC";
BA_ "SignalType" SG_ 1323 DTCI_PDR_DTCFaultType "ENM";
BA_ "SignalLongName" SG_ 1323 DTCI_PDR_DTCFaultType "Diagnostic Trouble Code Information Extended - PDR : Diagnostic Trouble Code Fault Type";
BA_ "SignalLongName" SG_ 1323 DTCI_PDR_DTCNumber "Diagnostic Trouble Code Information Extended - PDR : Diagnostic Trouble Code Number";
BA_ "SignalLongName" SG_ 1323 DTCI_PDR_DTCSource "Diagnostic Trouble Code Information Extended - PDR : Diagnostic Trouble Code Source";
BA_ "SignalType" SG_ 1323 DTCI_PDR_TstNCmpltdOpCyc "ENM";
BA_ "SignalLongName" SG_ 1323 DTCI_PDR_TstNCmpltdOpCyc "Diagnostic Trouble Code Information Extended - PDR : Test Not Completed This Operation Cycle";
BA_ "SignalType" SG_ 1323 DTCI_PDR_TstNCmpltdLstClr "ENM";
BA_ "SignalLongName" SG_ 1323 DTCI_PDR_TstNCmpltdLstClr "Diagnostic Trouble Code Information Extended - PDR : Test Not Completed Since Last Clear";
BA_ "SignalType" SG_ 1323 DTCI_PDR_TstFldOpCyc "ENM";
BA_ "SignalLongName" SG_ 1323 DTCI_PDR_TstFldOpCyc "Diagnostic Trouble Code Information Extended - PDR : Test Failed This Operation Cycle";
BA_ "SignalType" SG_ 1323 DTCI_PDR_TstFldLstClr "ENM";
BA_ "SignalLongName" SG_ 1323 DTCI_PDR_TstFldLstClr "Diagnostic Trouble Code Information Extended - PDR : Test Failed Since Last Clear";
BA_ "SignalType" SG_ 1323 DTCI_PDR_TstFld "ENM";
BA_ "SignalLongName" SG_ 1323 DTCI_PDR_TstFld "Diagnostic Trouble Code Information Extended - PDR : Test Failed";
BA_ "SignalType" SG_ 1323 DTCI_PDR_PndngDTC "ENM";
BA_ "SignalLongName" SG_ 1323 DTCI_PDR_PndngDTC "Diagnostic Trouble Code Information Extended - PDR : Pending DTC";
BA_ "SignalType" SG_ 1323 DTCI_PDR_DTCTriggered "ENM";
BA_ "SignalLongName" SG_ 1323 DTCI_PDR_DTCTriggered "Diagnostic Trouble Code Information Extended - PDR : Diagnostic Trouble Code Triggered";
BA_ "SignalType" SG_ 1323 DTCI_PDR_WrnIndTrggrd "ENM";
BA_ "SignalLongName" SG_ 1323 DTCI_PDR_WrnIndTrggrd "Diagnostic Trouble Code Information Extended - PDR : Warning Indicator Triggered";
BA_ "SignalType" SG_ 1323 DTCI_PDR_WrnIndRqd "ENM";
BA_ "SignalLongName" SG_ 1323 DTCI_PDR_WrnIndRqd "Diagnostic Trouble Code Information Extended - PDR : Warning Indicator Requested";
BA_ "SignalLongName" SG_ 1149 DTCI_PTM_DTCFailType "Diagnostic Trouble Code Information Extended - PTM : Diagnostic Trouble Code Failure Type";
BA_ "SignalType" SG_ 1149 DTCI_PTM_CnfrmdDTC "ENM";
BA_ "SignalLongName" SG_ 1149 DTCI_PTM_CnfrmdDTC "Diagnostic Trouble Code Information Extended - PTM : Confirmed DTC";
BA_ "SignalType" SG_ 1149 DTCI_PTM_DTCFaultType "ENM";
BA_ "SignalLongName" SG_ 1149 DTCI_PTM_DTCFaultType "Diagnostic Trouble Code Information Extended - PTM : Diagnostic Trouble Code Fault Type";
BA_ "SignalLongName" SG_ 1149 DTCI_PTM_DTCNumber "Diagnostic Trouble Code Information Extended - PTM : Diagnostic Trouble Code Number";
BA_ "SignalLongName" SG_ 1149 DTCI_PTM_DTCSource "Diagnostic Trouble Code Information Extended - PTM : Diagnostic Trouble Code Source";
BA_ "SignalType" SG_ 1149 DTCI_PTM_TstNCmpltdOpCyc "ENM";
BA_ "SignalLongName" SG_ 1149 DTCI_PTM_TstNCmpltdOpCyc "Diagnostic Trouble Code Information Extended - PTM : Test Not Completed This Operation Cycle";
BA_ "SignalType" SG_ 1149 DTCI_PTM_TstNCmpltdLstClr "ENM";
BA_ "SignalLongName" SG_ 1149 DTCI_PTM_TstNCmpltdLstClr "Diagnostic Trouble Code Information Extended - PTM : Test Not Completed Since Last Clear";
BA_ "SignalType" SG_ 1149 DTCI_PTM_TstFldOpCyc "ENM";
BA_ "SignalLongName" SG_ 1149 DTCI_PTM_TstFldOpCyc "Diagnostic Trouble Code Information Extended - PTM : Test Failed This Operation Cycle";
BA_ "SignalType" SG_ 1149 DTCI_PTM_TstFldLstClr "ENM";
BA_ "SignalLongName" SG_ 1149 DTCI_PTM_TstFldLstClr "Diagnostic Trouble Code Information Extended - PTM : Test Failed Since Last Clear";
BA_ "SignalType" SG_ 1149 DTCI_PTM_TstFld "ENM";
BA_ "SignalLongName" SG_ 1149 DTCI_PTM_TstFld "Diagnostic Trouble Code Information Extended - PTM : Test Failed";
BA_ "SignalType" SG_ 1149 DTCI_PTM_PndngDTC "ENM";
BA_ "SignalLongName" SG_ 1149 DTCI_PTM_PndngDTC "Diagnostic Trouble Code Information Extended - PTM : Pending DTC";
BA_ "SignalType" SG_ 1149 DTCI_PTM_DTCTriggered "ENM";
BA_ "SignalLongName" SG_ 1149 DTCI_PTM_DTCTriggered "Diagnostic Trouble Code Information Extended - PTM : Diagnostic Trouble Code Triggered";
BA_ "SignalType" SG_ 1149 DTCI_PTM_WrnIndTrggrd "ENM";
BA_ "SignalLongName" SG_ 1149 DTCI_PTM_WrnIndTrggrd "Diagnostic Trouble Code Information Extended - PTM : Warning Indicator Triggered";
BA_ "SignalType" SG_ 1149 DTCI_PTM_WrnIndRqd "ENM";
BA_ "SignalLongName" SG_ 1149 DTCI_PTM_WrnIndRqd "Diagnostic Trouble Code Information Extended - PTM : Warning Indicator Requested";
BA_ "SignalLongName" SG_ 1150 DTCI_RDCM_DTCFailType "Diagnostic Trouble Code Information Extended - RDCM : Diagnostic Trouble Code Failure Type";
BA_ "SignalType" SG_ 1150 DTCI_RDCM_CnfrmdDTC "ENM";
BA_ "SignalLongName" SG_ 1150 DTCI_RDCM_CnfrmdDTC "Diagnostic Trouble Code Information Extended - RDCM : Confirmed DTC";
BA_ "SignalType" SG_ 1150 DTCI_RDCM_DTCFaultType "ENM";
BA_ "SignalLongName" SG_ 1150 DTCI_RDCM_DTCFaultType "Diagnostic Trouble Code Information Extended - RDCM : Diagnostic Trouble Code Fault Type";
BA_ "SignalLongName" SG_ 1150 DTCI_RDCM_DTCNumber "Diagnostic Trouble Code Information Extended - RDCM : Diagnostic Trouble Code Number";
BA_ "SignalLongName" SG_ 1150 DTCI_RDCM_DTCSource "Diagnostic Trouble Code Information Extended - RDCM : Diagnostic Trouble Code Source";
BA_ "SignalType" SG_ 1150 DTCI_RDCM_TstNCmpltdOpCyc "ENM";
BA_ "SignalLongName" SG_ 1150 DTCI_RDCM_TstNCmpltdOpCyc "Diagnostic Trouble Code Information Extended - RDCM : Test Not Completed This Operation Cycle";
BA_ "SignalType" SG_ 1150 DTCI_RDCM_TstNCmpltdLstClr "ENM";
BA_ "SignalLongName" SG_ 1150 DTCI_RDCM_TstNCmpltdLstClr "Diagnostic Trouble Code Information Extended - RDCM : Test Not Completed Since Last Clear";
BA_ "SignalType" SG_ 1150 DTCI_RDCM_TstFldOpCyc "ENM";
BA_ "SignalLongName" SG_ 1150 DTCI_RDCM_TstFldOpCyc "Diagnostic Trouble Code Information Extended - RDCM : Test Failed This Operation Cycle";
BA_ "SignalType" SG_ 1150 DTCI_RDCM_TstFldLstClr "ENM";
BA_ "SignalLongName" SG_ 1150 DTCI_RDCM_TstFldLstClr "Diagnostic Trouble Code Information Extended - RDCM : Test Failed Since Last Clear";
BA_ "SignalType" SG_ 1150 DTCI_RDCM_TstFld "ENM";
BA_ "SignalLongName" SG_ 1150 DTCI_RDCM_TstFld "Diagnostic Trouble Code Information Extended - RDCM : Test Failed";
BA_ "SignalType" SG_ 1150 DTCI_RDCM_PndngDTC "ENM";
BA_ "SignalLongName" SG_ 1150 DTCI_RDCM_PndngDTC "Diagnostic Trouble Code Information Extended - RDCM : Pending DTC";
BA_ "SignalType" SG_ 1150 DTCI_RDCM_DTCTriggered "ENM";
BA_ "SignalLongName" SG_ 1150 DTCI_RDCM_DTCTriggered "Diagnostic Trouble Code Information Extended - RDCM : Diagnostic Trouble Code Triggered";
BA_ "SignalType" SG_ 1150 DTCI_RDCM_WrnIndTrggrd "ENM";
BA_ "SignalLongName" SG_ 1150 DTCI_RDCM_WrnIndTrggrd "Diagnostic Trouble Code Information Extended - RDCM : Warning Indicator Triggered";
BA_ "SignalType" SG_ 1150 DTCI_RDCM_WrnIndRqd "ENM";
BA_ "SignalLongName" SG_ 1150 DTCI_RDCM_WrnIndRqd "Diagnostic Trouble Code Information Extended - RDCM : Warning Indicator Requested";
BA_ "SignalLongName" SG_ 1326 DTCI_RSC_DTCFailType "Diagnostic Trouble Code Information Extended - RSC : Diagnostic Trouble Code Failure Type";
BA_ "SignalType" SG_ 1326 DTCI_RSC_CnfrmdDTC "ENM";
BA_ "SignalLongName" SG_ 1326 DTCI_RSC_CnfrmdDTC "Diagnostic Trouble Code Information Extended - RSC : Confirmed DTC";
BA_ "SignalType" SG_ 1326 DTCI_RSC_DTCFaultType "ENM";
BA_ "SignalLongName" SG_ 1326 DTCI_RSC_DTCFaultType "Diagnostic Trouble Code Information Extended - RSC : Diagnostic Trouble Code Fault Type";
BA_ "SignalLongName" SG_ 1326 DTCI_RSC_DTCNumber "Diagnostic Trouble Code Information Extended - RSC : Diagnostic Trouble Code Number";
BA_ "SignalLongName" SG_ 1326 DTCI_RSC_DTCSource "Diagnostic Trouble Code Information Extended - RSC : Diagnostic Trouble Code Source";
BA_ "SignalType" SG_ 1326 DTCI_RSC_TstNCmpltdOpCyc "ENM";
BA_ "SignalLongName" SG_ 1326 DTCI_RSC_TstNCmpltdOpCyc "Diagnostic Trouble Code Information Extended - RSC : Test Not Completed This Operation Cycle";
BA_ "SignalType" SG_ 1326 DTCI_RSC_TstNCmpltdLstClr "ENM";
BA_ "SignalLongName" SG_ 1326 DTCI_RSC_TstNCmpltdLstClr "Diagnostic Trouble Code Information Extended - RSC : Test Not Completed Since Last Clear";
BA_ "SignalType" SG_ 1326 DTCI_RSC_TstFldOpCyc "ENM";
BA_ "SignalLongName" SG_ 1326 DTCI_RSC_TstFldOpCyc "Diagnostic Trouble Code Information Extended - RSC : Test Failed This Operation Cycle";
BA_ "SignalType" SG_ 1326 DTCI_RSC_TstFldLstClr "ENM";
BA_ "SignalLongName" SG_ 1326 DTCI_RSC_TstFldLstClr "Diagnostic Trouble Code Information Extended - RSC : Test Failed Since Last Clear";
BA_ "SignalType" SG_ 1326 DTCI_RSC_TstFld "ENM";
BA_ "SignalLongName" SG_ 1326 DTCI_RSC_TstFld "Diagnostic Trouble Code Information Extended - RSC : Test Failed";
BA_ "SignalType" SG_ 1326 DTCI_RSC_PndngDTC "ENM";
BA_ "SignalLongName" SG_ 1326 DTCI_RSC_PndngDTC "Diagnostic Trouble Code Information Extended - RSC : Pending DTC";
BA_ "SignalType" SG_ 1326 DTCI_RSC_DTCTriggered "ENM";
BA_ "SignalLongName" SG_ 1326 DTCI_RSC_DTCTriggered "Diagnostic Trouble Code Information Extended - RSC : Diagnostic Trouble Code Triggered";
BA_ "SignalType" SG_ 1326 DTCI_RSC_WrnIndTrggrd "ENM";
BA_ "SignalLongName" SG_ 1326 DTCI_RSC_WrnIndTrggrd "Diagnostic Trouble Code Information Extended - RSC : Warning Indicator Triggered";
BA_ "SignalType" SG_ 1326 DTCI_RSC_WrnIndRqd "ENM";
BA_ "SignalLongName" SG_ 1326 DTCI_RSC_WrnIndRqd "Diagnostic Trouble Code Information Extended - RSC : Warning Indicator Requested";
BA_ "SignalLongName" SG_ 1330 DTCI_RadioLow_DTCFailType "Diagnostic Trouble Code Information Extended - RadioLow : Diagnostic Trouble Code Failure Type";
BA_ "SignalType" SG_ 1330 DTCI_RadioLow_CnfrmdDTC "ENM";
BA_ "SignalLongName" SG_ 1330 DTCI_RadioLow_CnfrmdDTC "Diagnostic Trouble Code Information Extended - RadioLow : Confirmed DTC";
BA_ "SignalType" SG_ 1330 DTCI_RadioLow_DTCFaultType "ENM";
BA_ "SignalLongName" SG_ 1330 DTCI_RadioLow_DTCFaultType "Diagnostic Trouble Code Information Extended - RadioLow : Diagnostic Trouble Code Fault Type";
BA_ "SignalLongName" SG_ 1330 DTCI_RadioLow_DTCNumber "Diagnostic Trouble Code Information Extended - RadioLow : Diagnostic Trouble Code Number";
BA_ "SignalLongName" SG_ 1330 DTCI_RadioLow_DTCSource "Diagnostic Trouble Code Information Extended - RadioLow : Diagnostic Trouble Code Source";
BA_ "SignalType" SG_ 1330 DTCI_RadioLow_TstNCmpltdOpCyc "ENM";
BA_ "SignalLongName" SG_ 1330 DTCI_RadioLow_TstNCmpltdOpCyc "Diagnostic Trouble Code Information Extended - RadioLow : Test Not Completed This Operation Cycle";
BA_ "SignalType" SG_ 1330 DTCI_RadioLow_TstNCmpltdLstClr "ENM";
BA_ "SignalLongName" SG_ 1330 DTCI_RadioLow_TstNCmpltdLstClr "Diagnostic Trouble Code Information Extended - RadioLow : Test Not Completed Since Last Clear";
BA_ "SignalType" SG_ 1330 DTCI_RadioLow_TstFldOpCyc "ENM";
BA_ "SignalLongName" SG_ 1330 DTCI_RadioLow_TstFldOpCyc "Diagnostic Trouble Code Information Extended - RadioLow : Test Failed This Operation Cycle";
BA_ "SignalType" SG_ 1330 DTCI_RadioLow_TstFldLstClr "ENM";
BA_ "SignalLongName" SG_ 1330 DTCI_RadioLow_TstFldLstClr "Diagnostic Trouble Code Information Extended - RadioLow : Test Failed Since Last Clear";
BA_ "SignalType" SG_ 1330 DTCI_RadioLow_TstFld "ENM";
BA_ "SignalLongName" SG_ 1330 DTCI_RadioLow_TstFld "Diagnostic Trouble Code Information Extended - RadioLow : Test Failed";
BA_ "SignalType" SG_ 1330 DTCI_RadioLow_PndngDTC "ENM";
BA_ "SignalLongName" SG_ 1330 DTCI_RadioLow_PndngDTC "Diagnostic Trouble Code Information Extended - RadioLow : Pending DTC";
BA_ "SignalType" SG_ 1330 DTCI_RadioLow_DTCTriggered "ENM";
BA_ "SignalLongName" SG_ 1330 DTCI_RadioLow_DTCTriggered "Diagnostic Trouble Code Information Extended - RadioLow : Diagnostic Trouble Code Triggered";
BA_ "SignalType" SG_ 1330 DTCI_RadioLow_WrnIndTrggrd "ENM";
BA_ "SignalLongName" SG_ 1330 DTCI_RadioLow_WrnIndTrggrd "Diagnostic Trouble Code Information Extended - RadioLow : Warning Indicator Triggered";
BA_ "SignalType" SG_ 1330 DTCI_RadioLow_WrnIndRqd "ENM";
BA_ "SignalLongName" SG_ 1330 DTCI_RadioLow_WrnIndRqd "Diagnostic Trouble Code Information Extended - RadioLow : Warning Indicator Requested";
BA_ "SignalLongName" SG_ 1151 DTCI_SADS_DTCFailType "Diagnostic Trouble Code Information Extended - SADS : Diagnostic Trouble Code Failure Type";
BA_ "SignalType" SG_ 1151 DTCI_SADS_CnfrmdDTC "ENM";
BA_ "SignalLongName" SG_ 1151 DTCI_SADS_CnfrmdDTC "Diagnostic Trouble Code Information Extended - SADS : Confirmed DTC";
BA_ "SignalType" SG_ 1151 DTCI_SADS_DTCFaultType "ENM";
BA_ "SignalLongName" SG_ 1151 DTCI_SADS_DTCFaultType "Diagnostic Trouble Code Information Extended - SADS : Diagnostic Trouble Code Fault Type";
BA_ "SignalLongName" SG_ 1151 DTCI_SADS_DTCNumber "Diagnostic Trouble Code Information Extended - SADS : Diagnostic Trouble Code Number";
BA_ "SignalLongName" SG_ 1151 DTCI_SADS_DTCSource "Diagnostic Trouble Code Information Extended - SADS : Diagnostic Trouble Code Source";
BA_ "SignalType" SG_ 1151 DTCI_SADS_TstNCmpltdOpCyc "ENM";
BA_ "SignalLongName" SG_ 1151 DTCI_SADS_TstNCmpltdOpCyc "Diagnostic Trouble Code Information Extended - SADS : Test Not Completed This Operation Cycle";
BA_ "SignalType" SG_ 1151 DTCI_SADS_TstNCmpltdLstClr "ENM";
BA_ "SignalLongName" SG_ 1151 DTCI_SADS_TstNCmpltdLstClr "Diagnostic Trouble Code Information Extended - SADS : Test Not Completed Since Last Clear";
BA_ "SignalType" SG_ 1151 DTCI_SADS_TstFldOpCyc "ENM";
BA_ "SignalLongName" SG_ 1151 DTCI_SADS_TstFldOpCyc "Diagnostic Trouble Code Information Extended - SADS : Test Failed This Operation Cycle";
BA_ "SignalType" SG_ 1151 DTCI_SADS_TstFldLstClr "ENM";
BA_ "SignalLongName" SG_ 1151 DTCI_SADS_TstFldLstClr "Diagnostic Trouble Code Information Extended - SADS : Test Failed Since Last Clear";
BA_ "SignalType" SG_ 1151 DTCI_SADS_TstFld "ENM";
BA_ "SignalLongName" SG_ 1151 DTCI_SADS_TstFld "Diagnostic Trouble Code Information Extended - SADS : Test Failed";
BA_ "SignalType" SG_ 1151 DTCI_SADS_PndngDTC "ENM";
BA_ "SignalLongName" SG_ 1151 DTCI_SADS_PndngDTC "Diagnostic Trouble Code Information Extended - SADS : Pending DTC";
BA_ "SignalType" SG_ 1151 DTCI_SADS_DTCTriggered "ENM";
BA_ "SignalLongName" SG_ 1151 DTCI_SADS_DTCTriggered "Diagnostic Trouble Code Information Extended - SADS : Diagnostic Trouble Code Triggered";
BA_ "SignalType" SG_ 1151 DTCI_SADS_WrnIndTrggrd "ENM";
BA_ "SignalLongName" SG_ 1151 DTCI_SADS_WrnIndTrggrd "Diagnostic Trouble Code Information Extended - SADS : Warning Indicator Triggered";
BA_ "SignalType" SG_ 1151 DTCI_SADS_WrnIndRqd "ENM";
BA_ "SignalLongName" SG_ 1151 DTCI_SADS_WrnIndRqd "Diagnostic Trouble Code Information Extended - SADS : Warning Indicator Requested";
BA_ "SignalLongName" SG_ 1416 DTCI_SBM_DTCFailType "Diagnostic Trouble Code Information Extended - SBM : Diagnostic Trouble Code Failure Type";
BA_ "SignalType" SG_ 1416 DTCI_SBM_CnfrmdDTC "ENM";
BA_ "SignalLongName" SG_ 1416 DTCI_SBM_CnfrmdDTC "Diagnostic Trouble Code Information Extended - SBM : Confirmed DTC";
BA_ "SignalType" SG_ 1416 DTCI_SBM_DTCFaultType "ENM";
BA_ "SignalLongName" SG_ 1416 DTCI_SBM_DTCFaultType "Diagnostic Trouble Code Information Extended - SBM : Diagnostic Trouble Code Fault Type";
BA_ "SignalLongName" SG_ 1416 DTCI_SBM_DTCNumber "Diagnostic Trouble Code Information Extended - SBM : Diagnostic Trouble Code Number";
BA_ "SignalLongName" SG_ 1416 DTCI_SBM_DTCSource "Diagnostic Trouble Code Information Extended - SBM : Diagnostic Trouble Code Source";
BA_ "SignalType" SG_ 1416 DTCI_SBM_TstNCmpltdOpCyc "ENM";
BA_ "SignalLongName" SG_ 1416 DTCI_SBM_TstNCmpltdOpCyc "Diagnostic Trouble Code Information Extended - SBM : Test Not Completed This Operation Cycle";
BA_ "SignalType" SG_ 1416 DTCI_SBM_TstNCmpltdLstClr "ENM";
BA_ "SignalLongName" SG_ 1416 DTCI_SBM_TstNCmpltdLstClr "Diagnostic Trouble Code Information Extended - SBM : Test Not Completed Since Last Clear";
BA_ "SignalType" SG_ 1416 DTCI_SBM_TstFldOpCyc "ENM";
BA_ "SignalLongName" SG_ 1416 DTCI_SBM_TstFldOpCyc "Diagnostic Trouble Code Information Extended - SBM : Test Failed This Operation Cycle";
BA_ "SignalType" SG_ 1416 DTCI_SBM_TstFldLstClr "ENM";
BA_ "SignalLongName" SG_ 1416 DTCI_SBM_TstFldLstClr "Diagnostic Trouble Code Information Extended - SBM : Test Failed Since Last Clear";
BA_ "SignalType" SG_ 1416 DTCI_SBM_TstFld "ENM";
BA_ "SignalLongName" SG_ 1416 DTCI_SBM_TstFld "Diagnostic Trouble Code Information Extended - SBM : Test Failed";
BA_ "SignalType" SG_ 1416 DTCI_SBM_PndngDTC "ENM";
BA_ "SignalLongName" SG_ 1416 DTCI_SBM_PndngDTC "Diagnostic Trouble Code Information Extended - SBM : Pending DTC";
BA_ "SignalType" SG_ 1416 DTCI_SBM_DTCTriggered "ENM";
BA_ "SignalLongName" SG_ 1416 DTCI_SBM_DTCTriggered "Diagnostic Trouble Code Information Extended - SBM : Diagnostic Trouble Code Triggered";
BA_ "SignalType" SG_ 1416 DTCI_SBM_WrnIndTrggrd "ENM";
BA_ "SignalLongName" SG_ 1416 DTCI_SBM_WrnIndTrggrd "Diagnostic Trouble Code Information Extended - SBM : Warning Indicator Triggered";
BA_ "SignalType" SG_ 1416 DTCI_SBM_WrnIndRqd "ENM";
BA_ "SignalLongName" SG_ 1416 DTCI_SBM_WrnIndRqd "Diagnostic Trouble Code Information Extended - SBM : Warning Indicator Requested";
BA_ "SignalLongName" SG_ 1348 DTCI_SBZA_L_DTCFailType "Diagnostic Trouble Code Information Extended - SBZA_L : Diagnostic Trouble Code Failure Type";
BA_ "SignalType" SG_ 1348 DTCI_SBZA_L_CnfrmdDTC "ENM";
BA_ "SignalLongName" SG_ 1348 DTCI_SBZA_L_CnfrmdDTC "Diagnostic Trouble Code Information Extended - SBZA_L : Confirmed DTC";
BA_ "SignalType" SG_ 1348 DTCI_SBZA_L_DTCFaultType "ENM";
BA_ "SignalLongName" SG_ 1348 DTCI_SBZA_L_DTCFaultType "Diagnostic Trouble Code Information Extended - SBZA_L : Diagnostic Trouble Code Fault Type";
BA_ "SignalLongName" SG_ 1348 DTCI_SBZA_L_DTCNumber "Diagnostic Trouble Code Information Extended - SBZA_L : Diagnostic Trouble Code Number";
BA_ "SignalLongName" SG_ 1348 DTCI_SBZA_L_DTCSource "Diagnostic Trouble Code Information Extended - SBZA_L : Diagnostic Trouble Code Source";
BA_ "SignalType" SG_ 1348 DTCI_SBZA_L_TstNCmpltdOpCyc "ENM";
BA_ "SignalLongName" SG_ 1348 DTCI_SBZA_L_TstNCmpltdOpCyc "Diagnostic Trouble Code Information Extended - SBZA_L : Test Not Completed This Operation Cycle";
BA_ "SignalType" SG_ 1348 DTCI_SBZA_L_TstNCmpltdLstClr "ENM";
BA_ "SignalLongName" SG_ 1348 DTCI_SBZA_L_TstNCmpltdLstClr "Diagnostic Trouble Code Information Extended - SBZA_L : Test Not Completed Since Last Clear";
BA_ "SignalType" SG_ 1348 DTCI_SBZA_L_TstFldOpCyc "ENM";
BA_ "SignalLongName" SG_ 1348 DTCI_SBZA_L_TstFldOpCyc "Diagnostic Trouble Code Information Extended - SBZA_L : Test Failed This Operation Cycle";
BA_ "SignalType" SG_ 1348 DTCI_SBZA_L_TstFldLstClr "ENM";
BA_ "SignalLongName" SG_ 1348 DTCI_SBZA_L_TstFldLstClr "Diagnostic Trouble Code Information Extended - SBZA_L : Test Failed Since Last Clear";
BA_ "SignalType" SG_ 1348 DTCI_SBZA_L_TstFld "ENM";
BA_ "SignalLongName" SG_ 1348 DTCI_SBZA_L_TstFld "Diagnostic Trouble Code Information Extended - SBZA_L : Test Failed";
BA_ "SignalType" SG_ 1348 DTCI_SBZA_L_PndngDTC "ENM";
BA_ "SignalLongName" SG_ 1348 DTCI_SBZA_L_PndngDTC "Diagnostic Trouble Code Information Extended - SBZA_L : Pending DTC";
BA_ "SignalType" SG_ 1348 DTCI_SBZA_L_DTCTriggered "ENM";
BA_ "SignalLongName" SG_ 1348 DTCI_SBZA_L_DTCTriggered "Diagnostic Trouble Code Information Extended - SBZA_L : Diagnostic Trouble Code Triggered";
BA_ "SignalType" SG_ 1348 DTCI_SBZA_L_WrnIndTrggrd "ENM";
BA_ "SignalLongName" SG_ 1348 DTCI_SBZA_L_WrnIndTrggrd "Diagnostic Trouble Code Information Extended - SBZA_L : Warning Indicator Triggered";
BA_ "SignalType" SG_ 1348 DTCI_SBZA_L_WrnIndRqd "ENM";
BA_ "SignalLongName" SG_ 1348 DTCI_SBZA_L_WrnIndRqd "Diagnostic Trouble Code Information Extended - SBZA_L : Warning Indicator Requested";
BA_ "SignalLongName" SG_ 1153 DTCI_SBZA_R_DTCFailType "Diagnostic Trouble Code Information Extended - SBZA_R : Diagnostic Trouble Code Failure Type";
BA_ "SignalType" SG_ 1153 DTCI_SBZA_R_CnfrmdDTC "ENM";
BA_ "SignalLongName" SG_ 1153 DTCI_SBZA_R_CnfrmdDTC "Diagnostic Trouble Code Information Extended - SBZA_R : Confirmed DTC";
BA_ "SignalType" SG_ 1153 DTCI_SBZA_R_DTCFaultType "ENM";
BA_ "SignalLongName" SG_ 1153 DTCI_SBZA_R_DTCFaultType "Diagnostic Trouble Code Information Extended - SBZA_R : Diagnostic Trouble Code Fault Type";
BA_ "SignalLongName" SG_ 1153 DTCI_SBZA_R_DTCNumber "Diagnostic Trouble Code Information Extended - SBZA_R : Diagnostic Trouble Code Number";
BA_ "SignalLongName" SG_ 1153 DTCI_SBZA_R_DTCSource "Diagnostic Trouble Code Information Extended - SBZA_R : Diagnostic Trouble Code Source";
BA_ "SignalType" SG_ 1153 DTCI_SBZA_R_TstNCmpltdOpCyc "ENM";
BA_ "SignalLongName" SG_ 1153 DTCI_SBZA_R_TstNCmpltdOpCyc "Diagnostic Trouble Code Information Extended - SBZA_R : Test Not Completed This Operation Cycle";
BA_ "SignalType" SG_ 1153 DTCI_SBZA_R_TstNCmpltdLstClr "ENM";
BA_ "SignalLongName" SG_ 1153 DTCI_SBZA_R_TstNCmpltdLstClr "Diagnostic Trouble Code Information Extended - SBZA_R : Test Not Completed Since Last Clear";
BA_ "SignalType" SG_ 1153 DTCI_SBZA_R_TstFldOpCyc "ENM";
BA_ "SignalLongName" SG_ 1153 DTCI_SBZA_R_TstFldOpCyc "Diagnostic Trouble Code Information Extended - SBZA_R : Test Failed This Operation Cycle";
BA_ "SignalType" SG_ 1153 DTCI_SBZA_R_TstFldLstClr "ENM";
BA_ "SignalLongName" SG_ 1153 DTCI_SBZA_R_TstFldLstClr "Diagnostic Trouble Code Information Extended - SBZA_R : Test Failed Since Last Clear";
BA_ "SignalType" SG_ 1153 DTCI_SBZA_R_TstFld "ENM";
BA_ "SignalLongName" SG_ 1153 DTCI_SBZA_R_TstFld "Diagnostic Trouble Code Information Extended - SBZA_R : Test Failed";
BA_ "SignalType" SG_ 1153 DTCI_SBZA_R_PndngDTC "ENM";
BA_ "SignalLongName" SG_ 1153 DTCI_SBZA_R_PndngDTC "Diagnostic Trouble Code Information Extended - SBZA_R : Pending DTC";
BA_ "SignalType" SG_ 1153 DTCI_SBZA_R_DTCTriggered "ENM";
BA_ "SignalLongName" SG_ 1153 DTCI_SBZA_R_DTCTriggered "Diagnostic Trouble Code Information Extended - SBZA_R : Diagnostic Trouble Code Triggered";
BA_ "SignalType" SG_ 1153 DTCI_SBZA_R_WrnIndTrggrd "ENM";
BA_ "SignalLongName" SG_ 1153 DTCI_SBZA_R_WrnIndTrggrd "Diagnostic Trouble Code Information Extended - SBZA_R : Warning Indicator Triggered";
BA_ "SignalType" SG_ 1153 DTCI_SBZA_R_WrnIndRqd "ENM";
BA_ "SignalLongName" SG_ 1153 DTCI_SBZA_R_WrnIndRqd "Diagnostic Trouble Code Information Extended - SBZA_R : Warning Indicator Requested";
BA_ "SignalLongName" SG_ 1154 DTCI_SCL_DTCFailType "Diagnostic Trouble Code Information Extended - SCL : Diagnostic Trouble Code Failure Type";
BA_ "SignalType" SG_ 1154 DTCI_SCL_CnfrmdDTC "ENM";
BA_ "SignalLongName" SG_ 1154 DTCI_SCL_CnfrmdDTC "Diagnostic Trouble Code Information Extended - SCL : Confirmed DTC";
BA_ "SignalType" SG_ 1154 DTCI_SCL_DTCFaultType "ENM";
BA_ "SignalLongName" SG_ 1154 DTCI_SCL_DTCFaultType "Diagnostic Trouble Code Information Extended - SCL : Diagnostic Trouble Code Fault Type";
BA_ "SignalLongName" SG_ 1154 DTCI_SCL_DTCNumber "Diagnostic Trouble Code Information Extended - SCL : Diagnostic Trouble Code Number";
BA_ "SignalLongName" SG_ 1154 DTCI_SCL_DTCSource "Diagnostic Trouble Code Information Extended - SCL : Diagnostic Trouble Code Source";
BA_ "SignalType" SG_ 1154 DTCI_SCL_TstNCmpltdOpCyc "ENM";
BA_ "SignalLongName" SG_ 1154 DTCI_SCL_TstNCmpltdOpCyc "Diagnostic Trouble Code Information Extended - SCL : Test Not Completed This Operation Cycle";
BA_ "SignalType" SG_ 1154 DTCI_SCL_TstNCmpltdLstClr "ENM";
BA_ "SignalLongName" SG_ 1154 DTCI_SCL_TstNCmpltdLstClr "Diagnostic Trouble Code Information Extended - SCL : Test Not Completed Since Last Clear";
BA_ "SignalType" SG_ 1154 DTCI_SCL_TstFldOpCyc "ENM";
BA_ "SignalLongName" SG_ 1154 DTCI_SCL_TstFldOpCyc "Diagnostic Trouble Code Information Extended - SCL : Test Failed This Operation Cycle";
BA_ "SignalType" SG_ 1154 DTCI_SCL_TstFldLstClr "ENM";
BA_ "SignalLongName" SG_ 1154 DTCI_SCL_TstFldLstClr "Diagnostic Trouble Code Information Extended - SCL : Test Failed Since Last Clear";
BA_ "SignalType" SG_ 1154 DTCI_SCL_TstFld "ENM";
BA_ "SignalLongName" SG_ 1154 DTCI_SCL_TstFld "Diagnostic Trouble Code Information Extended - SCL : Test Failed";
BA_ "SignalType" SG_ 1154 DTCI_SCL_PndngDTC "ENM";
BA_ "SignalLongName" SG_ 1154 DTCI_SCL_PndngDTC "Diagnostic Trouble Code Information Extended - SCL : Pending DTC";
BA_ "SignalType" SG_ 1154 DTCI_SCL_DTCTriggered "ENM";
BA_ "SignalLongName" SG_ 1154 DTCI_SCL_DTCTriggered "Diagnostic Trouble Code Information Extended - SCL : Diagnostic Trouble Code Triggered";
BA_ "SignalType" SG_ 1154 DTCI_SCL_WrnIndTrggrd "ENM";
BA_ "SignalLongName" SG_ 1154 DTCI_SCL_WrnIndTrggrd "Diagnostic Trouble Code Information Extended - SCL : Warning Indicator Triggered";
BA_ "SignalType" SG_ 1154 DTCI_SCL_WrnIndRqd "ENM";
BA_ "SignalLongName" SG_ 1154 DTCI_SCL_WrnIndRqd "Diagnostic Trouble Code Information Extended - SCL : Warning Indicator Requested";
BA_ "SignalLongName" SG_ 1155 DTCI_SDM_DTCFailType "Diagnostic Trouble Code Information Extended - SDM : Diagnostic Trouble Code Failure Type";
BA_ "SignalType" SG_ 1155 DTCI_SDM_CnfrmdDTC "ENM";
BA_ "SignalLongName" SG_ 1155 DTCI_SDM_CnfrmdDTC "Diagnostic Trouble Code Information Extended - SDM : Confirmed DTC";
BA_ "SignalType" SG_ 1155 DTCI_SDM_DTCFaultType "ENM";
BA_ "SignalLongName" SG_ 1155 DTCI_SDM_DTCFaultType "Diagnostic Trouble Code Information Extended - SDM : Diagnostic Trouble Code Fault Type";
BA_ "SignalLongName" SG_ 1155 DTCI_SDM_DTCNumber "Diagnostic Trouble Code Information Extended - SDM : Diagnostic Trouble Code Number";
BA_ "SignalLongName" SG_ 1155 DTCI_SDM_DTCSource "Diagnostic Trouble Code Information Extended - SDM : Diagnostic Trouble Code Source";
BA_ "SignalType" SG_ 1155 DTCI_SDM_TstNCmpltdOpCyc "ENM";
BA_ "SignalLongName" SG_ 1155 DTCI_SDM_TstNCmpltdOpCyc "Diagnostic Trouble Code Information Extended - SDM : Test Not Completed This Operation Cycle";
BA_ "SignalType" SG_ 1155 DTCI_SDM_TstNCmpltdLstClr "ENM";
BA_ "SignalLongName" SG_ 1155 DTCI_SDM_TstNCmpltdLstClr "Diagnostic Trouble Code Information Extended - SDM : Test Not Completed Since Last Clear";
BA_ "SignalType" SG_ 1155 DTCI_SDM_TstFldOpCyc "ENM";
BA_ "SignalLongName" SG_ 1155 DTCI_SDM_TstFldOpCyc "Diagnostic Trouble Code Information Extended - SDM : Test Failed This Operation Cycle";
BA_ "SignalType" SG_ 1155 DTCI_SDM_TstFldLstClr "ENM";
BA_ "SignalLongName" SG_ 1155 DTCI_SDM_TstFldLstClr "Diagnostic Trouble Code Information Extended - SDM : Test Failed Since Last Clear";
BA_ "SignalType" SG_ 1155 DTCI_SDM_TstFld "ENM";
BA_ "SignalLongName" SG_ 1155 DTCI_SDM_TstFld "Diagnostic Trouble Code Information Extended - SDM : Test Failed";
BA_ "SignalType" SG_ 1155 DTCI_SDM_PndngDTC "ENM";
BA_ "SignalLongName" SG_ 1155 DTCI_SDM_PndngDTC "Diagnostic Trouble Code Information Extended - SDM : Pending DTC";
BA_ "SignalType" SG_ 1155 DTCI_SDM_DTCTriggered "ENM";
BA_ "SignalLongName" SG_ 1155 DTCI_SDM_DTCTriggered "Diagnostic Trouble Code Information Extended - SDM : Diagnostic Trouble Code Triggered";
BA_ "SignalType" SG_ 1155 DTCI_SDM_WrnIndTrggrd "ENM";
BA_ "SignalLongName" SG_ 1155 DTCI_SDM_WrnIndTrggrd "Diagnostic Trouble Code Information Extended - SDM : Warning Indicator Triggered";
BA_ "SignalType" SG_ 1155 DTCI_SDM_WrnIndRqd "ENM";
BA_ "SignalLongName" SG_ 1155 DTCI_SDM_WrnIndRqd "Diagnostic Trouble Code Information Extended - SDM : Warning Indicator Requested";
BA_ "SignalLongName" SG_ 1156 DTCI_SIB_DTCFailType "Diagnostic Trouble Code Information Extended - SIB : Diagnostic Trouble Code Failure Type";
BA_ "SignalType" SG_ 1156 DTCI_SIB_CnfrmdDTC "ENM";
BA_ "SignalLongName" SG_ 1156 DTCI_SIB_CnfrmdDTC "Diagnostic Trouble Code Information Extended - SIB : Confirmed DTC";
BA_ "SignalType" SG_ 1156 DTCI_SIB_DTCFaultType "ENM";
BA_ "SignalLongName" SG_ 1156 DTCI_SIB_DTCFaultType "Diagnostic Trouble Code Information Extended - SIB : Diagnostic Trouble Code Fault Type";
BA_ "SignalLongName" SG_ 1156 DTCI_SIB_DTCNumber "Diagnostic Trouble Code Information Extended - SIB : Diagnostic Trouble Code Number";
BA_ "SignalLongName" SG_ 1156 DTCI_SIB_DTCSource "Diagnostic Trouble Code Information Extended - SIB : Diagnostic Trouble Code Source";
BA_ "SignalType" SG_ 1156 DTCI_SIB_TstNCmpltdOpCyc "ENM";
BA_ "SignalLongName" SG_ 1156 DTCI_SIB_TstNCmpltdOpCyc "Diagnostic Trouble Code Information Extended - SIB : Test Not Completed This Operation Cycle";
BA_ "SignalType" SG_ 1156 DTCI_SIB_TstNCmpltdLstClr "ENM";
BA_ "SignalLongName" SG_ 1156 DTCI_SIB_TstNCmpltdLstClr "Diagnostic Trouble Code Information Extended - SIB : Test Not Completed Since Last Clear";
BA_ "SignalType" SG_ 1156 DTCI_SIB_TstFldOpCyc "ENM";
BA_ "SignalLongName" SG_ 1156 DTCI_SIB_TstFldOpCyc "Diagnostic Trouble Code Information Extended - SIB : Test Failed This Operation Cycle";
BA_ "SignalType" SG_ 1156 DTCI_SIB_TstFldLstClr "ENM";
BA_ "SignalLongName" SG_ 1156 DTCI_SIB_TstFldLstClr "Diagnostic Trouble Code Information Extended - SIB : Test Failed Since Last Clear";
BA_ "SignalType" SG_ 1156 DTCI_SIB_TstFld "ENM";
BA_ "SignalLongName" SG_ 1156 DTCI_SIB_TstFld "Diagnostic Trouble Code Information Extended - SIB : Test Failed";
BA_ "SignalType" SG_ 1156 DTCI_SIB_PndngDTC "ENM";
BA_ "SignalLongName" SG_ 1156 DTCI_SIB_PndngDTC "Diagnostic Trouble Code Information Extended - SIB : Pending DTC";
BA_ "SignalType" SG_ 1156 DTCI_SIB_DTCTriggered "ENM";
BA_ "SignalLongName" SG_ 1156 DTCI_SIB_DTCTriggered "Diagnostic Trouble Code Information Extended - SIB : Diagnostic Trouble Code Triggered";
BA_ "SignalType" SG_ 1156 DTCI_SIB_WrnIndTrggrd "ENM";
BA_ "SignalLongName" SG_ 1156 DTCI_SIB_WrnIndTrggrd "Diagnostic Trouble Code Information Extended - SIB : Warning Indicator Triggered";
BA_ "SignalType" SG_ 1156 DTCI_SIB_WrnIndRqd "ENM";
BA_ "SignalLongName" SG_ 1156 DTCI_SIB_WrnIndRqd "Diagnostic Trouble Code Information Extended - SIB : Warning Indicator Requested";
BA_ "SignalLongName" SG_ 1157 DTCI_SRR_LF_DTCFailType "Diagnostic Trouble Code Information Extended - SRR_LF : Diagnostic Trouble Code Failure Type";
BA_ "SignalType" SG_ 1157 DTCI_SRR_LF_CnfrmdDTC "ENM";
BA_ "SignalLongName" SG_ 1157 DTCI_SRR_LF_CnfrmdDTC "Diagnostic Trouble Code Information Extended - SRR_LF : Confirmed DTC";
BA_ "SignalType" SG_ 1157 DTCI_SRR_LF_DTCFaultType "ENM";
BA_ "SignalLongName" SG_ 1157 DTCI_SRR_LF_DTCFaultType "Diagnostic Trouble Code Information Extended - SRR_LF : Diagnostic Trouble Code Fault Type";
BA_ "SignalLongName" SG_ 1157 DTCI_SRR_LF_DTCNumber "Diagnostic Trouble Code Information Extended - SRR_LF : Diagnostic Trouble Code Number";
BA_ "SignalLongName" SG_ 1157 DTCI_SRR_LF_DTCSource "Diagnostic Trouble Code Information Extended - SRR_LF : Diagnostic Trouble Code Source";
BA_ "SignalType" SG_ 1157 DTCI_SRR_LF_TstNCmpltdOpCyc "ENM";
BA_ "SignalLongName" SG_ 1157 DTCI_SRR_LF_TstNCmpltdOpCyc "Diagnostic Trouble Code Information Extended - SRR_LF : Test Not Completed This Operation Cycle";
BA_ "SignalType" SG_ 1157 DTCI_SRR_LF_TstNCmpltdLstClr "ENM";
BA_ "SignalLongName" SG_ 1157 DTCI_SRR_LF_TstNCmpltdLstClr "Diagnostic Trouble Code Information Extended - SRR_LF : Test Not Completed Since Last Clear";
BA_ "SignalType" SG_ 1157 DTCI_SRR_LF_TstFldOpCyc "ENM";
BA_ "SignalLongName" SG_ 1157 DTCI_SRR_LF_TstFldOpCyc "Diagnostic Trouble Code Information Extended - SRR_LF : Test Failed This Operation Cycle";
BA_ "SignalType" SG_ 1157 DTCI_SRR_LF_TstFldLstClr "ENM";
BA_ "SignalLongName" SG_ 1157 DTCI_SRR_LF_TstFldLstClr "Diagnostic Trouble Code Information Extended - SRR_LF : Test Failed Since Last Clear";
BA_ "SignalType" SG_ 1157 DTCI_SRR_LF_TstFld "ENM";
BA_ "SignalLongName" SG_ 1157 DTCI_SRR_LF_TstFld "Diagnostic Trouble Code Information Extended - SRR_LF : Test Failed";
BA_ "SignalType" SG_ 1157 DTCI_SRR_LF_PndngDTC "ENM";
BA_ "SignalLongName" SG_ 1157 DTCI_SRR_LF_PndngDTC "Diagnostic Trouble Code Information Extended - SRR_LF : Pending DTC";
BA_ "SignalType" SG_ 1157 DTCI_SRR_LF_DTCTriggered "ENM";
BA_ "SignalLongName" SG_ 1157 DTCI_SRR_LF_DTCTriggered "Diagnostic Trouble Code Information Extended - SRR_LF : Diagnostic Trouble Code Triggered";
BA_ "SignalType" SG_ 1157 DTCI_SRR_LF_WrnIndTrggrd "ENM";
BA_ "SignalLongName" SG_ 1157 DTCI_SRR_LF_WrnIndTrggrd "Diagnostic Trouble Code Information Extended - SRR_LF : Warning Indicator Triggered";
BA_ "SignalType" SG_ 1157 DTCI_SRR_LF_WrnIndRqd "ENM";
BA_ "SignalLongName" SG_ 1157 DTCI_SRR_LF_WrnIndRqd "Diagnostic Trouble Code Information Extended - SRR_LF : Warning Indicator Requested";
BA_ "SignalLongName" SG_ 1158 DTCI_SRR_LR_CR_DTCFailType "Diagnostic Trouble Code Information Extended - SRR_LR_CR : Diagnostic Trouble Code Failure Type";
BA_ "SignalType" SG_ 1158 DTCI_SRR_LR_CR_CnfrmdDTC "ENM";
BA_ "SignalLongName" SG_ 1158 DTCI_SRR_LR_CR_CnfrmdDTC "Diagnostic Trouble Code Information Extended - SRR_LR_CR : Confirmed DTC";
BA_ "SignalType" SG_ 1158 DTCI_SRR_LR_CR_DTCFaultType "ENM";
BA_ "SignalLongName" SG_ 1158 DTCI_SRR_LR_CR_DTCFaultType "Diagnostic Trouble Code Information Extended - SRR_LR_CR : Diagnostic Trouble Code Fault Type";
BA_ "SignalLongName" SG_ 1158 DTCI_SRR_LR_CR_DTCNumber "Diagnostic Trouble Code Information Extended - SRR_LR_CR : Diagnostic Trouble Code Number";
BA_ "SignalLongName" SG_ 1158 DTCI_SRR_LR_CR_DTCSource "Diagnostic Trouble Code Information Extended - SRR_LR_CR : Diagnostic Trouble Code Source";
BA_ "SignalType" SG_ 1158 DTCI_SRR_LR_CR_TstNCmpltdOpCyc "ENM";
BA_ "SignalLongName" SG_ 1158 DTCI_SRR_LR_CR_TstNCmpltdOpCyc "Diagnostic Trouble Code Information Extended - SRR_LR_CR : Test Not Completed This Operation Cycle";
BA_ "SignalType" SG_ 1158 DTCI_SRR_LR_CR_TstNCmpltdLstClr "ENM";
BA_ "SignalLongName" SG_ 1158 DTCI_SRR_LR_CR_TstNCmpltdLstClr "Diagnostic Trouble Code Information Extended - SRR_LR_CR : Test Not Completed Since Last Clear";
BA_ "SignalType" SG_ 1158 DTCI_SRR_LR_CR_TstFldOpCyc "ENM";
BA_ "SignalLongName" SG_ 1158 DTCI_SRR_LR_CR_TstFldOpCyc "Diagnostic Trouble Code Information Extended - SRR_LR_CR : Test Failed This Operation Cycle";
BA_ "SignalType" SG_ 1158 DTCI_SRR_LR_CR_TstFldLstClr "ENM";
BA_ "SignalLongName" SG_ 1158 DTCI_SRR_LR_CR_TstFldLstClr "Diagnostic Trouble Code Information Extended - SRR_LR_CR : Test Failed Since Last Clear";
BA_ "SignalType" SG_ 1158 DTCI_SRR_LR_CR_TstFld "ENM";
BA_ "SignalLongName" SG_ 1158 DTCI_SRR_LR_CR_TstFld "Diagnostic Trouble Code Information Extended - SRR_LR_CR : Test Failed";
BA_ "SignalType" SG_ 1158 DTCI_SRR_LR_CR_PndngDTC "ENM";
BA_ "SignalLongName" SG_ 1158 DTCI_SRR_LR_CR_PndngDTC "Diagnostic Trouble Code Information Extended - SRR_LR_CR : Pending DTC";
BA_ "SignalType" SG_ 1158 DTCI_SRR_LR_CR_DTCTriggered "ENM";
BA_ "SignalLongName" SG_ 1158 DTCI_SRR_LR_CR_DTCTriggered "Diagnostic Trouble Code Information Extended - SRR_LR_CR : Diagnostic Trouble Code Triggered";
BA_ "SignalType" SG_ 1158 DTCI_SRR_LR_CR_WrnIndTrggrd "ENM";
BA_ "SignalLongName" SG_ 1158 DTCI_SRR_LR_CR_WrnIndTrggrd "Diagnostic Trouble Code Information Extended - SRR_LR_CR : Warning Indicator Triggered";
BA_ "SignalType" SG_ 1158 DTCI_SRR_LR_CR_WrnIndRqd "ENM";
BA_ "SignalLongName" SG_ 1158 DTCI_SRR_LR_CR_WrnIndRqd "Diagnostic Trouble Code Information Extended - SRR_LR_CR : Warning Indicator Requested";
BA_ "SignalLongName" SG_ 1159 DTCI_SRR_RF_DTCFailType "Diagnostic Trouble Code Information Extended - SRR_RF : Diagnostic Trouble Code Failure Type";
BA_ "SignalType" SG_ 1159 DTCI_SRR_RF_CnfrmdDTC "ENM";
BA_ "SignalLongName" SG_ 1159 DTCI_SRR_RF_CnfrmdDTC "Diagnostic Trouble Code Information Extended - SRR_RF : Confirmed DTC";
BA_ "SignalType" SG_ 1159 DTCI_SRR_RF_DTCFaultType "ENM";
BA_ "SignalLongName" SG_ 1159 DTCI_SRR_RF_DTCFaultType "Diagnostic Trouble Code Information Extended - SRR_RF : Diagnostic Trouble Code Fault Type";
BA_ "SignalLongName" SG_ 1159 DTCI_SRR_RF_DTCNumber "Diagnostic Trouble Code Information Extended - SRR_RF : Diagnostic Trouble Code Number";
BA_ "SignalLongName" SG_ 1159 DTCI_SRR_RF_DTCSource "Diagnostic Trouble Code Information Extended - SRR_RF : Diagnostic Trouble Code Source";
BA_ "SignalType" SG_ 1159 DTCI_SRR_RF_TstNCmpltdOpCyc "ENM";
BA_ "SignalLongName" SG_ 1159 DTCI_SRR_RF_TstNCmpltdOpCyc "Diagnostic Trouble Code Information Extended - SRR_RF : Test Not Completed This Operation Cycle";
BA_ "SignalType" SG_ 1159 DTCI_SRR_RF_TstNCmpltdLstClr "ENM";
BA_ "SignalLongName" SG_ 1159 DTCI_SRR_RF_TstNCmpltdLstClr "Diagnostic Trouble Code Information Extended - SRR_RF : Test Not Completed Since Last Clear";
BA_ "SignalType" SG_ 1159 DTCI_SRR_RF_TstFldOpCyc "ENM";
BA_ "SignalLongName" SG_ 1159 DTCI_SRR_RF_TstFldOpCyc "Diagnostic Trouble Code Information Extended - SRR_RF : Test Failed This Operation Cycle";
BA_ "SignalType" SG_ 1159 DTCI_SRR_RF_TstFldLstClr "ENM";
BA_ "SignalLongName" SG_ 1159 DTCI_SRR_RF_TstFldLstClr "Diagnostic Trouble Code Information Extended - SRR_RF : Test Failed Since Last Clear";
BA_ "SignalType" SG_ 1159 DTCI_SRR_RF_TstFld "ENM";
BA_ "SignalLongName" SG_ 1159 DTCI_SRR_RF_TstFld "Diagnostic Trouble Code Information Extended - SRR_RF : Test Failed";
BA_ "SignalType" SG_ 1159 DTCI_SRR_RF_PndngDTC "ENM";
BA_ "SignalLongName" SG_ 1159 DTCI_SRR_RF_PndngDTC "Diagnostic Trouble Code Information Extended - SRR_RF : Pending DTC";
BA_ "SignalType" SG_ 1159 DTCI_SRR_RF_DTCTriggered "ENM";
BA_ "SignalLongName" SG_ 1159 DTCI_SRR_RF_DTCTriggered "Diagnostic Trouble Code Information Extended - SRR_RF : Diagnostic Trouble Code Triggered";
BA_ "SignalType" SG_ 1159 DTCI_SRR_RF_WrnIndTrggrd "ENM";
BA_ "SignalLongName" SG_ 1159 DTCI_SRR_RF_WrnIndTrggrd "Diagnostic Trouble Code Information Extended - SRR_RF : Warning Indicator Triggered";
BA_ "SignalType" SG_ 1159 DTCI_SRR_RF_WrnIndRqd "ENM";
BA_ "SignalLongName" SG_ 1159 DTCI_SRR_RF_WrnIndRqd "Diagnostic Trouble Code Information Extended - SRR_RF : Warning Indicator Requested";
BA_ "SignalLongName" SG_ 1160 DTCI_SRR_RR_DTCFailType "Diagnostic Trouble Code Information Extended - SRR_RR : Diagnostic Trouble Code Failure Type";
BA_ "SignalType" SG_ 1160 DTCI_SRR_RR_CnfrmdDTC "ENM";
BA_ "SignalLongName" SG_ 1160 DTCI_SRR_RR_CnfrmdDTC "Diagnostic Trouble Code Information Extended - SRR_RR : Confirmed DTC";
BA_ "SignalType" SG_ 1160 DTCI_SRR_RR_DTCFaultType "ENM";
BA_ "SignalLongName" SG_ 1160 DTCI_SRR_RR_DTCFaultType "Diagnostic Trouble Code Information Extended - SRR_RR : Diagnostic Trouble Code Fault Type";
BA_ "SignalLongName" SG_ 1160 DTCI_SRR_RR_DTCNumber "Diagnostic Trouble Code Information Extended - SRR_RR : Diagnostic Trouble Code Number";
BA_ "SignalLongName" SG_ 1160 DTCI_SRR_RR_DTCSource "Diagnostic Trouble Code Information Extended - SRR_RR : Diagnostic Trouble Code Source";
BA_ "SignalType" SG_ 1160 DTCI_SRR_RR_TstNCmpltdOpCyc "ENM";
BA_ "SignalLongName" SG_ 1160 DTCI_SRR_RR_TstNCmpltdOpCyc "Diagnostic Trouble Code Information Extended - SRR_RR : Test Not Completed This Operation Cycle";
BA_ "SignalType" SG_ 1160 DTCI_SRR_RR_TstNCmpltdLstClr "ENM";
BA_ "SignalLongName" SG_ 1160 DTCI_SRR_RR_TstNCmpltdLstClr "Diagnostic Trouble Code Information Extended - SRR_RR : Test Not Completed Since Last Clear";
BA_ "SignalType" SG_ 1160 DTCI_SRR_RR_TstFldOpCyc "ENM";
BA_ "SignalLongName" SG_ 1160 DTCI_SRR_RR_TstFldOpCyc "Diagnostic Trouble Code Information Extended - SRR_RR : Test Failed This Operation Cycle";
BA_ "SignalType" SG_ 1160 DTCI_SRR_RR_TstFldLstClr "ENM";
BA_ "SignalLongName" SG_ 1160 DTCI_SRR_RR_TstFldLstClr "Diagnostic Trouble Code Information Extended - SRR_RR : Test Failed Since Last Clear";
BA_ "SignalType" SG_ 1160 DTCI_SRR_RR_TstFld "ENM";
BA_ "SignalLongName" SG_ 1160 DTCI_SRR_RR_TstFld "Diagnostic Trouble Code Information Extended - SRR_RR : Test Failed";
BA_ "SignalType" SG_ 1160 DTCI_SRR_RR_PndngDTC "ENM";
BA_ "SignalLongName" SG_ 1160 DTCI_SRR_RR_PndngDTC "Diagnostic Trouble Code Information Extended - SRR_RR : Pending DTC";
BA_ "SignalType" SG_ 1160 DTCI_SRR_RR_DTCTriggered "ENM";
BA_ "SignalLongName" SG_ 1160 DTCI_SRR_RR_DTCTriggered "Diagnostic Trouble Code Information Extended - SRR_RR : Diagnostic Trouble Code Triggered";
BA_ "SignalType" SG_ 1160 DTCI_SRR_RR_WrnIndTrggrd "ENM";
BA_ "SignalLongName" SG_ 1160 DTCI_SRR_RR_WrnIndTrggrd "Diagnostic Trouble Code Information Extended - SRR_RR : Warning Indicator Triggered";
BA_ "SignalType" SG_ 1160 DTCI_SRR_RR_WrnIndRqd "ENM";
BA_ "SignalLongName" SG_ 1160 DTCI_SRR_RR_WrnIndRqd "Diagnostic Trouble Code Information Extended - SRR_RR : Warning Indicator Requested";
BA_ "SignalLongName" SG_ 1407 DTCI_SRR_SLR_DTCFailType "Diagnostic Trouble Code Information Extended - SRR_SLR : Diagnostic Trouble Code Failure Type";
BA_ "SignalType" SG_ 1407 DTCI_SRR_SLR_CnfrmdDTC "ENM";
BA_ "SignalLongName" SG_ 1407 DTCI_SRR_SLR_CnfrmdDTC "Diagnostic Trouble Code Information Extended - SRR_SLR : Confirmed DTC";
BA_ "SignalType" SG_ 1407 DTCI_SRR_SLR_DTCFaultType "ENM";
BA_ "SignalLongName" SG_ 1407 DTCI_SRR_SLR_DTCFaultType "Diagnostic Trouble Code Information Extended - SRR_SLR : Diagnostic Trouble Code Fault Type";
BA_ "SignalLongName" SG_ 1407 DTCI_SRR_SLR_DTCNumber "Diagnostic Trouble Code Information Extended - SRR_SLR : Diagnostic Trouble Code Number";
BA_ "SignalLongName" SG_ 1407 DTCI_SRR_SLR_DTCSource "Diagnostic Trouble Code Information Extended - SRR_SLR : Diagnostic Trouble Code Source";
BA_ "SignalType" SG_ 1407 DTCI_SRR_SLR_TstNCmpltdOpCyc "ENM";
BA_ "SignalLongName" SG_ 1407 DTCI_SRR_SLR_TstNCmpltdOpCyc "Diagnostic Trouble Code Information Extended - SRR_SLR : Test Not Completed This Operation Cycle";
BA_ "SignalType" SG_ 1407 DTCI_SRR_SLR_TstNCmpltdLstClr "ENM";
BA_ "SignalLongName" SG_ 1407 DTCI_SRR_SLR_TstNCmpltdLstClr "Diagnostic Trouble Code Information Extended - SRR_SLR : Test Not Completed Since Last Clear";
BA_ "SignalType" SG_ 1407 DTCI_SRR_SLR_TstFldOpCyc "ENM";
BA_ "SignalLongName" SG_ 1407 DTCI_SRR_SLR_TstFldOpCyc "Diagnostic Trouble Code Information Extended - SRR_SLR : Test Failed This Operation Cycle";
BA_ "SignalType" SG_ 1407 DTCI_SRR_SLR_TstFldLstClr "ENM";
BA_ "SignalLongName" SG_ 1407 DTCI_SRR_SLR_TstFldLstClr "Diagnostic Trouble Code Information Extended - SRR_SLR : Test Failed Since Last Clear";
BA_ "SignalType" SG_ 1407 DTCI_SRR_SLR_TstFld "ENM";
BA_ "SignalLongName" SG_ 1407 DTCI_SRR_SLR_TstFld "Diagnostic Trouble Code Information Extended - SRR_SLR : Test Failed";
BA_ "SignalType" SG_ 1407 DTCI_SRR_SLR_PndngDTC "ENM";
BA_ "SignalLongName" SG_ 1407 DTCI_SRR_SLR_PndngDTC "Diagnostic Trouble Code Information Extended - SRR_SLR : Pending DTC";
BA_ "SignalType" SG_ 1407 DTCI_SRR_SLR_DTCTriggered "ENM";
BA_ "SignalLongName" SG_ 1407 DTCI_SRR_SLR_DTCTriggered "Diagnostic Trouble Code Information Extended - SRR_SLR : Diagnostic Trouble Code Triggered";
BA_ "SignalType" SG_ 1407 DTCI_SRR_SLR_WrnIndTrggrd "ENM";
BA_ "SignalLongName" SG_ 1407 DTCI_SRR_SLR_WrnIndTrggrd "Diagnostic Trouble Code Information Extended - SRR_SLR : Warning Indicator Triggered";
BA_ "SignalType" SG_ 1407 DTCI_SRR_SLR_WrnIndRqd "ENM";
BA_ "SignalLongName" SG_ 1407 DTCI_SRR_SLR_WrnIndRqd "Diagnostic Trouble Code Information Extended - SRR_SLR : Warning Indicator Requested";
BA_ "SignalLongName" SG_ 1408 DTCI_SRR_SRR_DTCFailType "Diagnostic Trouble Code Information Extended - SRR_SRR : Diagnostic Trouble Code Failure Type";
BA_ "SignalType" SG_ 1408 DTCI_SRR_SRR_CnfrmdDTC "ENM";
BA_ "SignalLongName" SG_ 1408 DTCI_SRR_SRR_CnfrmdDTC "Diagnostic Trouble Code Information Extended - SRR_SRR : Confirmed DTC";
BA_ "SignalType" SG_ 1408 DTCI_SRR_SRR_DTCFaultType "ENM";
BA_ "SignalLongName" SG_ 1408 DTCI_SRR_SRR_DTCFaultType "Diagnostic Trouble Code Information Extended - SRR_SRR : Diagnostic Trouble Code Fault Type";
BA_ "SignalLongName" SG_ 1408 DTCI_SRR_SRR_DTCNumber "Diagnostic Trouble Code Information Extended - SRR_SRR : Diagnostic Trouble Code Number";
BA_ "SignalLongName" SG_ 1408 DTCI_SRR_SRR_DTCSource "Diagnostic Trouble Code Information Extended - SRR_SRR : Diagnostic Trouble Code Source";
BA_ "SignalType" SG_ 1408 DTCI_SRR_SRR_TstNCmpltdOpCyc "ENM";
BA_ "SignalLongName" SG_ 1408 DTCI_SRR_SRR_TstNCmpltdOpCyc "Diagnostic Trouble Code Information Extended - SRR_SRR : Test Not Completed This Operation Cycle";
BA_ "SignalType" SG_ 1408 DTCI_SRR_SRR_TstNCmpltdLstClr "ENM";
BA_ "SignalLongName" SG_ 1408 DTCI_SRR_SRR_TstNCmpltdLstClr "Diagnostic Trouble Code Information Extended - SRR_SRR : Test Not Completed Since Last Clear";
BA_ "SignalType" SG_ 1408 DTCI_SRR_SRR_TstFldOpCyc "ENM";
BA_ "SignalLongName" SG_ 1408 DTCI_SRR_SRR_TstFldOpCyc "Diagnostic Trouble Code Information Extended - SRR_SRR : Test Failed This Operation Cycle";
BA_ "SignalType" SG_ 1408 DTCI_SRR_SRR_TstFldLstClr "ENM";
BA_ "SignalLongName" SG_ 1408 DTCI_SRR_SRR_TstFldLstClr "Diagnostic Trouble Code Information Extended - SRR_SRR : Test Failed Since Last Clear";
BA_ "SignalType" SG_ 1408 DTCI_SRR_SRR_TstFld "ENM";
BA_ "SignalLongName" SG_ 1408 DTCI_SRR_SRR_TstFld "Diagnostic Trouble Code Information Extended - SRR_SRR : Test Failed";
BA_ "SignalType" SG_ 1408 DTCI_SRR_SRR_PndngDTC "ENM";
BA_ "SignalLongName" SG_ 1408 DTCI_SRR_SRR_PndngDTC "Diagnostic Trouble Code Information Extended - SRR_SRR : Pending DTC";
BA_ "SignalType" SG_ 1408 DTCI_SRR_SRR_DTCTriggered "ENM";
BA_ "SignalLongName" SG_ 1408 DTCI_SRR_SRR_DTCTriggered "Diagnostic Trouble Code Information Extended - SRR_SRR : Diagnostic Trouble Code Triggered";
BA_ "SignalType" SG_ 1408 DTCI_SRR_SRR_WrnIndTrggrd "ENM";
BA_ "SignalLongName" SG_ 1408 DTCI_SRR_SRR_WrnIndTrggrd "Diagnostic Trouble Code Information Extended - SRR_SRR : Warning Indicator Triggered";
BA_ "SignalType" SG_ 1408 DTCI_SRR_SRR_WrnIndRqd "ENM";
BA_ "SignalLongName" SG_ 1408 DTCI_SRR_SRR_WrnIndRqd "Diagnostic Trouble Code Information Extended - SRR_SRR : Warning Indicator Requested";
BA_ "SignalLongName" SG_ 1161 DTCI_STC_DTCFailType "Diagnostic Trouble Code Information Extended - STC : Diagnostic Trouble Code Failure Type";
BA_ "SignalType" SG_ 1161 DTCI_STC_CnfrmdDTC "ENM";
BA_ "SignalLongName" SG_ 1161 DTCI_STC_CnfrmdDTC "Diagnostic Trouble Code Information Extended - STC : Confirmed DTC";
BA_ "SignalType" SG_ 1161 DTCI_STC_DTCFaultType "ENM";
BA_ "SignalLongName" SG_ 1161 DTCI_STC_DTCFaultType "Diagnostic Trouble Code Information Extended - STC : Diagnostic Trouble Code Fault Type";
BA_ "SignalLongName" SG_ 1161 DTCI_STC_DTCNumber "Diagnostic Trouble Code Information Extended - STC : Diagnostic Trouble Code Number";
BA_ "SignalLongName" SG_ 1161 DTCI_STC_DTCSource "Diagnostic Trouble Code Information Extended - STC : Diagnostic Trouble Code Source";
BA_ "SignalType" SG_ 1161 DTCI_STC_TstNCmpltdOpCyc "ENM";
BA_ "SignalLongName" SG_ 1161 DTCI_STC_TstNCmpltdOpCyc "Diagnostic Trouble Code Information Extended - STC : Test Not Completed This Operation Cycle";
BA_ "SignalType" SG_ 1161 DTCI_STC_TstNCmpltdLstClr "ENM";
BA_ "SignalLongName" SG_ 1161 DTCI_STC_TstNCmpltdLstClr "Diagnostic Trouble Code Information Extended - STC : Test Not Completed Since Last Clear";
BA_ "SignalType" SG_ 1161 DTCI_STC_TstFldOpCyc "ENM";
BA_ "SignalLongName" SG_ 1161 DTCI_STC_TstFldOpCyc "Diagnostic Trouble Code Information Extended - STC : Test Failed This Operation Cycle";
BA_ "SignalType" SG_ 1161 DTCI_STC_TstFldLstClr "ENM";
BA_ "SignalLongName" SG_ 1161 DTCI_STC_TstFldLstClr "Diagnostic Trouble Code Information Extended - STC : Test Failed Since Last Clear";
BA_ "SignalType" SG_ 1161 DTCI_STC_TstFld "ENM";
BA_ "SignalLongName" SG_ 1161 DTCI_STC_TstFld "Diagnostic Trouble Code Information Extended - STC : Test Failed";
BA_ "SignalType" SG_ 1161 DTCI_STC_PndngDTC "ENM";
BA_ "SignalLongName" SG_ 1161 DTCI_STC_PndngDTC "Diagnostic Trouble Code Information Extended - STC : Pending DTC";
BA_ "SignalType" SG_ 1161 DTCI_STC_DTCTriggered "ENM";
BA_ "SignalLongName" SG_ 1161 DTCI_STC_DTCTriggered "Diagnostic Trouble Code Information Extended - STC : Diagnostic Trouble Code Triggered";
BA_ "SignalType" SG_ 1161 DTCI_STC_WrnIndTrggrd "ENM";
BA_ "SignalLongName" SG_ 1161 DTCI_STC_WrnIndTrggrd "Diagnostic Trouble Code Information Extended - STC : Warning Indicator Triggered";
BA_ "SignalType" SG_ 1161 DTCI_STC_WrnIndRqd "ENM";
BA_ "SignalLongName" SG_ 1161 DTCI_STC_WrnIndRqd "Diagnostic Trouble Code Information Extended - STC : Warning Indicator Requested";
BA_ "SignalLongName" SG_ 1164 DTCI_TCCM3_DTCFailType "Diagnostic Trouble Code Information Extended - TCCM3 : Diagnostic Trouble Code Failure Type";
BA_ "SignalType" SG_ 1164 DTCI_TCCM3_CnfrmdDTC "ENM";
BA_ "SignalLongName" SG_ 1164 DTCI_TCCM3_CnfrmdDTC "Diagnostic Trouble Code Information Extended - TCCM3 : Confirmed DTC";
BA_ "SignalType" SG_ 1164 DTCI_TCCM3_DTCFaultType "ENM";
BA_ "SignalLongName" SG_ 1164 DTCI_TCCM3_DTCFaultType "Diagnostic Trouble Code Information Extended - TCCM3 : Diagnostic Trouble Code Fault Type";
BA_ "SignalLongName" SG_ 1164 DTCI_TCCM3_DTCNumber "Diagnostic Trouble Code Information Extended - TCCM3 : Diagnostic Trouble Code Number";
BA_ "SignalLongName" SG_ 1164 DTCI_TCCM3_DTCSource "Diagnostic Trouble Code Information Extended - TCCM3 : Diagnostic Trouble Code Source";
BA_ "SignalType" SG_ 1164 DTCI_TCCM3_TstNCmpltdOpCyc "ENM";
BA_ "SignalLongName" SG_ 1164 DTCI_TCCM3_TstNCmpltdOpCyc "Diagnostic Trouble Code Information Extended - TCCM3 : Test Not Completed This Operation Cycle";
BA_ "SignalType" SG_ 1164 DTCI_TCCM3_TstNCmpltdLstClr "ENM";
BA_ "SignalLongName" SG_ 1164 DTCI_TCCM3_TstNCmpltdLstClr "Diagnostic Trouble Code Information Extended - TCCM3 : Test Not Completed Since Last Clear";
BA_ "SignalType" SG_ 1164 DTCI_TCCM3_TstFldOpCyc "ENM";
BA_ "SignalLongName" SG_ 1164 DTCI_TCCM3_TstFldOpCyc "Diagnostic Trouble Code Information Extended - TCCM3 : Test Failed This Operation Cycle";
BA_ "SignalType" SG_ 1164 DTCI_TCCM3_TstFldLstClr "ENM";
BA_ "SignalLongName" SG_ 1164 DTCI_TCCM3_TstFldLstClr "Diagnostic Trouble Code Information Extended - TCCM3 : Test Failed Since Last Clear";
BA_ "SignalType" SG_ 1164 DTCI_TCCM3_TstFld "ENM";
BA_ "SignalLongName" SG_ 1164 DTCI_TCCM3_TstFld "Diagnostic Trouble Code Information Extended - TCCM3 : Test Failed";
BA_ "SignalType" SG_ 1164 DTCI_TCCM3_PndngDTC "ENM";
BA_ "SignalLongName" SG_ 1164 DTCI_TCCM3_PndngDTC "Diagnostic Trouble Code Information Extended - TCCM3 : Pending DTC";
BA_ "SignalType" SG_ 1164 DTCI_TCCM3_DTCTriggered "ENM";
BA_ "SignalLongName" SG_ 1164 DTCI_TCCM3_DTCTriggered "Diagnostic Trouble Code Information Extended - TCCM3 : Diagnostic Trouble Code Triggered";
BA_ "SignalType" SG_ 1164 DTCI_TCCM3_WrnIndTrggrd "ENM";
BA_ "SignalLongName" SG_ 1164 DTCI_TCCM3_WrnIndTrggrd "Diagnostic Trouble Code Information Extended - TCCM3 : Warning Indicator Triggered";
BA_ "SignalType" SG_ 1164 DTCI_TCCM3_WrnIndRqd "ENM";
BA_ "SignalLongName" SG_ 1164 DTCI_TCCM3_WrnIndRqd "Diagnostic Trouble Code Information Extended - TCCM3 : Warning Indicator Requested";
BA_ "SignalLongName" SG_ 1163 DTCI_TCCM_DTCFailType "Diagnostic Trouble Code Information Extended - TCCM : Diagnostic Trouble Code Failure Type";
BA_ "SignalType" SG_ 1163 DTCI_TCCM_CnfrmdDTC "ENM";
BA_ "SignalLongName" SG_ 1163 DTCI_TCCM_CnfrmdDTC "Diagnostic Trouble Code Information Extended - TCCM : Confirmed DTC";
BA_ "SignalType" SG_ 1163 DTCI_TCCM_DTCFaultType "ENM";
BA_ "SignalLongName" SG_ 1163 DTCI_TCCM_DTCFaultType "Diagnostic Trouble Code Information Extended - TCCM : Diagnostic Trouble Code Fault Type";
BA_ "SignalLongName" SG_ 1163 DTCI_TCCM_DTCNumber "Diagnostic Trouble Code Information Extended - TCCM : Diagnostic Trouble Code Number";
BA_ "SignalLongName" SG_ 1163 DTCI_TCCM_DTCSource "Diagnostic Trouble Code Information Extended - TCCM : Diagnostic Trouble Code Source";
BA_ "SignalType" SG_ 1163 DTCI_TCCM_TstNCmpltdOpCyc "ENM";
BA_ "SignalLongName" SG_ 1163 DTCI_TCCM_TstNCmpltdOpCyc "Diagnostic Trouble Code Information Extended - TCCM : Test Not Completed This Operation Cycle";
BA_ "SignalType" SG_ 1163 DTCI_TCCM_TstNCmpltdLstClr "ENM";
BA_ "SignalLongName" SG_ 1163 DTCI_TCCM_TstNCmpltdLstClr "Diagnostic Trouble Code Information Extended - TCCM : Test Not Completed Since Last Clear";
BA_ "SignalType" SG_ 1163 DTCI_TCCM_TstFldOpCyc "ENM";
BA_ "SignalLongName" SG_ 1163 DTCI_TCCM_TstFldOpCyc "Diagnostic Trouble Code Information Extended - TCCM : Test Failed This Operation Cycle";
BA_ "SignalType" SG_ 1163 DTCI_TCCM_TstFldLstClr "ENM";
BA_ "SignalLongName" SG_ 1163 DTCI_TCCM_TstFldLstClr "Diagnostic Trouble Code Information Extended - TCCM : Test Failed Since Last Clear";
BA_ "SignalType" SG_ 1163 DTCI_TCCM_TstFld "ENM";
BA_ "SignalLongName" SG_ 1163 DTCI_TCCM_TstFld "Diagnostic Trouble Code Information Extended - TCCM : Test Failed";
BA_ "SignalType" SG_ 1163 DTCI_TCCM_PndngDTC "ENM";
BA_ "SignalLongName" SG_ 1163 DTCI_TCCM_PndngDTC "Diagnostic Trouble Code Information Extended - TCCM : Pending DTC";
BA_ "SignalType" SG_ 1163 DTCI_TCCM_DTCTriggered "ENM";
BA_ "SignalLongName" SG_ 1163 DTCI_TCCM_DTCTriggered "Diagnostic Trouble Code Information Extended - TCCM : Diagnostic Trouble Code Triggered";
BA_ "SignalType" SG_ 1163 DTCI_TCCM_WrnIndTrggrd "ENM";
BA_ "SignalLongName" SG_ 1163 DTCI_TCCM_WrnIndTrggrd "Diagnostic Trouble Code Information Extended - TCCM : Warning Indicator Triggered";
BA_ "SignalType" SG_ 1163 DTCI_TCCM_WrnIndRqd "ENM";
BA_ "SignalLongName" SG_ 1163 DTCI_TCCM_WrnIndRqd "Diagnostic Trouble Code Information Extended - TCCM : Warning Indicator Requested";
BA_ "SignalLongName" SG_ 1165 DTCI_TCM_DTCFailType "Diagnostic Trouble Code Information Extended - TCM : Diagnostic Trouble Code Failure Type";
BA_ "SignalType" SG_ 1165 DTCI_TCM_CnfrmdDTC "ENM";
BA_ "SignalLongName" SG_ 1165 DTCI_TCM_CnfrmdDTC "Diagnostic Trouble Code Information Extended - TCM : Confirmed DTC";
BA_ "SignalType" SG_ 1165 DTCI_TCM_DTCFaultType "ENM";
BA_ "SignalLongName" SG_ 1165 DTCI_TCM_DTCFaultType "Diagnostic Trouble Code Information Extended - TCM : Diagnostic Trouble Code Fault Type";
BA_ "SignalLongName" SG_ 1165 DTCI_TCM_DTCNumber "Diagnostic Trouble Code Information Extended - TCM : Diagnostic Trouble Code Number";
BA_ "SignalLongName" SG_ 1165 DTCI_TCM_DTCSource "Diagnostic Trouble Code Information Extended - TCM : Diagnostic Trouble Code Source";
BA_ "SignalType" SG_ 1165 DTCI_TCM_TstNCmpltdOpCyc "ENM";
BA_ "SignalLongName" SG_ 1165 DTCI_TCM_TstNCmpltdOpCyc "Diagnostic Trouble Code Information Extended - TCM : Test Not Completed This Operation Cycle";
BA_ "SignalType" SG_ 1165 DTCI_TCM_TstNCmpltdLstClr "ENM";
BA_ "SignalLongName" SG_ 1165 DTCI_TCM_TstNCmpltdLstClr "Diagnostic Trouble Code Information Extended - TCM : Test Not Completed Since Last Clear";
BA_ "SignalType" SG_ 1165 DTCI_TCM_TstFldOpCyc "ENM";
BA_ "SignalLongName" SG_ 1165 DTCI_TCM_TstFldOpCyc "Diagnostic Trouble Code Information Extended - TCM : Test Failed This Operation Cycle";
BA_ "SignalType" SG_ 1165 DTCI_TCM_TstFldLstClr "ENM";
BA_ "SignalLongName" SG_ 1165 DTCI_TCM_TstFldLstClr "Diagnostic Trouble Code Information Extended - TCM : Test Failed Since Last Clear";
BA_ "SignalType" SG_ 1165 DTCI_TCM_TstFld "ENM";
BA_ "SignalLongName" SG_ 1165 DTCI_TCM_TstFld "Diagnostic Trouble Code Information Extended - TCM : Test Failed";
BA_ "SignalType" SG_ 1165 DTCI_TCM_PndngDTC "ENM";
BA_ "SignalLongName" SG_ 1165 DTCI_TCM_PndngDTC "Diagnostic Trouble Code Information Extended - TCM : Pending DTC";
BA_ "SignalType" SG_ 1165 DTCI_TCM_DTCTriggered "ENM";
BA_ "SignalLongName" SG_ 1165 DTCI_TCM_DTCTriggered "Diagnostic Trouble Code Information Extended - TCM : Diagnostic Trouble Code Triggered";
BA_ "SignalType" SG_ 1165 DTCI_TCM_WrnIndTrggrd "ENM";
BA_ "SignalLongName" SG_ 1165 DTCI_TCM_WrnIndTrggrd "Diagnostic Trouble Code Information Extended - TCM : Warning Indicator Triggered";
BA_ "SignalType" SG_ 1165 DTCI_TCM_WrnIndRqd "ENM";
BA_ "SignalLongName" SG_ 1165 DTCI_TCM_WrnIndRqd "Diagnostic Trouble Code Information Extended - TCM : Warning Indicator Requested";
BA_ "SignalLongName" SG_ 1331 DTCI_TCP_DTCFailType "Diagnostic Trouble Code Information Extended - TCP : Diagnostic Trouble Code Failure Type";
BA_ "SignalType" SG_ 1331 DTCI_TCP_CnfrmdDTC "ENM";
BA_ "SignalLongName" SG_ 1331 DTCI_TCP_CnfrmdDTC "Diagnostic Trouble Code Information Extended - TCP : Confirmed DTC";
BA_ "SignalType" SG_ 1331 DTCI_TCP_DTCFaultType "ENM";
BA_ "SignalLongName" SG_ 1331 DTCI_TCP_DTCFaultType "Diagnostic Trouble Code Information Extended - TCP : Diagnostic Trouble Code Fault Type";
BA_ "SignalLongName" SG_ 1331 DTCI_TCP_DTCNumber "Diagnostic Trouble Code Information Extended - TCP : Diagnostic Trouble Code Number";
BA_ "SignalLongName" SG_ 1331 DTCI_TCP_DTCSource "Diagnostic Trouble Code Information Extended - TCP : Diagnostic Trouble Code Source";
BA_ "SignalType" SG_ 1331 DTCI_TCP_TstNCmpltdOpCyc "ENM";
BA_ "SignalLongName" SG_ 1331 DTCI_TCP_TstNCmpltdOpCyc "Diagnostic Trouble Code Information Extended - TCP : Test Not Completed This Operation Cycle";
BA_ "SignalType" SG_ 1331 DTCI_TCP_TstNCmpltdLstClr "ENM";
BA_ "SignalLongName" SG_ 1331 DTCI_TCP_TstNCmpltdLstClr "Diagnostic Trouble Code Information Extended - TCP : Test Not Completed Since Last Clear";
BA_ "SignalType" SG_ 1331 DTCI_TCP_TstFldOpCyc "ENM";
BA_ "SignalLongName" SG_ 1331 DTCI_TCP_TstFldOpCyc "Diagnostic Trouble Code Information Extended - TCP : Test Failed This Operation Cycle";
BA_ "SignalType" SG_ 1331 DTCI_TCP_TstFldLstClr "ENM";
BA_ "SignalLongName" SG_ 1331 DTCI_TCP_TstFldLstClr "Diagnostic Trouble Code Information Extended - TCP : Test Failed Since Last Clear";
BA_ "SignalType" SG_ 1331 DTCI_TCP_TstFld "ENM";
BA_ "SignalLongName" SG_ 1331 DTCI_TCP_TstFld "Diagnostic Trouble Code Information Extended - TCP : Test Failed";
BA_ "SignalType" SG_ 1331 DTCI_TCP_PndngDTC "ENM";
BA_ "SignalLongName" SG_ 1331 DTCI_TCP_PndngDTC "Diagnostic Trouble Code Information Extended - TCP : Pending DTC";
BA_ "SignalType" SG_ 1331 DTCI_TCP_DTCTriggered "ENM";
BA_ "SignalLongName" SG_ 1331 DTCI_TCP_DTCTriggered "Diagnostic Trouble Code Information Extended - TCP : Diagnostic Trouble Code Triggered";
BA_ "SignalType" SG_ 1331 DTCI_TCP_WrnIndTrggrd "ENM";
BA_ "SignalLongName" SG_ 1331 DTCI_TCP_WrnIndTrggrd "Diagnostic Trouble Code Information Extended - TCP : Warning Indicator Triggered";
BA_ "SignalType" SG_ 1331 DTCI_TCP_WrnIndRqd "ENM";
BA_ "SignalLongName" SG_ 1331 DTCI_TCP_WrnIndRqd "Diagnostic Trouble Code Information Extended - TCP : Warning Indicator Requested";
BA_ "SignalLongName" SG_ 1166 DTCI_TIM_DTCFailType "Diagnostic Trouble Code Information Extended - TIM : Diagnostic Trouble Code Failure Type";
BA_ "SignalType" SG_ 1166 DTCI_TIM_CnfrmdDTC "ENM";
BA_ "SignalLongName" SG_ 1166 DTCI_TIM_CnfrmdDTC "Diagnostic Trouble Code Information Extended - TIM : Confirmed DTC";
BA_ "SignalType" SG_ 1166 DTCI_TIM_DTCFaultType "ENM";
BA_ "SignalLongName" SG_ 1166 DTCI_TIM_DTCFaultType "Diagnostic Trouble Code Information Extended - TIM : Diagnostic Trouble Code Fault Type";
BA_ "SignalLongName" SG_ 1166 DTCI_TIM_DTCNumber "Diagnostic Trouble Code Information Extended - TIM : Diagnostic Trouble Code Number";
BA_ "SignalLongName" SG_ 1166 DTCI_TIM_DTCSource "Diagnostic Trouble Code Information Extended - TIM : Diagnostic Trouble Code Source";
BA_ "SignalType" SG_ 1166 DTCI_TIM_TstNCmpltdOpCyc "ENM";
BA_ "SignalLongName" SG_ 1166 DTCI_TIM_TstNCmpltdOpCyc "Diagnostic Trouble Code Information Extended - TIM : Test Not Completed This Operation Cycle";
BA_ "SignalType" SG_ 1166 DTCI_TIM_TstNCmpltdLstClr "ENM";
BA_ "SignalLongName" SG_ 1166 DTCI_TIM_TstNCmpltdLstClr "Diagnostic Trouble Code Information Extended - TIM : Test Not Completed Since Last Clear";
BA_ "SignalType" SG_ 1166 DTCI_TIM_TstFldOpCyc "ENM";
BA_ "SignalLongName" SG_ 1166 DTCI_TIM_TstFldOpCyc "Diagnostic Trouble Code Information Extended - TIM : Test Failed This Operation Cycle";
BA_ "SignalType" SG_ 1166 DTCI_TIM_TstFldLstClr "ENM";
BA_ "SignalLongName" SG_ 1166 DTCI_TIM_TstFldLstClr "Diagnostic Trouble Code Information Extended - TIM : Test Failed Since Last Clear";
BA_ "SignalType" SG_ 1166 DTCI_TIM_TstFld "ENM";
BA_ "SignalLongName" SG_ 1166 DTCI_TIM_TstFld "Diagnostic Trouble Code Information Extended - TIM : Test Failed";
BA_ "SignalType" SG_ 1166 DTCI_TIM_PndngDTC "ENM";
BA_ "SignalLongName" SG_ 1166 DTCI_TIM_PndngDTC "Diagnostic Trouble Code Information Extended - TIM : Pending DTC";
BA_ "SignalType" SG_ 1166 DTCI_TIM_DTCTriggered "ENM";
BA_ "SignalLongName" SG_ 1166 DTCI_TIM_DTCTriggered "Diagnostic Trouble Code Information Extended - TIM : Diagnostic Trouble Code Triggered";
BA_ "SignalType" SG_ 1166 DTCI_TIM_WrnIndTrggrd "ENM";
BA_ "SignalLongName" SG_ 1166 DTCI_TIM_WrnIndTrggrd "Diagnostic Trouble Code Information Extended - TIM : Warning Indicator Triggered";
BA_ "SignalType" SG_ 1166 DTCI_TIM_WrnIndRqd "ENM";
BA_ "SignalLongName" SG_ 1166 DTCI_TIM_WrnIndRqd "Diagnostic Trouble Code Information Extended - TIM : Warning Indicator Requested";
BA_ "SignalLongName" SG_ 1437 DTCI_UVM_DTCFailType "Diagnostic Trouble Code Information Extended - UVM : Diagnostic Trouble Code Failure Type";
BA_ "SignalType" SG_ 1437 DTCI_UVM_CnfrmdDTC "ENM";
BA_ "SignalLongName" SG_ 1437 DTCI_UVM_CnfrmdDTC "Diagnostic Trouble Code Information Extended - UVM : Confirmed DTC";
BA_ "SignalType" SG_ 1437 DTCI_UVM_DTCFaultType "ENM";
BA_ "SignalLongName" SG_ 1437 DTCI_UVM_DTCFaultType "Diagnostic Trouble Code Information Extended - UVM : Diagnostic Trouble Code Fault Type";
BA_ "SignalLongName" SG_ 1437 DTCI_UVM_DTCNumber "Diagnostic Trouble Code Information Extended - UVM : Diagnostic Trouble Code Number";
BA_ "SignalLongName" SG_ 1437 DTCI_UVM_DTCSource "Diagnostic Trouble Code Information Extended - UVM : Diagnostic Trouble Code Source";
BA_ "SignalType" SG_ 1437 DTCI_UVM_TstNCmpltdOpCyc "ENM";
BA_ "SignalLongName" SG_ 1437 DTCI_UVM_TstNCmpltdOpCyc "Diagnostic Trouble Code Information Extended - UVM : Test Not Completed This Operation Cycle";
BA_ "SignalType" SG_ 1437 DTCI_UVM_TstNCmpltdLstClr "ENM";
BA_ "SignalLongName" SG_ 1437 DTCI_UVM_TstNCmpltdLstClr "Diagnostic Trouble Code Information Extended - UVM : Test Not Completed Since Last Clear";
BA_ "SignalType" SG_ 1437 DTCI_UVM_TstFldOpCyc "ENM";
BA_ "SignalLongName" SG_ 1437 DTCI_UVM_TstFldOpCyc "Diagnostic Trouble Code Information Extended - UVM : Test Failed This Operation Cycle";
BA_ "SignalType" SG_ 1437 DTCI_UVM_TstFldLstClr "ENM";
BA_ "SignalLongName" SG_ 1437 DTCI_UVM_TstFldLstClr "Diagnostic Trouble Code Information Extended - UVM : Test Failed Since Last Clear";
BA_ "SignalType" SG_ 1437 DTCI_UVM_TstFld "ENM";
BA_ "SignalLongName" SG_ 1437 DTCI_UVM_TstFld "Diagnostic Trouble Code Information Extended - UVM : Test Failed";
BA_ "SignalType" SG_ 1437 DTCI_UVM_PndngDTC "ENM";
BA_ "SignalLongName" SG_ 1437 DTCI_UVM_PndngDTC "Diagnostic Trouble Code Information Extended - UVM : Pending DTC";
BA_ "SignalType" SG_ 1437 DTCI_UVM_DTCTriggered "ENM";
BA_ "SignalLongName" SG_ 1437 DTCI_UVM_DTCTriggered "Diagnostic Trouble Code Information Extended - UVM : Diagnostic Trouble Code Triggered";
BA_ "SignalType" SG_ 1437 DTCI_UVM_WrnIndTrggrd "ENM";
BA_ "SignalLongName" SG_ 1437 DTCI_UVM_WrnIndTrggrd "Diagnostic Trouble Code Information Extended - UVM : Warning Indicator Triggered";
BA_ "SignalType" SG_ 1437 DTCI_UVM_WrnIndRqd "ENM";
BA_ "SignalLongName" SG_ 1437 DTCI_UVM_WrnIndRqd "Diagnostic Trouble Code Information Extended - UVM : Warning Indicator Requested";
BA_ "SignalLongName" SG_ 1341 DTCI_VKM_DTCFailType "Diagnostic Trouble Code Information Extended - VKM : Diagnostic Trouble Code Failure Type";
BA_ "SignalType" SG_ 1341 DTCI_VKM_CnfrmdDTC "ENM";
BA_ "SignalLongName" SG_ 1341 DTCI_VKM_CnfrmdDTC "Diagnostic Trouble Code Information Extended - VKM : Confirmed DTC";
BA_ "SignalType" SG_ 1341 DTCI_VKM_DTCFaultType "ENM";
BA_ "SignalLongName" SG_ 1341 DTCI_VKM_DTCFaultType "Diagnostic Trouble Code Information Extended - VKM : Diagnostic Trouble Code Fault Type";
BA_ "SignalLongName" SG_ 1341 DTCI_VKM_DTCNumber "Diagnostic Trouble Code Information Extended - VKM : Diagnostic Trouble Code Number";
BA_ "SignalLongName" SG_ 1341 DTCI_VKM_DTCSource "Diagnostic Trouble Code Information Extended - VKM : Diagnostic Trouble Code Source";
BA_ "SignalType" SG_ 1341 DTCI_VKM_TstNCmpltdOpCyc "ENM";
BA_ "SignalLongName" SG_ 1341 DTCI_VKM_TstNCmpltdOpCyc "Diagnostic Trouble Code Information Extended - VKM : Test Not Completed This Operation Cycle";
BA_ "SignalType" SG_ 1341 DTCI_VKM_TstNCmpltdLstClr "ENM";
BA_ "SignalLongName" SG_ 1341 DTCI_VKM_TstNCmpltdLstClr "Diagnostic Trouble Code Information Extended - VKM : Test Not Completed Since Last Clear";
BA_ "SignalType" SG_ 1341 DTCI_VKM_TstFldOpCyc "ENM";
BA_ "SignalLongName" SG_ 1341 DTCI_VKM_TstFldOpCyc "Diagnostic Trouble Code Information Extended - VKM : Test Failed This Operation Cycle";
BA_ "SignalType" SG_ 1341 DTCI_VKM_TstFldLstClr "ENM";
BA_ "SignalLongName" SG_ 1341 DTCI_VKM_TstFldLstClr "Diagnostic Trouble Code Information Extended - VKM : Test Failed Since Last Clear";
BA_ "SignalType" SG_ 1341 DTCI_VKM_TstFld "ENM";
BA_ "SignalLongName" SG_ 1341 DTCI_VKM_TstFld "Diagnostic Trouble Code Information Extended - VKM : Test Failed";
BA_ "SignalType" SG_ 1341 DTCI_VKM_PndngDTC "ENM";
BA_ "SignalLongName" SG_ 1341 DTCI_VKM_PndngDTC "Diagnostic Trouble Code Information Extended - VKM : Pending DTC";
BA_ "SignalType" SG_ 1341 DTCI_VKM_DTCTriggered "ENM";
BA_ "SignalLongName" SG_ 1341 DTCI_VKM_DTCTriggered "Diagnostic Trouble Code Information Extended - VKM : Diagnostic Trouble Code Triggered";
BA_ "SignalType" SG_ 1341 DTCI_VKM_WrnIndTrggrd "ENM";
BA_ "SignalLongName" SG_ 1341 DTCI_VKM_WrnIndTrggrd "Diagnostic Trouble Code Information Extended - VKM : Warning Indicator Triggered";
BA_ "SignalType" SG_ 1341 DTCI_VKM_WrnIndRqd "ENM";
BA_ "SignalLongName" SG_ 1341 DTCI_VKM_WrnIndRqd "Diagnostic Trouble Code Information Extended - VKM : Warning Indicator Requested";
BA_ "SignalLongName" SG_ 1389 DTCI_VLM_DTCFailType "Diagnostic Trouble Code Information Extended - VLM : Diagnostic Trouble Code Failure Type";
BA_ "SignalType" SG_ 1389 DTCI_VLM_CnfrmdDTC "ENM";
BA_ "SignalLongName" SG_ 1389 DTCI_VLM_CnfrmdDTC "Diagnostic Trouble Code Information Extended - VLM : Confirmed DTC";
BA_ "SignalType" SG_ 1389 DTCI_VLM_DTCFaultType "ENM";
BA_ "SignalLongName" SG_ 1389 DTCI_VLM_DTCFaultType "Diagnostic Trouble Code Information Extended - VLM : Diagnostic Trouble Code Fault Type";
BA_ "SignalLongName" SG_ 1389 DTCI_VLM_DTCNumber "Diagnostic Trouble Code Information Extended - VLM : Diagnostic Trouble Code Number";
BA_ "SignalLongName" SG_ 1389 DTCI_VLM_DTCSource "Diagnostic Trouble Code Information Extended - VLM : Diagnostic Trouble Code Source";
BA_ "SignalType" SG_ 1389 DTCI_VLM_TstNCmpltdOpCyc "ENM";
BA_ "SignalLongName" SG_ 1389 DTCI_VLM_TstNCmpltdOpCyc "Diagnostic Trouble Code Information Extended - VLM : Test Not Completed This Operation Cycle";
BA_ "SignalType" SG_ 1389 DTCI_VLM_TstNCmpltdLstClr "ENM";
BA_ "SignalLongName" SG_ 1389 DTCI_VLM_TstNCmpltdLstClr "Diagnostic Trouble Code Information Extended - VLM : Test Not Completed Since Last Clear";
BA_ "SignalType" SG_ 1389 DTCI_VLM_TstFldOpCyc "ENM";
BA_ "SignalLongName" SG_ 1389 DTCI_VLM_TstFldOpCyc "Diagnostic Trouble Code Information Extended - VLM : Test Failed This Operation Cycle";
BA_ "SignalType" SG_ 1389 DTCI_VLM_TstFldLstClr "ENM";
BA_ "SignalLongName" SG_ 1389 DTCI_VLM_TstFldLstClr "Diagnostic Trouble Code Information Extended - VLM : Test Failed Since Last Clear";
BA_ "SignalType" SG_ 1389 DTCI_VLM_TstFld "ENM";
BA_ "SignalLongName" SG_ 1389 DTCI_VLM_TstFld "Diagnostic Trouble Code Information Extended - VLM : Test Failed";
BA_ "SignalType" SG_ 1389 DTCI_VLM_PndngDTC "ENM";
BA_ "SignalLongName" SG_ 1389 DTCI_VLM_PndngDTC "Diagnostic Trouble Code Information Extended - VLM : Pending DTC";
BA_ "SignalType" SG_ 1389 DTCI_VLM_DTCTriggered "ENM";
BA_ "SignalLongName" SG_ 1389 DTCI_VLM_DTCTriggered "Diagnostic Trouble Code Information Extended - VLM : Diagnostic Trouble Code Triggered";
BA_ "SignalType" SG_ 1389 DTCI_VLM_WrnIndTrggrd "ENM";
BA_ "SignalLongName" SG_ 1389 DTCI_VLM_WrnIndTrggrd "Diagnostic Trouble Code Information Extended - VLM : Warning Indicator Triggered";
BA_ "SignalType" SG_ 1389 DTCI_VLM_WrnIndRqd "ENM";
BA_ "SignalLongName" SG_ 1389 DTCI_VLM_WrnIndRqd "Diagnostic Trouble Code Information Extended - VLM : Warning Indicator Requested";
BA_ "SignalLongName" SG_ 1167 DTCI_VPM_DTCFailType "Diagnostic Trouble Code Information Extended - VPM : Diagnostic Trouble Code Failure Type";
BA_ "SignalType" SG_ 1167 DTCI_VPM_CnfrmdDTC "ENM";
BA_ "SignalLongName" SG_ 1167 DTCI_VPM_CnfrmdDTC "Diagnostic Trouble Code Information Extended - VPM : Confirmed DTC";
BA_ "SignalType" SG_ 1167 DTCI_VPM_DTCFaultType "ENM";
BA_ "SignalLongName" SG_ 1167 DTCI_VPM_DTCFaultType "Diagnostic Trouble Code Information Extended - VPM : Diagnostic Trouble Code Fault Type";
BA_ "SignalLongName" SG_ 1167 DTCI_VPM_DTCNumber "Diagnostic Trouble Code Information Extended - VPM : Diagnostic Trouble Code Number";
BA_ "SignalLongName" SG_ 1167 DTCI_VPM_DTCSource "Diagnostic Trouble Code Information Extended - VPM : Diagnostic Trouble Code Source";
BA_ "SignalType" SG_ 1167 DTCI_VPM_TstNCmpltdOpCyc "ENM";
BA_ "SignalLongName" SG_ 1167 DTCI_VPM_TstNCmpltdOpCyc "Diagnostic Trouble Code Information Extended - VPM : Test Not Completed This Operation Cycle";
BA_ "SignalType" SG_ 1167 DTCI_VPM_TstNCmpltdLstClr "ENM";
BA_ "SignalLongName" SG_ 1167 DTCI_VPM_TstNCmpltdLstClr "Diagnostic Trouble Code Information Extended - VPM : Test Not Completed Since Last Clear";
BA_ "SignalType" SG_ 1167 DTCI_VPM_TstFldOpCyc "ENM";
BA_ "SignalLongName" SG_ 1167 DTCI_VPM_TstFldOpCyc "Diagnostic Trouble Code Information Extended - VPM : Test Failed This Operation Cycle";
BA_ "SignalType" SG_ 1167 DTCI_VPM_TstFldLstClr "ENM";
BA_ "SignalLongName" SG_ 1167 DTCI_VPM_TstFldLstClr "Diagnostic Trouble Code Information Extended - VPM : Test Failed Since Last Clear";
BA_ "SignalType" SG_ 1167 DTCI_VPM_TstFld "ENM";
BA_ "SignalLongName" SG_ 1167 DTCI_VPM_TstFld "Diagnostic Trouble Code Information Extended - VPM : Test Failed";
BA_ "SignalType" SG_ 1167 DTCI_VPM_PndngDTC "ENM";
BA_ "SignalLongName" SG_ 1167 DTCI_VPM_PndngDTC "Diagnostic Trouble Code Information Extended - VPM : Pending DTC";
BA_ "SignalType" SG_ 1167 DTCI_VPM_DTCTriggered "ENM";
BA_ "SignalLongName" SG_ 1167 DTCI_VPM_DTCTriggered "Diagnostic Trouble Code Information Extended - VPM : Diagnostic Trouble Code Triggered";
BA_ "SignalType" SG_ 1167 DTCI_VPM_WrnIndTrggrd "ENM";
BA_ "SignalLongName" SG_ 1167 DTCI_VPM_WrnIndTrggrd "Diagnostic Trouble Code Information Extended - VPM : Warning Indicator Triggered";
BA_ "SignalType" SG_ 1167 DTCI_VPM_WrnIndRqd "ENM";
BA_ "SignalLongName" SG_ 1167 DTCI_VPM_WrnIndRqd "Diagnostic Trouble Code Information Extended - VPM : Warning Indicator Requested";
VAL_ 1315 DTCI_IPC_CnfrmdDTC 0 "FALSE" 1 "TRUE" ;
VAL_ 1315 DTCI_IPC_DTCFaultType 0 "Not Supported" 1 "Type A" 2 "Type B" 3 "Type C" ;
VAL_ 1315 DTCI_IPC_TstNCmpltdOpCyc 0 "FALSE" 1 "TRUE" ;
VAL_ 1315 DTCI_IPC_TstNCmpltdLstClr 0 "FALSE" 1 "TRUE" ;
VAL_ 1315 DTCI_IPC_TstFldOpCyc 0 "FALSE" 1 "TRUE" ;
VAL_ 1315 DTCI_IPC_TstFldLstClr 0 "FALSE" 1 "TRUE" ;
VAL_ 1315 DTCI_IPC_TstFld 0 "FALSE" 1 "TRUE" ;
VAL_ 1315 DTCI_IPC_PndngDTC 0 "FALSE" 1 "TRUE" ;
VAL_ 1315 DTCI_IPC_DTCTriggered 0 "FALSE" 1 "TRUE" ;
VAL_ 1315 DTCI_IPC_WrnIndTrggrd 0 "FALSE" 1 "TRUE" ;
VAL_ 1315 DTCI_IPC_WrnIndRqd 0 "FALSE" 1 "TRUE" ;
VAL_ 1395 DTCI_LIB1_CnfrmdDTC 0 "FALSE" 1 "TRUE" ;
VAL_ 1395 DTCI_LIB1_DTCFaultType 0 "Not Supported" 1 "Type A" 2 "Type B" 3 "Type C" ;
VAL_ 1395 DTCI_LIB1_TstNCmpltdOpCyc 0 "FALSE" 1 "TRUE" ;
VAL_ 1395 DTCI_LIB1_TstNCmpltdLstClr 0 "FALSE" 1 "TRUE" ;
VAL_ 1395 DTCI_LIB1_TstFldOpCyc 0 "FALSE" 1 "TRUE" ;
VAL_ 1395 DTCI_LIB1_TstFldLstClr 0 "FALSE" 1 "TRUE" ;
VAL_ 1395 DTCI_LIB1_TstFld 0 "FALSE" 1 "TRUE" ;
VAL_ 1395 DTCI_LIB1_PndngDTC 0 "FALSE" 1 "TRUE" ;
VAL_ 1395 DTCI_LIB1_DTCTriggered 0 "FALSE" 1 "TRUE" ;
VAL_ 1395 DTCI_LIB1_WrnIndTrggrd 0 "FALSE" 1 "TRUE" ;
VAL_ 1395 DTCI_LIB1_WrnIndRqd 0 "FALSE" 1 "TRUE" ;
VAL_ 1379 DTCI_LRR_HC_CnfrmdDTC 0 "FALSE" 1 "TRUE" ;
VAL_ 1379 DTCI_LRR_HC_DTCFaultType 0 "Not Supported" 1 "Type A" 2 "Type B" 3 "Type C" ;
VAL_ 1379 DTCI_LRR_HC_TstNCmpltdOpCyc 0 "FALSE" 1 "TRUE" ;
VAL_ 1379 DTCI_LRR_HC_TstNCmpltdLstClr 0 "FALSE" 1 "TRUE" ;
VAL_ 1379 DTCI_LRR_HC_TstFldOpCyc 0 "FALSE" 1 "TRUE" ;
VAL_ 1379 DTCI_LRR_HC_TstFldLstClr 0 "FALSE" 1 "TRUE" ;
VAL_ 1379 DTCI_LRR_HC_TstFld 0 "FALSE" 1 "TRUE" ;
VAL_ 1379 DTCI_LRR_HC_PndngDTC 0 "FALSE" 1 "TRUE" ;
VAL_ 1379 DTCI_LRR_HC_DTCTriggered 0 "FALSE" 1 "TRUE" ;
VAL_ 1379 DTCI_LRR_HC_WrnIndTrggrd 0 "FALSE" 1 "TRUE" ;
VAL_ 1379 DTCI_LRR_HC_WrnIndRqd 0 "FALSE" 1 "TRUE" ;
VAL_ 1136 DTCI_LRR_CnfrmdDTC 0 "FALSE" 1 "TRUE" ;
VAL_ 1136 DTCI_LRR_DTCFaultType 0 "Not Supported" 1 "Type A" 2 "Type B" 3 "Type C" ;
VAL_ 1136 DTCI_LRR_TstNCmpltdOpCyc 0 "FALSE" 1 "TRUE" ;
VAL_ 1136 DTCI_LRR_TstNCmpltdLstClr 0 "FALSE" 1 "TRUE" ;
VAL_ 1136 DTCI_LRR_TstFldOpCyc 0 "FALSE" 1 "TRUE" ;
VAL_ 1136 DTCI_LRR_TstFldLstClr 0 "FALSE" 1 "TRUE" ;
VAL_ 1136 DTCI_LRR_TstFld 0 "FALSE" 1 "TRUE" ;
VAL_ 1136 DTCI_LRR_PndngDTC 0 "FALSE" 1 "TRUE" ;
VAL_ 1136 DTCI_LRR_DTCTriggered 0 "FALSE" 1 "TRUE" ;
VAL_ 1136 DTCI_LRR_WrnIndTrggrd 0 "FALSE" 1 "TRUE" ;
VAL_ 1136 DTCI_LRR_WrnIndRqd 0 "FALSE" 1 "TRUE" ;
VAL_ 1322 DTCI_MFC_CnfrmdDTC 0 "FALSE" 1 "TRUE" ;
VAL_ 1322 DTCI_MFC_DTCFaultType 0 "Not Supported" 1 "Type A" 2 "Type B" 3 "Type C" ;
VAL_ 1322 DTCI_MFC_TstNCmpltdOpCyc 0 "FALSE" 1 "TRUE" ;
VAL_ 1322 DTCI_MFC_TstNCmpltdLstClr 0 "FALSE" 1 "TRUE" ;
VAL_ 1322 DTCI_MFC_TstFldOpCyc 0 "FALSE" 1 "TRUE" ;
VAL_ 1322 DTCI_MFC_TstFldLstClr 0 "FALSE" 1 "TRUE" ;
VAL_ 1322 DTCI_MFC_TstFld 0 "FALSE" 1 "TRUE" ;
VAL_ 1322 DTCI_MFC_PndngDTC 0 "FALSE" 1 "TRUE" ;
VAL_ 1322 DTCI_MFC_DTCTriggered 0 "FALSE" 1 "TRUE" ;
VAL_ 1322 DTCI_MFC_WrnIndTrggrd 0 "FALSE" 1 "TRUE" ;
VAL_ 1322 DTCI_MFC_WrnIndRqd 0 "FALSE" 1 "TRUE" ;
VAL_ 1137 DTCI_MRCM_L_CnfrmdDTC 0 "FALSE" 1 "TRUE" ;
VAL_ 1137 DTCI_MRCM_L_DTCFaultType 0 "Not Supported" 1 "Type A" 2 "Type B" 3 "Type C" ;
VAL_ 1137 DTCI_MRCM_L_TstNCmpltdOpCyc 0 "FALSE" 1 "TRUE" ;
VAL_ 1137 DTCI_MRCM_L_TstNCmpltdLstClr 0 "FALSE" 1 "TRUE" ;
VAL_ 1137 DTCI_MRCM_L_TstFldOpCyc 0 "FALSE" 1 "TRUE" ;
VAL_ 1137 DTCI_MRCM_L_TstFldLstClr 0 "FALSE" 1 "TRUE" ;
VAL_ 1137 DTCI_MRCM_L_TstFld 0 "FALSE" 1 "TRUE" ;
VAL_ 1137 DTCI_MRCM_L_PndngDTC 0 "FALSE" 1 "TRUE" ;
VAL_ 1137 DTCI_MRCM_L_DTCTriggered 0 "FALSE" 1 "TRUE" ;
VAL_ 1137 DTCI_MRCM_L_WrnIndTrggrd 0 "FALSE" 1 "TRUE" ;
VAL_ 1137 DTCI_MRCM_L_WrnIndRqd 0 "FALSE" 1 "TRUE" ;
VAL_ 1138 DTCI_MRCM_R_CnfrmdDTC 0 "FALSE" 1 "TRUE" ;
VAL_ 1138 DTCI_MRCM_R_DTCFaultType 0 "Not Supported" 1 "Type A" 2 "Type B" 3 "Type C" ;
VAL_ 1138 DTCI_MRCM_R_TstNCmpltdOpCyc 0 "FALSE" 1 "TRUE" ;
VAL_ 1138 DTCI_MRCM_R_TstNCmpltdLstClr 0 "FALSE" 1 "TRUE" ;
VAL_ 1138 DTCI_MRCM_R_TstFldOpCyc 0 "FALSE" 1 "TRUE" ;
VAL_ 1138 DTCI_MRCM_R_TstFldLstClr 0 "FALSE" 1 "TRUE" ;
VAL_ 1138 DTCI_MRCM_R_TstFld 0 "FALSE" 1 "TRUE" ;
VAL_ 1138 DTCI_MRCM_R_PndngDTC 0 "FALSE" 1 "TRUE" ;
VAL_ 1138 DTCI_MRCM_R_DTCTriggered 0 "FALSE" 1 "TRUE" ;
VAL_ 1138 DTCI_MRCM_R_WrnIndTrggrd 0 "FALSE" 1 "TRUE" ;
VAL_ 1138 DTCI_MRCM_R_WrnIndRqd 0 "FALSE" 1 "TRUE" ;
VAL_ 1139 DTCI_MSB1_CnfrmdDTC 0 "FALSE" 1 "TRUE" ;
VAL_ 1139 DTCI_MSB1_DTCFaultType 0 "Not Supported" 1 "Type A" 2 "Type B" 3 "Type C" ;
VAL_ 1139 DTCI_MSB1_TstNCmpltdOpCyc 0 "FALSE" 1 "TRUE" ;
VAL_ 1139 DTCI_MSB1_TstNCmpltdLstClr 0 "FALSE" 1 "TRUE" ;
VAL_ 1139 DTCI_MSB1_TstFldOpCyc 0 "FALSE" 1 "TRUE" ;
VAL_ 1139 DTCI_MSB1_TstFldLstClr 0 "FALSE" 1 "TRUE" ;
VAL_ 1139 DTCI_MSB1_TstFld 0 "FALSE" 1 "TRUE" ;
VAL_ 1139 DTCI_MSB1_PndngDTC 0 "FALSE" 1 "TRUE" ;
VAL_ 1139 DTCI_MSB1_DTCTriggered 0 "FALSE" 1 "TRUE" ;
VAL_ 1139 DTCI_MSB1_WrnIndTrggrd 0 "FALSE" 1 "TRUE" ;
VAL_ 1139 DTCI_MSB1_WrnIndRqd 0 "FALSE" 1 "TRUE" ;
VAL_ 1140 DTCI_MSB2_CnfrmdDTC 0 "FALSE" 1 "TRUE" ;
VAL_ 1140 DTCI_MSB2_DTCFaultType 0 "Not Supported" 1 "Type A" 2 "Type B" 3 "Type C" ;
VAL_ 1140 DTCI_MSB2_TstNCmpltdOpCyc 0 "FALSE" 1 "TRUE" ;
VAL_ 1140 DTCI_MSB2_TstNCmpltdLstClr 0 "FALSE" 1 "TRUE" ;
VAL_ 1140 DTCI_MSB2_TstFldOpCyc 0 "FALSE" 1 "TRUE" ;
VAL_ 1140 DTCI_MSB2_TstFldLstClr 0 "FALSE" 1 "TRUE" ;
VAL_ 1140 DTCI_MSB2_TstFld 0 "FALSE" 1 "TRUE" ;
VAL_ 1140 DTCI_MSB2_PndngDTC 0 "FALSE" 1 "TRUE" ;
VAL_ 1140 DTCI_MSB2_DTCTriggered 0 "FALSE" 1 "TRUE" ;
VAL_ 1140 DTCI_MSB2_WrnIndTrggrd 0 "FALSE" 1 "TRUE" ;
VAL_ 1140 DTCI_MSB2_WrnIndRqd 0 "FALSE" 1 "TRUE" ;
VAL_ 1141 DTCI_MSM_D_CnfrmdDTC 0 "FALSE" 1 "TRUE" ;
VAL_ 1141 DTCI_MSM_D_DTCFaultType 0 "Not Supported" 1 "Type A" 2 "Type B" 3 "Type C" ;
VAL_ 1141 DTCI_MSM_D_TstNCmpltdOpCyc 0 "FALSE" 1 "TRUE" ;
VAL_ 1141 DTCI_MSM_D_TstNCmpltdLstClr 0 "FALSE" 1 "TRUE" ;
VAL_ 1141 DTCI_MSM_D_TstFldOpCyc 0 "FALSE" 1 "TRUE" ;
VAL_ 1141 DTCI_MSM_D_TstFldLstClr 0 "FALSE" 1 "TRUE" ;
VAL_ 1141 DTCI_MSM_D_TstFld 0 "FALSE" 1 "TRUE" ;
VAL_ 1141 DTCI_MSM_D_PndngDTC 0 "FALSE" 1 "TRUE" ;
VAL_ 1141 DTCI_MSM_D_DTCTriggered 0 "FALSE" 1 "TRUE" ;
VAL_ 1141 DTCI_MSM_D_WrnIndTrggrd 0 "FALSE" 1 "TRUE" ;
VAL_ 1141 DTCI_MSM_D_WrnIndRqd 0 "FALSE" 1 "TRUE" ;
VAL_ 1142 DTCI_MSM_LR_CnfrmdDTC 0 "FALSE" 1 "TRUE" ;
VAL_ 1142 DTCI_MSM_LR_DTCFaultType 0 "Not Supported" 1 "Type A" 2 "Type B" 3 "Type C" ;
VAL_ 1142 DTCI_MSM_LR_TstNCmpltdOpCyc 0 "FALSE" 1 "TRUE" ;
VAL_ 1142 DTCI_MSM_LR_TstNCmpltdLstClr 0 "FALSE" 1 "TRUE" ;
VAL_ 1142 DTCI_MSM_LR_TstFldOpCyc 0 "FALSE" 1 "TRUE" ;
VAL_ 1142 DTCI_MSM_LR_TstFldLstClr 0 "FALSE" 1 "TRUE" ;
VAL_ 1142 DTCI_MSM_LR_TstFld 0 "FALSE" 1 "TRUE" ;
VAL_ 1142 DTCI_MSM_LR_PndngDTC 0 "FALSE" 1 "TRUE" ;
VAL_ 1142 DTCI_MSM_LR_DTCTriggered 0 "FALSE" 1 "TRUE" ;
VAL_ 1142 DTCI_MSM_LR_WrnIndTrggrd 0 "FALSE" 1 "TRUE" ;
VAL_ 1142 DTCI_MSM_LR_WrnIndRqd 0 "FALSE" 1 "TRUE" ;
VAL_ 1143 DTCI_MSM_P_CnfrmdDTC 0 "FALSE" 1 "TRUE" ;
VAL_ 1143 DTCI_MSM_P_DTCFaultType 0 "Not Supported" 1 "Type A" 2 "Type B" 3 "Type C" ;
VAL_ 1143 DTCI_MSM_P_TstNCmpltdOpCyc 0 "FALSE" 1 "TRUE" ;
VAL_ 1143 DTCI_MSM_P_TstNCmpltdLstClr 0 "FALSE" 1 "TRUE" ;
VAL_ 1143 DTCI_MSM_P_TstFldOpCyc 0 "FALSE" 1 "TRUE" ;
VAL_ 1143 DTCI_MSM_P_TstFldLstClr 0 "FALSE" 1 "TRUE" ;
VAL_ 1143 DTCI_MSM_P_TstFld 0 "FALSE" 1 "TRUE" ;
VAL_ 1143 DTCI_MSM_P_PndngDTC 0 "FALSE" 1 "TRUE" ;
VAL_ 1143 DTCI_MSM_P_DTCTriggered 0 "FALSE" 1 "TRUE" ;
VAL_ 1143 DTCI_MSM_P_WrnIndTrggrd 0 "FALSE" 1 "TRUE" ;
VAL_ 1143 DTCI_MSM_P_WrnIndRqd 0 "FALSE" 1 "TRUE" ;
VAL_ 1144 DTCI_MSM_RR_CnfrmdDTC 0 "FALSE" 1 "TRUE" ;
VAL_ 1144 DTCI_MSM_RR_DTCFaultType 0 "Not Supported" 1 "Type A" 2 "Type B" 3 "Type C" ;
VAL_ 1144 DTCI_MSM_RR_TstNCmpltdOpCyc 0 "FALSE" 1 "TRUE" ;
VAL_ 1144 DTCI_MSM_RR_TstNCmpltdLstClr 0 "FALSE" 1 "TRUE" ;
VAL_ 1144 DTCI_MSM_RR_TstFldOpCyc 0 "FALSE" 1 "TRUE" ;
VAL_ 1144 DTCI_MSM_RR_TstFldLstClr 0 "FALSE" 1 "TRUE" ;
VAL_ 1144 DTCI_MSM_RR_TstFld 0 "FALSE" 1 "TRUE" ;
VAL_ 1144 DTCI_MSM_RR_PndngDTC 0 "FALSE" 1 "TRUE" ;
VAL_ 1144 DTCI_MSM_RR_DTCTriggered 0 "FALSE" 1 "TRUE" ;
VAL_ 1144 DTCI_MSM_RR_WrnIndTrggrd 0 "FALSE" 1 "TRUE" ;
VAL_ 1144 DTCI_MSM_RR_WrnIndRqd 0 "FALSE" 1 "TRUE" ;
VAL_ 1145 DTCI_MTCM_L_CnfrmdDTC 0 "FALSE" 1 "TRUE" ;
VAL_ 1145 DTCI_MTCM_L_DTCFaultType 0 "Not Supported" 1 "Type A" 2 "Type B" 3 "Type C" ;
VAL_ 1145 DTCI_MTCM_L_TstNCmpltdOpCyc 0 "FALSE" 1 "TRUE" ;
VAL_ 1145 DTCI_MTCM_L_TstNCmpltdLstClr 0 "FALSE" 1 "TRUE" ;
VAL_ 1145 DTCI_MTCM_L_TstFldOpCyc 0 "FALSE" 1 "TRUE" ;
VAL_ 1145 DTCI_MTCM_L_TstFldLstClr 0 "FALSE" 1 "TRUE" ;
VAL_ 1145 DTCI_MTCM_L_TstFld 0 "FALSE" 1 "TRUE" ;
VAL_ 1145 DTCI_MTCM_L_PndngDTC 0 "FALSE" 1 "TRUE" ;
VAL_ 1145 DTCI_MTCM_L_DTCTriggered 0 "FALSE" 1 "TRUE" ;
VAL_ 1145 DTCI_MTCM_L_WrnIndTrggrd 0 "FALSE" 1 "TRUE" ;
VAL_ 1145 DTCI_MTCM_L_WrnIndRqd 0 "FALSE" 1 "TRUE" ;
VAL_ 1146 DTCI_MTCM_R_CnfrmdDTC 0 "FALSE" 1 "TRUE" ;
VAL_ 1146 DTCI_MTCM_R_DTCFaultType 0 "Not Supported" 1 "Type A" 2 "Type B" 3 "Type C" ;
VAL_ 1146 DTCI_MTCM_R_TstNCmpltdOpCyc 0 "FALSE" 1 "TRUE" ;
VAL_ 1146 DTCI_MTCM_R_TstNCmpltdLstClr 0 "FALSE" 1 "TRUE" ;
VAL_ 1146 DTCI_MTCM_R_TstFldOpCyc 0 "FALSE" 1 "TRUE" ;
VAL_ 1146 DTCI_MTCM_R_TstFldLstClr 0 "FALSE" 1 "TRUE" ;
VAL_ 1146 DTCI_MTCM_R_TstFld 0 "FALSE" 1 "TRUE" ;
VAL_ 1146 DTCI_MTCM_R_PndngDTC 0 "FALSE" 1 "TRUE" ;
VAL_ 1146 DTCI_MTCM_R_DTCTriggered 0 "FALSE" 1 "TRUE" ;
VAL_ 1146 DTCI_MTCM_R_WrnIndTrggrd 0 "FALSE" 1 "TRUE" ;
VAL_ 1146 DTCI_MTCM_R_WrnIndRqd 0 "FALSE" 1 "TRUE" ;
VAL_ 1147 DTCI_NVM_CnfrmdDTC 0 "FALSE" 1 "TRUE" ;
VAL_ 1147 DTCI_NVM_DTCFaultType 0 "Not Supported" 1 "Type A" 2 "Type B" 3 "Type C" ;
VAL_ 1147 DTCI_NVM_TstNCmpltdOpCyc 0 "FALSE" 1 "TRUE" ;
VAL_ 1147 DTCI_NVM_TstNCmpltdLstClr 0 "FALSE" 1 "TRUE" ;
VAL_ 1147 DTCI_NVM_TstFldOpCyc 0 "FALSE" 1 "TRUE" ;
VAL_ 1147 DTCI_NVM_TstFldLstClr 0 "FALSE" 1 "TRUE" ;
VAL_ 1147 DTCI_NVM_TstFld 0 "FALSE" 1 "TRUE" ;
VAL_ 1147 DTCI_NVM_PndngDTC 0 "FALSE" 1 "TRUE" ;
VAL_ 1147 DTCI_NVM_DTCTriggered 0 "FALSE" 1 "TRUE" ;
VAL_ 1147 DTCI_NVM_WrnIndTrggrd 0 "FALSE" 1 "TRUE" ;
VAL_ 1147 DTCI_NVM_WrnIndRqd 0 "FALSE" 1 "TRUE" ;
VAL_ 1148 DTCI_PA_CnfrmdDTC 0 "FALSE" 1 "TRUE" ;
VAL_ 1148 DTCI_PA_DTCFaultType 0 "Not Supported" 1 "Type A" 2 "Type B" 3 "Type C" ;
VAL_ 1148 DTCI_PA_TstNCmpltdOpCyc 0 "FALSE" 1 "TRUE" ;
VAL_ 1148 DTCI_PA_TstNCmpltdLstClr 0 "FALSE" 1 "TRUE" ;
VAL_ 1148 DTCI_PA_TstFldOpCyc 0 "FALSE" 1 "TRUE" ;
VAL_ 1148 DTCI_PA_TstFldLstClr 0 "FALSE" 1 "TRUE" ;
VAL_ 1148 DTCI_PA_TstFld 0 "FALSE" 1 "TRUE" ;
VAL_ 1148 DTCI_PA_PndngDTC 0 "FALSE" 1 "TRUE" ;
VAL_ 1148 DTCI_PA_DTCTriggered 0 "FALSE" 1 "TRUE" ;
VAL_ 1148 DTCI_PA_WrnIndTrggrd 0 "FALSE" 1 "TRUE" ;
VAL_ 1148 DTCI_PA_WrnIndRqd 0 "FALSE" 1 "TRUE" ;
VAL_ 1323 DTCI_PDR_CnfrmdDTC 0 "FALSE" 1 "TRUE" ;
VAL_ 1323 DTCI_PDR_DTCFaultType 0 "Not Supported" 1 "Type A" 2 "Type B" 3 "Type C" ;
VAL_ 1323 DTCI_PDR_TstNCmpltdOpCyc 0 "FALSE" 1 "TRUE" ;
VAL_ 1323 DTCI_PDR_TstNCmpltdLstClr 0 "FALSE" 1 "TRUE" ;
VAL_ 1323 DTCI_PDR_TstFldOpCyc 0 "FALSE" 1 "TRUE" ;
VAL_ 1323 DTCI_PDR_TstFldLstClr 0 "FALSE" 1 "TRUE" ;
VAL_ 1323 DTCI_PDR_TstFld 0 "FALSE" 1 "TRUE" ;
VAL_ 1323 DTCI_PDR_PndngDTC 0 "FALSE" 1 "TRUE" ;
VAL_ 1323 DTCI_PDR_DTCTriggered 0 "FALSE" 1 "TRUE" ;
VAL_ 1323 DTCI_PDR_WrnIndTrggrd 0 "FALSE" 1 "TRUE" ;
VAL_ 1323 DTCI_PDR_WrnIndRqd 0 "FALSE" 1 "TRUE" ;
VAL_ 1149 DTCI_PTM_CnfrmdDTC 0 "FALSE" 1 "TRUE" ;
VAL_ 1149 DTCI_PTM_DTCFaultType 0 "Not Supported" 1 "Type A" 2 "Type B" 3 "Type C" ;
VAL_ 1149 DTCI_PTM_TstNCmpltdOpCyc 0 "FALSE" 1 "TRUE" ;
VAL_ 1149 DTCI_PTM_TstNCmpltdLstClr 0 "FALSE" 1 "TRUE" ;
VAL_ 1149 DTCI_PTM_TstFldOpCyc 0 "FALSE" 1 "TRUE" ;
VAL_ 1149 DTCI_PTM_TstFldLstClr 0 "FALSE" 1 "TRUE" ;
VAL_ 1149 DTCI_PTM_TstFld 0 "FALSE" 1 "TRUE" ;
VAL_ 1149 DTCI_PTM_PndngDTC 0 "FALSE" 1 "TRUE" ;
VAL_ 1149 DTCI_PTM_DTCTriggered 0 "FALSE" 1 "TRUE" ;
VAL_ 1149 DTCI_PTM_WrnIndTrggrd 0 "FALSE" 1 "TRUE" ;
VAL_ 1149 DTCI_PTM_WrnIndRqd 0 "FALSE" 1 "TRUE" ;
VAL_ 1150 DTCI_RDCM_CnfrmdDTC 0 "FALSE" 1 "TRUE" ;
VAL_ 1150 DTCI_RDCM_DTCFaultType 0 "Not Supported" 1 "Type A" 2 "Type B" 3 "Type C" ;
VAL_ 1150 DTCI_RDCM_TstNCmpltdOpCyc 0 "FALSE" 1 "TRUE" ;
VAL_ 1150 DTCI_RDCM_TstNCmpltdLstClr 0 "FALSE" 1 "TRUE" ;
VAL_ 1150 DTCI_RDCM_TstFldOpCyc 0 "FALSE" 1 "TRUE" ;
VAL_ 1150 DTCI_RDCM_TstFldLstClr 0 "FALSE" 1 "TRUE" ;
VAL_ 1150 DTCI_RDCM_TstFld 0 "FALSE" 1 "TRUE" ;
VAL_ 1150 DTCI_RDCM_PndngDTC 0 "FALSE" 1 "TRUE" ;
VAL_ 1150 DTCI_RDCM_DTCTriggered 0 "FALSE" 1 "TRUE" ;
VAL_ 1150 DTCI_RDCM_WrnIndTrggrd 0 "FALSE" 1 "TRUE" ;
VAL_ 1150 DTCI_RDCM_WrnIndRqd 0 "FALSE" 1 "TRUE" ;
VAL_ 1326 DTCI_RSC_CnfrmdDTC 0 "FALSE" 1 "TRUE" ;
VAL_ 1326 DTCI_RSC_DTCFaultType 0 "Not Supported" 1 "Type A" 2 "Type B" 3 "Type C" ;
VAL_ 1326 DTCI_RSC_TstNCmpltdOpCyc 0 "FALSE" 1 "TRUE" ;
VAL_ 1326 DTCI_RSC_TstNCmpltdLstClr 0 "FALSE" 1 "TRUE" ;
VAL_ 1326 DTCI_RSC_TstFldOpCyc 0 "FALSE" 1 "TRUE" ;
VAL_ 1326 DTCI_RSC_TstFldLstClr 0 "FALSE" 1 "TRUE" ;
VAL_ 1326 DTCI_RSC_TstFld 0 "FALSE" 1 "TRUE" ;
VAL_ 1326 DTCI_RSC_PndngDTC 0 "FALSE" 1 "TRUE" ;
VAL_ 1326 DTCI_RSC_DTCTriggered 0 "FALSE" 1 "TRUE" ;
VAL_ 1326 DTCI_RSC_WrnIndTrggrd 0 "FALSE" 1 "TRUE" ;
VAL_ 1326 DTCI_RSC_WrnIndRqd 0 "FALSE" 1 "TRUE" ;
VAL_ 1330 DTCI_RadioLow_CnfrmdDTC 0 "FALSE" 1 "TRUE" ;
VAL_ 1330 DTCI_RadioLow_DTCFaultType 0 "Not Supported" 1 "Type A" 2 "Type B" 3 "Type C" ;
VAL_ 1330 DTCI_RadioLow_TstNCmpltdOpCyc 0 "FALSE" 1 "TRUE" ;
VAL_ 1330 DTCI_RadioLow_TstNCmpltdLstClr 0 "FALSE" 1 "TRUE" ;
VAL_ 1330 DTCI_RadioLow_TstFldOpCyc 0 "FALSE" 1 "TRUE" ;
VAL_ 1330 DTCI_RadioLow_TstFldLstClr 0 "FALSE" 1 "TRUE" ;
VAL_ 1330 DTCI_RadioLow_TstFld 0 "FALSE" 1 "TRUE" ;
VAL_ 1330 DTCI_RadioLow_PndngDTC 0 "FALSE" 1 "TRUE" ;
VAL_ 1330 DTCI_RadioLow_DTCTriggered 0 "FALSE" 1 "TRUE" ;
VAL_ 1330 DTCI_RadioLow_WrnIndTrggrd 0 "FALSE" 1 "TRUE" ;
VAL_ 1330 DTCI_RadioLow_WrnIndRqd 0 "FALSE" 1 "TRUE" ;
VAL_ 1151 DTCI_SADS_CnfrmdDTC 0 "FALSE" 1 "TRUE" ;
VAL_ 1151 DTCI_SADS_DTCFaultType 0 "Not Supported" 1 "Type A" 2 "Type B" 3 "Type C" ;
VAL_ 1151 DTCI_SADS_TstNCmpltdOpCyc 0 "FALSE" 1 "TRUE" ;
VAL_ 1151 DTCI_SADS_TstNCmpltdLstClr 0 "FALSE" 1 "TRUE" ;
VAL_ 1151 DTCI_SADS_TstFldOpCyc 0 "FALSE" 1 "TRUE" ;
VAL_ 1151 DTCI_SADS_TstFldLstClr 0 "FALSE" 1 "TRUE" ;
VAL_ 1151 DTCI_SADS_TstFld 0 "FALSE" 1 "TRUE" ;
VAL_ 1151 DTCI_SADS_PndngDTC 0 "FALSE" 1 "TRUE" ;
VAL_ 1151 DTCI_SADS_DTCTriggered 0 "FALSE" 1 "TRUE" ;
VAL_ 1151 DTCI_SADS_WrnIndTrggrd 0 "FALSE" 1 "TRUE" ;
VAL_ 1151 DTCI_SADS_WrnIndRqd 0 "FALSE" 1 "TRUE" ;
VAL_ 1416 DTCI_SBM_CnfrmdDTC 0 "FALSE" 1 "TRUE" ;
VAL_ 1416 DTCI_SBM_DTCFaultType 0 "Not Supported" 1 "Type A" 2 "Type B" 3 "Type C" ;
VAL_ 1416 DTCI_SBM_TstNCmpltdOpCyc 0 "FALSE" 1 "TRUE" ;
VAL_ 1416 DTCI_SBM_TstNCmpltdLstClr 0 "FALSE" 1 "TRUE" ;
VAL_ 1416 DTCI_SBM_TstFldOpCyc 0 "FALSE" 1 "TRUE" ;
VAL_ 1416 DTCI_SBM_TstFldLstClr 0 "FALSE" 1 "TRUE" ;
VAL_ 1416 DTCI_SBM_TstFld 0 "FALSE" 1 "TRUE" ;
VAL_ 1416 DTCI_SBM_PndngDTC 0 "FALSE" 1 "TRUE" ;
VAL_ 1416 DTCI_SBM_DTCTriggered 0 "FALSE" 1 "TRUE" ;
VAL_ 1416 DTCI_SBM_WrnIndTrggrd 0 "FALSE" 1 "TRUE" ;
VAL_ 1416 DTCI_SBM_WrnIndRqd 0 "FALSE" 1 "TRUE" ;
VAL_ 1348 DTCI_SBZA_L_CnfrmdDTC 0 "FALSE" 1 "TRUE" ;
VAL_ 1348 DTCI_SBZA_L_DTCFaultType 0 "Not Supported" 1 "Type A" 2 "Type B" 3 "Type C" ;
VAL_ 1348 DTCI_SBZA_L_TstNCmpltdOpCyc 0 "FALSE" 1 "TRUE" ;
VAL_ 1348 DTCI_SBZA_L_TstNCmpltdLstClr 0 "FALSE" 1 "TRUE" ;
VAL_ 1348 DTCI_SBZA_L_TstFldOpCyc 0 "FALSE" 1 "TRUE" ;
VAL_ 1348 DTCI_SBZA_L_TstFldLstClr 0 "FALSE" 1 "TRUE" ;
VAL_ 1348 DTCI_SBZA_L_TstFld 0 "FALSE" 1 "TRUE" ;
VAL_ 1348 DTCI_SBZA_L_PndngDTC 0 "FALSE" 1 "TRUE" ;
VAL_ 1348 DTCI_SBZA_L_DTCTriggered 0 "FALSE" 1 "TRUE" ;
VAL_ 1348 DTCI_SBZA_L_WrnIndTrggrd 0 "FALSE" 1 "TRUE" ;
VAL_ 1348 DTCI_SBZA_L_WrnIndRqd 0 "FALSE" 1 "TRUE" ;
VAL_ 1153 DTCI_SBZA_R_CnfrmdDTC 0 "FALSE" 1 "TRUE" ;
VAL_ 1153 DTCI_SBZA_R_DTCFaultType 0 "Not Supported" 1 "Type A" 2 "Type B" 3 "Type C" ;
VAL_ 1153 DTCI_SBZA_R_TstNCmpltdOpCyc 0 "FALSE" 1 "TRUE" ;
VAL_ 1153 DTCI_SBZA_R_TstNCmpltdLstClr 0 "FALSE" 1 "TRUE" ;
VAL_ 1153 DTCI_SBZA_R_TstFldOpCyc 0 "FALSE" 1 "TRUE" ;
VAL_ 1153 DTCI_SBZA_R_TstFldLstClr 0 "FALSE" 1 "TRUE" ;
VAL_ 1153 DTCI_SBZA_R_TstFld 0 "FALSE" 1 "TRUE" ;
VAL_ 1153 DTCI_SBZA_R_PndngDTC 0 "FALSE" 1 "TRUE" ;
VAL_ 1153 DTCI_SBZA_R_DTCTriggered 0 "FALSE" 1 "TRUE" ;
VAL_ 1153 DTCI_SBZA_R_WrnIndTrggrd 0 "FALSE" 1 "TRUE" ;
VAL_ 1153 DTCI_SBZA_R_WrnIndRqd 0 "FALSE" 1 "TRUE" ;
VAL_ 1154 DTCI_SCL_CnfrmdDTC 0 "FALSE" 1 "TRUE" ;
VAL_ 1154 DTCI_SCL_DTCFaultType 0 "Not Supported" 1 "Type A" 2 "Type B" 3 "Type C" ;
VAL_ 1154 DTCI_SCL_TstNCmpltdOpCyc 0 "FALSE" 1 "TRUE" ;
VAL_ 1154 DTCI_SCL_TstNCmpltdLstClr 0 "FALSE" 1 "TRUE" ;
VAL_ 1154 DTCI_SCL_TstFldOpCyc 0 "FALSE" 1 "TRUE" ;
VAL_ 1154 DTCI_SCL_TstFldLstClr 0 "FALSE" 1 "TRUE" ;
VAL_ 1154 DTCI_SCL_TstFld 0 "FALSE" 1 "TRUE" ;
VAL_ 1154 DTCI_SCL_PndngDTC 0 "FALSE" 1 "TRUE" ;
VAL_ 1154 DTCI_SCL_DTCTriggered 0 "FALSE" 1 "TRUE" ;
VAL_ 1154 DTCI_SCL_WrnIndTrggrd 0 "FALSE" 1 "TRUE" ;
VAL_ 1154 DTCI_SCL_WrnIndRqd 0 "FALSE" 1 "TRUE" ;
VAL_ 1155 DTCI_SDM_CnfrmdDTC 0 "FALSE" 1 "TRUE" ;
VAL_ 1155 DTCI_SDM_DTCFaultType 0 "Not Supported" 1 "Type A" 2 "Type B" 3 "Type C" ;
VAL_ 1155 DTCI_SDM_TstNCmpltdOpCyc 0 "FALSE" 1 "TRUE" ;
VAL_ 1155 DTCI_SDM_TstNCmpltdLstClr 0 "FALSE" 1 "TRUE" ;
VAL_ 1155 DTCI_SDM_TstFldOpCyc 0 "FALSE" 1 "TRUE" ;
VAL_ 1155 DTCI_SDM_TstFldLstClr 0 "FALSE" 1 "TRUE" ;
VAL_ 1155 DTCI_SDM_TstFld 0 "FALSE" 1 "TRUE" ;
VAL_ 1155 DTCI_SDM_PndngDTC 0 "FALSE" 1 "TRUE" ;
VAL_ 1155 DTCI_SDM_DTCTriggered 0 "FALSE" 1 "TRUE" ;
VAL_ 1155 DTCI_SDM_WrnIndTrggrd 0 "FALSE" 1 "TRUE" ;
VAL_ 1155 DTCI_SDM_WrnIndRqd 0 "FALSE" 1 "TRUE" ;
VAL_ 1156 DTCI_SIB_CnfrmdDTC 0 "FALSE" 1 "TRUE" ;
VAL_ 1156 DTCI_SIB_DTCFaultType 0 "Not Supported" 1 "Type A" 2 "Type B" 3 "Type C" ;
VAL_ 1156 DTCI_SIB_TstNCmpltdOpCyc 0 "FALSE" 1 "TRUE" ;
VAL_ 1156 DTCI_SIB_TstNCmpltdLstClr 0 "FALSE" 1 "TRUE" ;
VAL_ 1156 DTCI_SIB_TstFldOpCyc 0 "FALSE" 1 "TRUE" ;
VAL_ 1156 DTCI_SIB_TstFldLstClr 0 "FALSE" 1 "TRUE" ;
VAL_ 1156 DTCI_SIB_TstFld 0 "FALSE" 1 "TRUE" ;
VAL_ 1156 DTCI_SIB_PndngDTC 0 "FALSE" 1 "TRUE" ;
VAL_ 1156 DTCI_SIB_DTCTriggered 0 "FALSE" 1 "TRUE" ;
VAL_ 1156 DTCI_SIB_WrnIndTrggrd 0 "FALSE" 1 "TRUE" ;
VAL_ 1156 DTCI_SIB_WrnIndRqd 0 "FALSE" 1 "TRUE" ;
VAL_ 1157 DTCI_SRR_LF_CnfrmdDTC 0 "FALSE" 1 "TRUE" ;
VAL_ 1157 DTCI_SRR_LF_DTCFaultType 0 "Not Supported" 1 "Type A" 2 "Type B" 3 "Type C" ;
VAL_ 1157 DTCI_SRR_LF_TstNCmpltdOpCyc 0 "FALSE" 1 "TRUE" ;
VAL_ 1157 DTCI_SRR_LF_TstNCmpltdLstClr 0 "FALSE" 1 "TRUE" ;
VAL_ 1157 DTCI_SRR_LF_TstFldOpCyc 0 "FALSE" 1 "TRUE" ;
VAL_ 1157 DTCI_SRR_LF_TstFldLstClr 0 "FALSE" 1 "TRUE" ;
VAL_ 1157 DTCI_SRR_LF_TstFld 0 "FALSE" 1 "TRUE" ;
VAL_ 1157 DTCI_SRR_LF_PndngDTC 0 "FALSE" 1 "TRUE" ;
VAL_ 1157 DTCI_SRR_LF_DTCTriggered 0 "FALSE" 1 "TRUE" ;
VAL_ 1157 DTCI_SRR_LF_WrnIndTrggrd 0 "FALSE" 1 "TRUE" ;
VAL_ 1157 DTCI_SRR_LF_WrnIndRqd 0 "FALSE" 1 "TRUE" ;
VAL_ 1158 DTCI_SRR_LR_CR_CnfrmdDTC 0 "FALSE" 1 "TRUE" ;
VAL_ 1158 DTCI_SRR_LR_CR_DTCFaultType 0 "Not Supported" 1 "Type A" 2 "Type B" 3 "Type C" ;
VAL_ 1158 DTCI_SRR_LR_CR_TstNCmpltdOpCyc 0 "FALSE" 1 "TRUE" ;
VAL_ 1158 DTCI_SRR_LR_CR_TstNCmpltdLstClr 0 "FALSE" 1 "TRUE" ;
VAL_ 1158 DTCI_SRR_LR_CR_TstFldOpCyc 0 "FALSE" 1 "TRUE" ;
VAL_ 1158 DTCI_SRR_LR_CR_TstFldLstClr 0 "FALSE" 1 "TRUE" ;
VAL_ 1158 DTCI_SRR_LR_CR_TstFld 0 "FALSE" 1 "TRUE" ;
VAL_ 1158 DTCI_SRR_LR_CR_PndngDTC 0 "FALSE" 1 "TRUE" ;
VAL_ 1158 DTCI_SRR_LR_CR_DTCTriggered 0 "FALSE" 1 "TRUE" ;
VAL_ 1158 DTCI_SRR_LR_CR_WrnIndTrggrd 0 "FALSE" 1 "TRUE" ;
VAL_ 1158 DTCI_SRR_LR_CR_WrnIndRqd 0 "FALSE" 1 "TRUE" ;
VAL_ 1159 DTCI_SRR_RF_CnfrmdDTC 0 "FALSE" 1 "TRUE" ;
VAL_ 1159 DTCI_SRR_RF_DTCFaultType 0 "Not Supported" 1 "Type A" 2 "Type B" 3 "Type C" ;
VAL_ 1159 DTCI_SRR_RF_TstNCmpltdOpCyc 0 "FALSE" 1 "TRUE" ;
VAL_ 1159 DTCI_SRR_RF_TstNCmpltdLstClr 0 "FALSE" 1 "TRUE" ;
VAL_ 1159 DTCI_SRR_RF_TstFldOpCyc 0 "FALSE" 1 "TRUE" ;
VAL_ 1159 DTCI_SRR_RF_TstFldLstClr 0 "FALSE" 1 "TRUE" ;
VAL_ 1159 DTCI_SRR_RF_TstFld 0 "FALSE" 1 "TRUE" ;
VAL_ 1159 DTCI_SRR_RF_PndngDTC 0 "FALSE" 1 "TRUE" ;
VAL_ 1159 DTCI_SRR_RF_DTCTriggered 0 "FALSE" 1 "TRUE" ;
VAL_ 1159 DTCI_SRR_RF_WrnIndTrggrd 0 "FALSE" 1 "TRUE" ;
VAL_ 1159 DTCI_SRR_RF_WrnIndRqd 0 "FALSE" 1 "TRUE" ;
VAL_ 1160 DTCI_SRR_RR_CnfrmdDTC 0 "FALSE" 1 "TRUE" ;
VAL_ 1160 DTCI_SRR_RR_DTCFaultType 0 "Not Supported" 1 "Type A" 2 "Type B" 3 "Type C" ;
VAL_ 1160 DTCI_SRR_RR_TstNCmpltdOpCyc 0 "FALSE" 1 "TRUE" ;
VAL_ 1160 DTCI_SRR_RR_TstNCmpltdLstClr 0 "FALSE" 1 "TRUE" ;
VAL_ 1160 DTCI_SRR_RR_TstFldOpCyc 0 "FALSE" 1 "TRUE" ;
VAL_ 1160 DTCI_SRR_RR_TstFldLstClr 0 "FALSE" 1 "TRUE" ;
VAL_ 1160 DTCI_SRR_RR_TstFld 0 "FALSE" 1 "TRUE" ;
VAL_ 1160 DTCI_SRR_RR_PndngDTC 0 "FALSE" 1 "TRUE" ;
VAL_ 1160 DTCI_SRR_RR_DTCTriggered 0 "FALSE" 1 "TRUE" ;
VAL_ 1160 DTCI_SRR_RR_WrnIndTrggrd 0 "FALSE" 1 "TRUE" ;
VAL_ 1160 DTCI_SRR_RR_WrnIndRqd 0 "FALSE" 1 "TRUE" ;
VAL_ 1407 DTCI_SRR_SLR_CnfrmdDTC 0 "FALSE" 1 "TRUE" ;
VAL_ 1407 DTCI_SRR_SLR_DTCFaultType 0 "Not Supported" 1 "Type A" 2 "Type B" 3 "Type C" ;
VAL_ 1407 DTCI_SRR_SLR_TstNCmpltdOpCyc 0 "FALSE" 1 "TRUE" ;
VAL_ 1407 DTCI_SRR_SLR_TstNCmpltdLstClr 0 "FALSE" 1 "TRUE" ;
VAL_ 1407 DTCI_SRR_SLR_TstFldOpCyc 0 "FALSE" 1 "TRUE" ;
VAL_ 1407 DTCI_SRR_SLR_TstFldLstClr 0 "FALSE" 1 "TRUE" ;
VAL_ 1407 DTCI_SRR_SLR_TstFld 0 "FALSE" 1 "TRUE" ;
VAL_ 1407 DTCI_SRR_SLR_PndngDTC 0 "FALSE" 1 "TRUE" ;
VAL_ 1407 DTCI_SRR_SLR_DTCTriggered 0 "FALSE" 1 "TRUE" ;
VAL_ 1407 DTCI_SRR_SLR_WrnIndTrggrd 0 "FALSE" 1 "TRUE" ;
VAL_ 1407 DTCI_SRR_SLR_WrnIndRqd 0 "FALSE" 1 "TRUE" ;
VAL_ 1408 DTCI_SRR_SRR_CnfrmdDTC 0 "FALSE" 1 "TRUE" ;
VAL_ 1408 DTCI_SRR_SRR_DTCFaultType 0 "Not Supported" 1 "Type A" 2 "Type B" 3 "Type C" ;
VAL_ 1408 DTCI_SRR_SRR_TstNCmpltdOpCyc 0 "FALSE" 1 "TRUE" ;
VAL_ 1408 DTCI_SRR_SRR_TstNCmpltdLstClr 0 "FALSE" 1 "TRUE" ;
VAL_ 1408 DTCI_SRR_SRR_TstFldOpCyc 0 "FALSE" 1 "TRUE" ;
VAL_ 1408 DTCI_SRR_SRR_TstFldLstClr 0 "FALSE" 1 "TRUE" ;
VAL_ 1408 DTCI_SRR_SRR_TstFld 0 "FALSE" 1 "TRUE" ;
VAL_ 1408 DTCI_SRR_SRR_PndngDTC 0 "FALSE" 1 "TRUE" ;
VAL_ 1408 DTCI_SRR_SRR_DTCTriggered 0 "FALSE" 1 "TRUE" ;
VAL_ 1408 DTCI_SRR_SRR_WrnIndTrggrd 0 "FALSE" 1 "TRUE" ;
VAL_ 1408 DTCI_SRR_SRR_WrnIndRqd 0 "FALSE" 1 "TRUE" ;
VAL_ 1161 DTCI_STC_CnfrmdDTC 0 "FALSE" 1 "TRUE" ;
VAL_ 1161 DTCI_STC_DTCFaultType 0 "Not Supported" 1 "Type A" 2 "Type B" 3 "Type C" ;
VAL_ 1161 DTCI_STC_TstNCmpltdOpCyc 0 "FALSE" 1 "TRUE" ;
VAL_ 1161 DTCI_STC_TstNCmpltdLstClr 0 "FALSE" 1 "TRUE" ;
VAL_ 1161 DTCI_STC_TstFldOpCyc 0 "FALSE" 1 "TRUE" ;
VAL_ 1161 DTCI_STC_TstFldLstClr 0 "FALSE" 1 "TRUE" ;
VAL_ 1161 DTCI_STC_TstFld 0 "FALSE" 1 "TRUE" ;
VAL_ 1161 DTCI_STC_PndngDTC 0 "FALSE" 1 "TRUE" ;
VAL_ 1161 DTCI_STC_DTCTriggered 0 "FALSE" 1 "TRUE" ;
VAL_ 1161 DTCI_STC_WrnIndTrggrd 0 "FALSE" 1 "TRUE" ;
VAL_ 1161 DTCI_STC_WrnIndRqd 0 "FALSE" 1 "TRUE" ;
VAL_ 1164 DTCI_TCCM3_CnfrmdDTC 0 "FALSE" 1 "TRUE" ;
VAL_ 1164 DTCI_TCCM3_DTCFaultType 0 "Not Supported" 1 "Type A" 2 "Type B" 3 "Type C" ;
VAL_ 1164 DTCI_TCCM3_TstNCmpltdOpCyc 0 "FALSE" 1 "TRUE" ;
VAL_ 1164 DTCI_TCCM3_TstNCmpltdLstClr 0 "FALSE" 1 "TRUE" ;
VAL_ 1164 DTCI_TCCM3_TstFldOpCyc 0 "FALSE" 1 "TRUE" ;
VAL_ 1164 DTCI_TCCM3_TstFldLstClr 0 "FALSE" 1 "TRUE" ;
VAL_ 1164 DTCI_TCCM3_TstFld 0 "FALSE" 1 "TRUE" ;
VAL_ 1164 DTCI_TCCM3_PndngDTC 0 "FALSE" 1 "TRUE" ;
VAL_ 1164 DTCI_TCCM3_DTCTriggered 0 "FALSE" 1 "TRUE" ;
VAL_ 1164 DTCI_TCCM3_WrnIndTrggrd 0 "FALSE" 1 "TRUE" ;
VAL_ 1164 DTCI_TCCM3_WrnIndRqd 0 "FALSE" 1 "TRUE" ;
VAL_ 1163 DTCI_TCCM_CnfrmdDTC 0 "FALSE" 1 "TRUE" ;
VAL_ 1163 DTCI_TCCM_DTCFaultType 0 "Not Supported" 1 "Type A" 2 "Type B" 3 "Type C" ;
VAL_ 1163 DTCI_TCCM_TstNCmpltdOpCyc 0 "FALSE" 1 "TRUE" ;
VAL_ 1163 DTCI_TCCM_TstNCmpltdLstClr 0 "FALSE" 1 "TRUE" ;
VAL_ 1163 DTCI_TCCM_TstFldOpCyc 0 "FALSE" 1 "TRUE" ;
VAL_ 1163 DTCI_TCCM_TstFldLstClr 0 "FALSE" 1 "TRUE" ;
VAL_ 1163 DTCI_TCCM_TstFld 0 "FALSE" 1 "TRUE" ;
VAL_ 1163 DTCI_TCCM_PndngDTC 0 "FALSE" 1 "TRUE" ;
VAL_ 1163 DTCI_TCCM_DTCTriggered 0 "FALSE" 1 "TRUE" ;
VAL_ 1163 DTCI_TCCM_WrnIndTrggrd 0 "FALSE" 1 "TRUE" ;
VAL_ 1163 DTCI_TCCM_WrnIndRqd 0 "FALSE" 1 "TRUE" ;
VAL_ 1165 DTCI_TCM_CnfrmdDTC 0 "FALSE" 1 "TRUE" ;
VAL_ 1165 DTCI_TCM_DTCFaultType 0 "Not Supported" 1 "Type A" 2 "Type B" 3 "Type C" ;
VAL_ 1165 DTCI_TCM_TstNCmpltdOpCyc 0 "FALSE" 1 "TRUE" ;
VAL_ 1165 DTCI_TCM_TstNCmpltdLstClr 0 "FALSE" 1 "TRUE" ;
VAL_ 1165 DTCI_TCM_TstFldOpCyc 0 "FALSE" 1 "TRUE" ;
VAL_ 1165 DTCI_TCM_TstFldLstClr 0 "FALSE" 1 "TRUE" ;
VAL_ 1165 DTCI_TCM_TstFld 0 "FALSE" 1 "TRUE" ;
VAL_ 1165 DTCI_TCM_PndngDTC 0 "FALSE" 1 "TRUE" ;
VAL_ 1165 DTCI_TCM_DTCTriggered 0 "FALSE" 1 "TRUE" ;
VAL_ 1165 DTCI_TCM_WrnIndTrggrd 0 "FALSE" 1 "TRUE" ;
VAL_ 1165 DTCI_TCM_WrnIndRqd 0 "FALSE" 1 "TRUE" ;
VAL_ 1331 DTCI_TCP_CnfrmdDTC 0 "FALSE" 1 "TRUE" ;
VAL_ 1331 DTCI_TCP_DTCFaultType 0 "Not Supported" 1 "Type A" 2 "Type B" 3 "Type C" ;
VAL_ 1331 DTCI_TCP_TstNCmpltdOpCyc 0 "FALSE" 1 "TRUE" ;
VAL_ 1331 DTCI_TCP_TstNCmpltdLstClr 0 "FALSE" 1 "TRUE" ;
VAL_ 1331 DTCI_TCP_TstFldOpCyc 0 "FALSE" 1 "TRUE" ;
VAL_ 1331 DTCI_TCP_TstFldLstClr 0 "FALSE" 1 "TRUE" ;
VAL_ 1331 DTCI_TCP_TstFld 0 "FALSE" 1 "TRUE" ;
VAL_ 1331 DTCI_TCP_PndngDTC 0 "FALSE" 1 "TRUE" ;
VAL_ 1331 DTCI_TCP_DTCTriggered 0 "FALSE" 1 "TRUE" ;
VAL_ 1331 DTCI_TCP_WrnIndTrggrd 0 "FALSE" 1 "TRUE" ;
VAL_ 1331 DTCI_TCP_WrnIndRqd 0 "FALSE" 1 "TRUE" ;
VAL_ 1166 DTCI_TIM_CnfrmdDTC 0 "FALSE" 1 "TRUE" ;
VAL_ 1166 DTCI_TIM_DTCFaultType 0 "Not Supported" 1 "Type A" 2 "Type B" 3 "Type C" ;
VAL_ 1166 DTCI_TIM_TstNCmpltdOpCyc 0 "FALSE" 1 "TRUE" ;
VAL_ 1166 DTCI_TIM_TstNCmpltdLstClr 0 "FALSE" 1 "TRUE" ;
VAL_ 1166 DTCI_TIM_TstFldOpCyc 0 "FALSE" 1 "TRUE" ;
VAL_ 1166 DTCI_TIM_TstFldLstClr 0 "FALSE" 1 "TRUE" ;
VAL_ 1166 DTCI_TIM_TstFld 0 "FALSE" 1 "TRUE" ;
VAL_ 1166 DTCI_TIM_PndngDTC 0 "FALSE" 1 "TRUE" ;
VAL_ 1166 DTCI_TIM_DTCTriggered 0 "FALSE" 1 "TRUE" ;
VAL_ 1166 DTCI_TIM_WrnIndTrggrd 0 "FALSE" 1 "TRUE" ;
VAL_ 1166 DTCI_TIM_WrnIndRqd 0 "FALSE" 1 "TRUE" ;
VAL_ 1437 DTCI_UVM_CnfrmdDTC 0 "FALSE" 1 "TRUE" ;
VAL_ 1437 DTCI_UVM_DTCFaultType 0 "Not Supported" 1 "Type A" 2 "Type B" 3 "Type C" ;
VAL_ 1437 DTCI_UVM_TstNCmpltdOpCyc 0 "FALSE" 1 "TRUE" ;
VAL_ 1437 DTCI_UVM_TstNCmpltdLstClr 0 "FALSE" 1 "TRUE" ;
VAL_ 1437 DTCI_UVM_TstFldOpCyc 0 "FALSE" 1 "TRUE" ;
VAL_ 1437 DTCI_UVM_TstFldLstClr 0 "FALSE" 1 "TRUE" ;
VAL_ 1437 DTCI_UVM_TstFld 0 "FALSE" 1 "TRUE" ;
VAL_ 1437 DTCI_UVM_PndngDTC 0 "FALSE" 1 "TRUE" ;
VAL_ 1437 DTCI_UVM_DTCTriggered 0 "FALSE" 1 "TRUE" ;
VAL_ 1437 DTCI_UVM_WrnIndTrggrd 0 "FALSE" 1 "TRUE" ;
VAL_ 1437 DTCI_UVM_WrnIndRqd 0 "FALSE" 1 "TRUE" ;
VAL_ 1341 DTCI_VKM_CnfrmdDTC 0 "FALSE" 1 "TRUE" ;
VAL_ 1341 DTCI_VKM_DTCFaultType 0 "Not Supported" 1 "Type A" 2 "Type B" 3 "Type C" ;
VAL_ 1341 DTCI_VKM_TstNCmpltdOpCyc 0 "FALSE" 1 "TRUE" ;
VAL_ 1341 DTCI_VKM_TstNCmpltdLstClr 0 "FALSE" 1 "TRUE" ;
VAL_ 1341 DTCI_VKM_TstFldOpCyc 0 "FALSE" 1 "TRUE" ;
VAL_ 1341 DTCI_VKM_TstFldLstClr 0 "FALSE" 1 "TRUE" ;
VAL_ 1341 DTCI_VKM_TstFld 0 "FALSE" 1 "TRUE" ;
VAL_ 1341 DTCI_VKM_PndngDTC 0 "FALSE" 1 "TRUE" ;
VAL_ 1341 DTCI_VKM_DTCTriggered 0 "FALSE" 1 "TRUE" ;
VAL_ 1341 DTCI_VKM_WrnIndTrggrd 0 "FALSE" 1 "TRUE" ;
VAL_ 1341 DTCI_VKM_WrnIndRqd 0 "FALSE" 1 "TRUE" ;
VAL_ 1389 DTCI_VLM_CnfrmdDTC 0 "FALSE" 1 "TRUE" ;
VAL_ 1389 DTCI_VLM_DTCFaultType 0 "Not Supported" 1 "Type A" 2 "Type B" 3 "Type C" ;
VAL_ 1389 DTCI_VLM_TstNCmpltdOpCyc 0 "FALSE" 1 "TRUE" ;
VAL_ 1389 DTCI_VLM_TstNCmpltdLstClr 0 "FALSE" 1 "TRUE" ;
VAL_ 1389 DTCI_VLM_TstFldOpCyc 0 "FALSE" 1 "TRUE" ;
VAL_ 1389 DTCI_VLM_TstFldLstClr 0 "FALSE" 1 "TRUE" ;
VAL_ 1389 DTCI_VLM_TstFld 0 "FALSE" 1 "TRUE" ;
VAL_ 1389 DTCI_VLM_PndngDTC 0 "FALSE" 1 "TRUE" ;
VAL_ 1389 DTCI_VLM_DTCTriggered 0 "FALSE" 1 "TRUE" ;
VAL_ 1389 DTCI_VLM_WrnIndTrggrd 0 "FALSE" 1 "TRUE" ;
VAL_ 1389 DTCI_VLM_WrnIndRqd 0 "FALSE" 1 "TRUE" ;
VAL_ 1167 DTCI_VPM_CnfrmdDTC 0 "FALSE" 1 "TRUE" ;
VAL_ 1167 DTCI_VPM_DTCFaultType 0 "Not Supported" 1 "Type A" 2 "Type B" 3 "Type C" ;
VAL_ 1167 DTCI_VPM_TstNCmpltdOpCyc 0 "FALSE" 1 "TRUE" ;
VAL_ 1167 DTCI_VPM_TstNCmpltdLstClr 0 "FALSE" 1 "TRUE" ;
VAL_ 1167 DTCI_VPM_TstFldOpCyc 0 "FALSE" 1 "TRUE" ;
VAL_ 1167 DTCI_VPM_TstFldLstClr 0 "FALSE" 1 "TRUE" ;
VAL_ 1167 DTCI_VPM_TstFld 0 "FALSE" 1 "TRUE" ;
VAL_ 1167 DTCI_VPM_PndngDTC 0 "FALSE" 1 "TRUE" ;
VAL_ 1167 DTCI_VPM_DTCTriggered 0 "FALSE" 1 "TRUE" ;
VAL_ 1167 DTCI_VPM_WrnIndTrggrd 0 "FALSE" 1 "TRUE" ;
VAL_ 1167 DTCI_VPM_WrnIndRqd 0 "FALSE" 1 "TRUE" ;
